VERSION ""

NS_ :

BS_:

BU_: VCM FAS EBS APM

BO_ 2671902706 TesterFuncDiagMsg_C03: 8 VCM
 SG_ FuncDiagDataTester_ISig_3 : 0|64@1+ (1,0) [0|0] ""  APM,FAS

BO_ 2671902708 TesterFuncDiagMsgF4_C03: 8 VCM
 SG_ FuncDiagDataIntTesterF4_ISig_3 : 0|64@1+ (1,0) [0|0] ""  FAS,APM

BO_ 2671833648 PhysDiagRespMsg_F2_30_C03: 8 FAS
 SG_ PhysDiagRespSig_F2_30_ISig_3 : 0|64@1+ (1,0) [0|0] ""  VCM

BO_ 2671833635 PhysDiagRespMsg_F2_23_C03: 8 APM
 SG_ PhysDiagRespSig_F2_23_ISig_3 : 0|64@1+ (1,0) [0|0] ""  VCM

BO_ 2671784178 PhysDiagReqMsg_30_F2_C03: 8 VCM
 SG_ PhysDiagReqSig_30_F2_ISig_3 : 0|64@1+ (1,0) [0|0] ""  FAS

BO_ 2671780850 PhysDiagReqMsg_23_F2_C03: 8 VCM
 SG_ PhysDiagReqSig_23_F2_ISig_3 : 0|64@1+ (1,0) [0|0] ""  APM

BO_ 2633990180 NmAsr_VCM_C03: 1 VCM

BO_ 2633990192 NmAsr_FAS_C03: 1 FAS

BO_ 2633990184 NmAsr_EBS_C03: 1 EBS

BO_ 2633990179 NmAsr_APM_C03: 1 APM

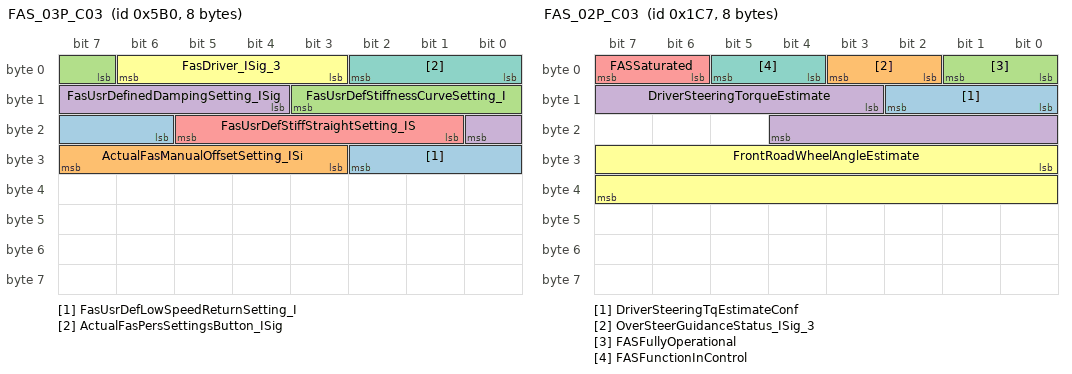
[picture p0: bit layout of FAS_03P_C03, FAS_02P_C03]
BO_ 1456 FAS_03P_C03: 8 FAS
 SG_ FasUsrDefLowSpeedReturnSetting_I : 22|5@1+ (1,-10) [-10|21] ""  VCM
 SG_ ActualFasManualOffsetSetting_ISi : 27|5@1+ (1,-10) [-10|21] ""  VCM
 SG_ FasUsrDefStiffnessCurveSetting_I : 7|5@1+ (1,-10) [-10|21] ""  VCM
 SG_ FasUsrDefinedDampingSetting_ISig : 12|5@1+ (1,-10) [-10|21] ""  VCM
 SG_ FasUsrDefStiffStraightSetting_IS : 17|5@1+ (1,-10) [-10|21] ""  VCM
 SG_ FasDriver_ISig_3 : 3|4@1+ (1,0) [0|0] ""  VCM
 SG_ ActualFasPersSettingsButton_ISig : 0|3@1+ (1,0) [0|0] ""  VCM

BO_ 455 FAS_02P_C03: 8 FAS
 SG_ DriverSteeringTqEstimateConf : 8|3@1+ (1,0) [0|0] ""  VCM
 SG_ OverSteerGuidanceStatus_ISig_3 : 2|2@1+ (1,0) [0|0] ""  VCM
 SG_ FASFullyOperational : 0|2@1+ (1,0) [0|0] ""  VCM
 SG_ DriverSteeringTorqueEstimate : 11|10@1+ (0.05,-25) [-25|26.15] "Nm"  VCM
 SG_ FASSaturated : 6|2@1+ (1,0) [0|0] ""  VCM
 SG_ FrontRoadWheelAngleEstimate : 24|16@1+ (5E-005,-1.6) [-1.6|1.67675] "rad"  VCM
 SG_ FASFunctionInControl : 4|2@1+ (1,0) [0|0] ""  VCM

BO_ 275 FAS_01P_C03: 16 FAS
 SG_ RoadWheelAngleResp_RateCap : 80|8@1+ (0.004,0) [0|1.02] "Rad_per_s"  VCM
 SG_ RoadWheelAngleResp_CRC : 48|8@1+ (1,0) [0|255] ""  VCM
 SG_ SteeringCtrlModeRsp_CRC : 24|8@1+ (1,0) [0|255] ""  VCM
 SG_ SteeringWheelTorque_SqC : 8|4@1+ (1,0) [0|14] "NotApplicable"  VCM
 SG_ SteeringWheelTorque_CRC : 0|8@1+ (1,0) [0|255] ""  VCM
 SG_ SteeringCtrlModeRsp_Status : 36|3@1+ (1,0) [0|0] ""  VCM
 SG_ SteeringCtrlModeRsp_SqC : 32|4@1+ (1,0) [0|14] "NotApplicable"  VCM
 SG_ RoadWheelAngleResp_Status : 64|16@1+ (5E-005,-1.6) [-1.6|1.67675] "rad"  VCM
 SG_ SteeringWheelTorque_Estimate : 14|10@1+ (0.05,-25) [-25|26.15] "Nm"  VCM
 SG_ SteeringCtrlModeRsp_Cap : 40|3@1+ (1,0) [0|0] ""  VCM
 SG_ RoadWheelAngleResp_MaxCap : 96|8@1+ (0.01,0) [0|2.55] "rad"  VCM
 SG_ SteeringCtrlModeRsp_Active : 43|2@1+ (1,0) [0|0] ""  VCM
 SG_ RoadWheelAngleResp_MinCap : 88|8@1+ (0.01,-1.6) [-1.6|0.95] "rad"  VCM
 SG_ RoadWheelAngleResp_SqC : 56|4@1+ (1,0) [0|14] "NotApplicable"  VCM

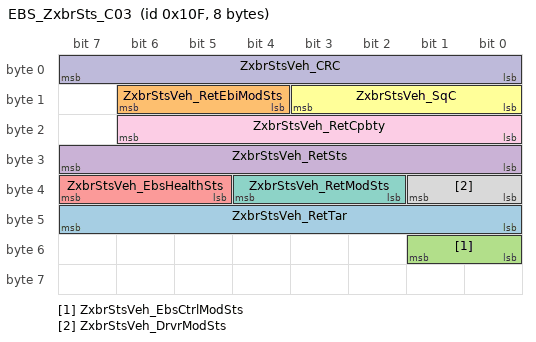
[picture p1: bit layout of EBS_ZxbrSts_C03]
BO_ 271 EBS_ZxbrSts_C03: 8 EBS
 SG_ ZxbrStsVeh_RetTar : 40|8@1+ (0.005,0) [0|1.275] "NotApplicable"  VCM
 SG_ ZxbrStsVeh_RetEbiModSts : 12|3@1+ (1,0) [0|0] ""  VCM
 SG_ ZxbrStsVeh_EbsCtrlModSts : 48|2@1+ (1,0) [0|0] ""  VCM
 SG_ ZxbrStsVeh_RetSts : 24|8@1+ (0.005,0) [0|1.275] "NotApplicable"  VCM
 SG_ ZxbrStsVeh_EbsHealthSts : 37|3@1+ (1,0) [0|0] ""  VCM
 SG_ ZxbrStsVeh_SqC : 8|4@1+ (1,0) [0|14] "NotApplicable"  VCM
 SG_ ZxbrStsVeh_RetModSts : 34|3@1+ (1,0) [0|0] ""  VCM
 SG_ ZxbrStsVeh_DrvrModSts : 32|2@1+ (1,0) [0|0] ""  VCM
 SG_ ZxbrStsVeh_RetCpbty : 16|7@1+ (0.01,0) [0|1.27] "NotApplicable"  VCM
 SG_ ZxbrStsVeh_CRC : 0|8@1+ (1,0) [0|255] ""  VCM

BO_ 304 EBS_Sts2Axles_C03: 64 EBS
 SG_ Sts2Axle2_WhlTqRi : 143|13@1+ (10,0) [0|81910] "Nm"  VCM
 SG_ Sts2Axle4_WhlTqQltyLe : 316|2@1+ (1,0) [0|0] ""  VCM
 SG_ Sts2Axle3_SqC : 176|8@1+ (1,0) [0|255] "Count"  VCM
 SG_ Sts2Axle6_WhlTqRi : 463|13@1+ (10,0) [0|81910] "Nm"  VCM
 SG_ Sts2Axle3_BrkTqReqRefLe : 184|13@1+ (10,0) [0|81910] "Nm"  VCM
 SG_ Sts2Axle2_WhlTqQltyRi : 158|2@1+ (1,0) [0|0] ""  VCM
 SG_ Sts2Axle1_SqC : 16|8@1+ (1,0) [0|255] "Count"  VCM
 SG_ Sts2Axle1_BrkTqReqRefLe : 24|13@1+ (10,0) [0|81910] "Nm"  VCM
 SG_ Sts2Axle2_WhlTqQltyLe : 156|2@1+ (1,0) [0|0] ""  VCM
 SG_ Sts2Axle4_BrkTqReqRefLe : 264|13@1+ (10,0) [0|81910] "Nm"  VCM
 SG_ Sts2Axle2_SqC : 96|8@1+ (1,0) [0|255] "Count"  VCM
 SG_ Sts2Axle4_CRC : 240|16@1+ (1,0) [0|65535] "NotApplicable"  VCM
 SG_ Sts2Axle3_WhlTqQltyLe : 236|2@1+ (1,0) [0|0] ""  VCM
 SG_ Sts2Axle1_WhlTqQltyRi : 78|2@1+ (1,0) [0|0] ""  VCM
 SG_ Sts2Axle1_WhlTqLe : 50|13@1+ (10,0) [0|81910] "Nm"  VCM
 SG_ Sts2Axle4_SqC : 256|8@1+ (1,0) [0|255] "Count"  VCM
 SG_ Sts2Axle4_WhlTqQltyRi : 318|2@1+ (1,0) [0|0] ""  VCM
 SG_ Sts2Axle3_BrkTqReqRefRi : 197|13@1+ (10,0) [0|81910] "Nm"  VCM
 SG_ Sts2Axle6_SqC : 416|8@1+ (1,0) [0|255] "Count"  VCM
 SG_ Sts2Axle6_CRC : 400|16@1+ (1,0) [0|65535] "NotApplicable"  VCM
 SG_ Sts2Axle5_BrkTqReqRefLe : 344|13@1+ (10,0) [0|81910] "Nm"  VCM
 SG_ Sts2Axle6_WhlTqQltyLe : 476|2@1+ (1,0) [0|0] ""  VCM
 SG_ Sts2Axle2_WhlTqLe : 130|13@1+ (10,0) [0|81910] "Nm"  VCM
 SG_ Sts2Axle5_WhlTqQltyRi : 398|2@1+ (1,0) [0|0] ""  VCM
 SG_ Sts2Axle3_CRC : 160|16@1+ (1,0) [0|65535] "NotApplicable"  VCM
 SG_ Sts2Axle6_BrkTqReqRefRi : 437|13@1+ (10,0) [0|81910] "Nm"  VCM
 SG_ Sts2Axle1_WhlTqRi : 63|13@1+ (10,0) [0|81910] "Nm"  VCM
 SG_ Sts2Axle4_BrkTqReqRefRi : 277|13@1+ (10,0) [0|81910] "Nm"  VCM
 SG_ Sts2Axle1_BrkTqReqRefRi : 37|13@1+ (10,0) [0|81910] "Nm"  VCM
 SG_ Sts2Axle2_BrkTqReqRefLe : 104|13@1+ (10,0) [0|81910] "Nm"  VCM
 SG_ Sts2Axle5_SqC : 336|8@1+ (1,0) [0|255] "Count"  VCM
 SG_ Sts2Axle3_WhlTqLe : 210|13@1+ (10,0) [0|81910] "Nm"  VCM
 SG_ Sts2Axle6_WhlTqQltyRi : 478|2@1+ (1,0) [0|0] ""  VCM
 SG_ Sts2Axle5_WhlTqRi : 383|13@1+ (10,0) [0|81910] "Nm"  VCM
 SG_ Sts2Axle5_WhlTqLe : 370|13@1+ (10,0) [0|81910] "Nm"  VCM
 SG_ Sts2Axle5_WhlTqQltyLe : 396|2@1+ (1,0) [0|0] ""  VCM
 SG_ Sts2Axle1_WhlTqQltyLe : 76|2@1+ (1,0) [0|0] ""  VCM
 SG_ Sts2Axle6_WhlTqLe : 450|13@1+ (10,0) [0|81910] "Nm"  VCM
 SG_ Sts2Axle4_WhlTqRi : 303|13@1+ (10,0) [0|81910] "Nm"  VCM
 SG_ Sts2Axle1_CRC : 0|16@1+ (1,0) [0|65535] "NotApplicable"  VCM
 SG_ Sts2Axle5_CRC : 320|16@1+ (1,0) [0|65535] "NotApplicable"  VCM
 SG_ Sts2Axle3_WhlTqRi : 223|13@1+ (10,0) [0|81910] "Nm"  VCM
 SG_ Sts2Axle6_BrkTqReqRefLe : 424|13@1+ (10,0) [0|81910] "Nm"  VCM
 SG_ Sts2Axle2_BrkTqReqRefRi : 117|13@1+ (10,0) [0|81910] "Nm"  VCM
 SG_ Sts2Axle2_CRC : 80|16@1+ (1,0) [0|65535] "NotApplicable"  VCM
 SG_ Sts2Axle3_WhlTqQltyRi : 238|2@1+ (1,0) [0|0] ""  VCM
 SG_ Sts2Axle4_WhlTqLe : 290|13@1+ (10,0) [0|81910] "Nm"  VCM
 SG_ Sts2Axle5_BrkTqReqRefRi : 357|13@1+ (10,0) [0|81910] "Nm"  VCM

BO_ 288 EBS_Sts1Axles_C03: 48 EBS
 SG_ Sts1Axle6_WhlRotQltyLe : 332|2@1+ (1,0) [0|0] ""  VCM
 SG_ Sts1Axle5_CRC : 256|8@1+ (1,0) [0|255] ""  VCM
 SG_ Sts1Axle2_WhlRotQltyRi : 78|2@1+ (1,0) [0|0] ""  VCM
 SG_ Sts1Axle2_WhlRotSpdRi : 104|15@1+ (0.01,-140) [-140|187.67] "Rad_per_s"  VCM
 SG_ Sts1Axle6_CRC : 320|8@1+ (1,0) [0|255] ""  VCM
 SG_ Sts1Axle5_WhlRotAgCntrRi : 311|9@1+ (1,0) [0|511] "Count"  VCM
 SG_ Sts1Axle3_CRC : 128|8@1+ (1,0) [0|255] ""  VCM
 SG_ Sts1Axle4_WhlRotSpdLe : 208|15@1+ (0.01,-140) [-140|187.67] "Rad_per_s"  VCM
 SG_ Sts1Axle4_WhlRotAgCntrLe : 223|9@1+ (1,0) [0|511] "Count"  VCM
 SG_ Sts1Axle6_WhlRotSpdRi : 360|15@1+ (0.01,-140) [-140|187.67] "Rad_per_s"  VCM
 SG_ Sts1Axle3_WhlRotAgCntrLe : 159|9@1+ (1,0) [0|511] "Count"  VCM
 SG_ Sts1Axle2_CRC : 64|8@1+ (1,0) [0|255] ""  VCM
 SG_ Sts1Axle1_WhlRotSpdRi : 40|15@1+ (0.01,-140) [-140|187.67] "Rad_per_s"  VCM
 SG_ Sts1Axle1_WhlRotQltyRi : 14|2@1+ (1,0) [0|0] ""  VCM
 SG_ Sts1Axle3_WhlRotQltyLe : 140|2@1+ (1,0) [0|0] ""  VCM
 SG_ Sts1Axle5_WhlRotAgCntrLe : 287|9@1+ (1,0) [0|511] "Count"  VCM
 SG_ Sts1Axle3_SqC : 136|4@1+ (1,0) [0|14] "NotApplicable"  VCM
 SG_ Sts1Axle4_SqC : 200|4@1+ (1,0) [0|14] "NotApplicable"  VCM
 SG_ Sts1Axle1_SqC : 8|4@1+ (1,0) [0|14] "NotApplicable"  VCM
 SG_ Sts1Axle5_SqC : 264|4@1+ (1,0) [0|14] "NotApplicable"  VCM
 SG_ Sts1Axle2_WhlRotSpdLe : 80|15@1+ (0.01,-140) [-140|187.67] "Rad_per_s"  VCM
 SG_ Sts1Axle1_WhlRotQltyLe : 12|2@1+ (1,0) [0|0] ""  VCM
 SG_ Sts1Axle3_WhlRotAgCntrRi : 183|9@1+ (1,0) [0|511] "Count"  VCM
 SG_ Sts1Axle1_WhlRotAgCntrLe : 31|9@1+ (1,0) [0|511] "Count"  VCM
 SG_ Sts1Axle1_CRC : 0|8@1+ (1,0) [0|255] ""  VCM
 SG_ Sts1Axle6_WhlRotAgCntrLe : 351|9@1+ (1,0) [0|511] "Count"  VCM
 SG_ Sts1Axle5_WhlRotQltyLe : 268|2@1+ (1,0) [0|0] ""  VCM
 SG_ Sts1Axle5_WhlRotQltyRi : 270|2@1+ (1,0) [0|0] ""  VCM
 SG_ Sts1Axle1_WhlRotSpdLe : 16|15@1+ (0.01,-140) [-140|187.67] "Rad_per_s"  VCM
 SG_ Sts1Axle2_WhlRotAgCntrRi : 119|9@1+ (1,0) [0|511] "Count"  VCM
 SG_ Sts1Axle4_WhlRotQltyRi : 206|2@1+ (1,0) [0|0] ""  VCM
 SG_ Sts1Axle2_WhlRotAgCntrLe : 95|9@1+ (1,0) [0|511] "Count"  VCM
 SG_ Sts1Axle3_WhlRotQltyRi : 142|2@1+ (1,0) [0|0] ""  VCM
 SG_ Sts1Axle6_WhlRotAgCntrRi : 375|9@1+ (1,0) [0|511] "Count"  VCM
 SG_ Sts1Axle5_WhlRotSpdRi : 296|15@1+ (0.01,-140) [-140|187.67] "Rad_per_s"  VCM
 SG_ Sts1Axle4_CRC : 192|8@1+ (1,0) [0|255] ""  VCM
 SG_ Sts1Axle1_WhlRotAgCntrRi : 55|9@1+ (1,0) [0|511] "Count"  VCM
 SG_ Sts1Axle5_WhlRotSpdLe : 272|15@1+ (0.01,-140) [-140|187.67] "Rad_per_s"  VCM
 SG_ Sts1Axle3_WhlRotSpdLe : 144|15@1+ (0.01,-140) [-140|187.67] "Rad_per_s"  VCM
 SG_ Sts1Axle4_WhlRotSpdRi : 232|15@1+ (0.01,-140) [-140|187.67] "Rad_per_s"  VCM
 SG_ Sts1Axle4_WhlRotQltyLe : 204|2@1+ (1,0) [0|0] ""  VCM
 SG_ Sts1Axle2_WhlRotQltyLe : 76|2@1+ (1,0) [0|0] ""  VCM
 SG_ Sts1Axle6_WhlRotSpdLe : 336|15@1+ (0.01,-140) [-140|187.67] "Rad_per_s"  VCM
 SG_ Sts1Axle4_WhlRotAgCntrRi : 247|9@1+ (1,0) [0|511] "Count"  VCM
 SG_ Sts1Axle6_WhlRotQltyRi : 334|2@1+ (1,0) [0|0] ""  VCM
 SG_ Sts1Axle2_SqC : 72|4@1+ (1,0) [0|14] "NotApplicable"  VCM
 SG_ Sts1Axle3_WhlRotSpdRi : 168|15@1+ (0.01,-140) [-140|187.67] "Rad_per_s"  VCM
 SG_ Sts1Axle6_SqC : 328|4@1+ (1,0) [0|14] "NotApplicable"  VCM

BO_ 602 EBS_IxbrStsVeh_C03: 16 EBS
 SG_ IxbrSts2Veh_CRC : 56|8@1+ (1,0) [0|255] ""  VCM
 SG_ IxbrSts1Veh_AbsSts : 45|3@1+ (1,0) [0|0] ""  VCM
 SG_ IxbrSts1Veh_IxbrModSts : 12|3@1+ (1,0) [0|0] ""  VCM
 SG_ IxbrSts2Veh_SqC : 64|4@1+ (1,0) [0|14] "NotApplicable"  VCM
 SG_ IxbrSts1Veh_VehSpdLimRsc : 16|13@1+ (0.01,-40) [-40|41.91] "m_per_s"  VCM
 SG_ IxbrSts2Veh_YawRateRefEsc : 68|12@1+ (0.001,-2) [-2|2.095] "Rad_per_s"  VCM
 SG_ IxbrSts2Veh_VehAccnLatLimNeg : 96|9@1+ (0.01,-5) [-5|0.11] "m_per_s_squared"  VCM
 SG_ IxbrSts1Veh_VehSpdLgt : 32|13@1+ (0.01,-40) [-40|41.91] "m_per_s"  VCM
 SG_ IxbrSts1Veh_EscSts : 29|3@1+ (1,0) [0|0] ""  VCM
 SG_ IxbrSts2Veh_YawRateOffsLim : 80|12@1+ (0.001,-2) [-2|2.095] "Rad_per_s"  VCM
 SG_ IxbrSts1Veh_TscSts : 48|3@1+ (1,0) [0|0] ""  VCM
 SG_ IxbrSts1Veh_CRC : 0|8@1+ (1,0) [0|255] ""  VCM
 SG_ IxbrSts2Veh_VehAccnLatLimPos : 111|9@1+ (0.01,0) [0|5.11] "m_per_s_squared"  VCM
 SG_ IxbrSts1Veh_SqC : 8|4@1+ (1,0) [0|14] "NotApplicable"  VCM
 SG_ IxbrSts1Veh_RscSts : 51|3@1+ (1,0) [0|0] ""  VCM

BO_ 598 EBS_IxbrStsAx456_C03: 64 EBS
 SG_ IxbrSts3Ax5_WhlAccnLgtLimMinLe : 279|9@1+ (0.05,-20) [-20|5.55] "Rad_per_s_squared"  VCM
 SG_ IxbrSts3Ax5_CRC : 240|8@1+ (1,0) [0|255] ""  VCM
 SG_ IxbrSts3Ax5_SqC : 248|4@1+ (1,0) [0|14] "NotApplicable"  VCM
 SG_ IxbrSts1Ax6_CRC : 304|8@1+ (1,0) [0|255] ""  VCM
 SG_ IxbrSts2Ax6_WhlSlipLimPrpnRi : 384|8@1+ (0.005,0) [0|1.275] "NotApplicable"  VCM
 SG_ IxbrSts2Ax6_WhlSlipLimBrkngLe : 360|8@1+ (0.005,-1) [-1|0.275] "NotApplicable"  VCM
 SG_ IxbrSts3Ax6_WhlAccnLgtLimMaxRi : 416|9@1+ (0.05,0) [0|25.55] "Rad_per_s_squared"  VCM
 SG_ IxbrSts1Ax4_WhlRdEstmdLe : 30|10@1+ (0.001,0.35) [0.35|1.373] "m"  VCM
 SG_ IxbrSts2Ax5_WhlSlipLimBrkngLe : 208|8@1+ (0.005,-1) [-1|0.275] "NotApplicable"  VCM
 SG_ IxbrSts2Ax6_WhlSlipLimBrkngRi : 368|8@1+ (0.005,-1) [-1|0.275] "NotApplicable"  VCM
 SG_ IxbrSts2Ax4_SqC : 48|4@1+ (1,0) [0|14] "NotApplicable"  VCM
 SG_ IxbrSts3Ax4_CRC : 88|8@1+ (1,0) [0|255] ""  VCM
 SG_ IxbrSts2Ax4_WhlSlipLimBrkngRi : 64|8@1+ (0.005,-1) [-1|0.275] "NotApplicable"  VCM
 SG_ IxbrSts2Ax4_WhlSlipLimBrkngLe : 56|8@1+ (0.005,-1) [-1|0.275] "NotApplicable"  VCM
 SG_ IxbrSts2Ax6_CRC : 344|8@1+ (1,0) [0|255] ""  VCM
 SG_ IxbrSts2Ax4_CRC : 40|8@1+ (1,0) [0|255] ""  VCM
 SG_ IxbrSts3Ax4_WhlAccnLgtLimMinLe : 127|9@1+ (0.05,-20) [-20|5.55] "Rad_per_s_squared"  VCM
 SG_ IxbrSts3Ax6_CRC : 392|8@1+ (1,0) [0|255] ""  VCM
 SG_ IxbrSts1Ax4_SqC : 8|4@1+ (1,0) [0|14] "NotApplicable"  VCM
 SG_ IxbrSts1Ax6_SqC : 312|4@1+ (1,0) [0|14] "NotApplicable"  VCM
 SG_ IxbrSts3Ax5_WhlAccnLgtLimMinRi : 288|9@1+ (0.05,-20) [-20|5.55] "Rad_per_s_squared"  VCM
 SG_ IxbrSts2Ax6_WhlSlipLimPrpnLe : 376|8@1+ (0.005,0) [0|1.275] "NotApplicable"  VCM
 SG_ IxbrSts2Ax5_SqC : 200|4@1+ (1,0) [0|14] "NotApplicable"  VCM
 SG_ IxbrSts3Ax6_SqC : 400|4@1+ (1,0) [0|14] "NotApplicable"  VCM
 SG_ IxbrSts2Ax5_WhlSlipLimBrkngRi : 216|8@1+ (0.005,-1) [-1|0.275] "NotApplicable"  VCM
 SG_ IxbrSts1Ax5_CRC : 152|8@1+ (1,0) [0|255] ""  VCM
 SG_ IxbrSts3Ax5_WhlAccnLgtLimMaxRi : 264|9@1+ (0.05,0) [0|25.55] "Rad_per_s_squared"  VCM
 SG_ IxbrSts1Ax6_WhlRdEstmdLe : 334|10@1+ (0.001,0.35) [0.35|1.373] "m"  VCM
 SG_ IxbrSts3Ax6_WhlAccnLgtLimMinLe : 431|9@1+ (0.05,-20) [-20|5.55] "Rad_per_s_squared"  VCM
 SG_ IxbrSts2Ax5_WhlSlipLimPrpnRi : 232|8@1+ (0.005,0) [0|1.275] "NotApplicable"  VCM
 SG_ IxbrSts2Ax6_SqC : 352|4@1+ (1,0) [0|14] "NotApplicable"  VCM
 SG_ IxbrSts3Ax4_WhlAccnLgtLimMinRi : 136|9@1+ (0.05,-20) [-20|5.55] "Rad_per_s_squared"  VCM
 SG_ IxbrSts1Ax5_SqC : 160|4@1+ (1,0) [0|14] "NotApplicable"  VCM
 SG_ IxbrSts3Ax6_WhlAccnLgtLimMinRi : 440|9@1+ (0.05,-20) [-20|5.55] "Rad_per_s_squared"  VCM
 SG_ IxbrSts2Ax5_CRC : 192|8@1+ (1,0) [0|255] ""  VCM
 SG_ IxbrSts3Ax4_SqC : 96|4@1+ (1,0) [0|14] "NotApplicable"  VCM
 SG_ IxbrSts3Ax6_WhlAccnLgtLimMaxLe : 407|9@1+ (0.05,0) [0|25.55] "Rad_per_s_squared"  VCM
 SG_ IxbrSts3Ax4_WhlAccnLgtLimMaxLe : 103|9@1+ (0.05,0) [0|25.55] "Rad_per_s_squared"  VCM
 SG_ IxbrSts1Ax6_WhlRdEstmdRi : 320|10@1+ (0.001,0.35) [0.35|1.373] "m"  VCM
 SG_ IxbrSts1Ax4_WhlRdEstmdRi : 16|10@1+ (0.001,0.35) [0.35|1.373] "m"  VCM
 SG_ IxbrSts3Ax4_WhlAccnLgtLimMaxRi : 112|9@1+ (0.05,0) [0|25.55] "Rad_per_s_squared"  VCM
 SG_ IxbrSts2Ax4_WhlSlipLimPrpnRi : 80|8@1+ (0.005,0) [0|1.275] "NotApplicable"  VCM
 SG_ IxbrSts1Ax5_WhlRdEstmdLe : 182|10@1+ (0.001,0.35) [0.35|1.373] "m"  VCM
 SG_ IxbrSts2Ax4_WhlSlipLimPrpnLe : 72|8@1+ (0.005,0) [0|1.275] "NotApplicable"  VCM
 SG_ IxbrSts3Ax5_WhlAccnLgtLimMaxLe : 255|9@1+ (0.05,0) [0|25.55] "Rad_per_s_squared"  VCM
 SG_ IxbrSts2Ax5_WhlSlipLimPrpnLe : 224|8@1+ (0.005,0) [0|1.275] "NotApplicable"  VCM
 SG_ IxbrSts1Ax4_CRC : 0|8@1+ (1,0) [0|255] ""  VCM
 SG_ IxbrSts1Ax5_WhlRdEstmdRi : 168|10@1+ (0.001,0.35) [0.35|1.373] "m"  VCM

BO_ 596 EBS_IxbrStsAx123_C03: 64 EBS
 SG_ IxbrSts1Ax1_WhlRdEstmdRi : 16|10@1+ (0.001,0.35) [0.35|1.373] "m"  VCM
 SG_ IxbrSts3Ax3_WhlAccnLgtLimMaxLe : 407|9@1+ (0.05,0) [0|25.55] "Rad_per_s_squared"  VCM
 SG_ IxbrSts3Ax1_WhlAccnLgtLimMinRi : 136|9@1+ (0.05,-20) [-20|5.55] "Rad_per_s_squared"  VCM
 SG_ IxbrSts3Ax3_CRC : 392|8@1+ (1,0) [0|255] ""  VCM
 SG_ IxbrSts2Ax3_WhlSlipLimBrkngRi : 368|8@1+ (0.005,-1) [-1|0.275] "NotApplicable"  VCM
 SG_ IxbrSts3Ax1_CRC : 88|8@1+ (1,0) [0|255] ""  VCM
 SG_ IxbrSts2Ax3_WhlSlipLimPrpnRi : 384|8@1+ (0.005,0) [0|1.275] "NotApplicable"  VCM
 SG_ IxbrSts2Ax1_WhlSlipLimPrpnLe : 72|8@1+ (0.005,0) [0|1.275] "NotApplicable"  VCM
 SG_ IxbrSts3Ax3_WhlAccnLgtLimMinLe : 431|9@1+ (0.05,-20) [-20|5.55] "Rad_per_s_squared"  VCM
 SG_ IxbrSts1Ax1_SqC : 8|4@1+ (1,0) [0|14] "NotApplicable"  VCM
 SG_ IxbrSts2Ax3_CRC : 344|8@1+ (1,0) [0|255] ""  VCM
 SG_ IxbrSts1Ax2_WhlRdEstmdLe : 182|10@1+ (0.001,0.35) [0.35|1.373] "m"  VCM
 SG_ IxbrSts1Ax1_CRC : 0|8@1+ (1,0) [0|255] ""  VCM
 SG_ IxbrSts1Ax3_SqC : 312|4@1+ (1,0) [0|14] "NotApplicable"  VCM
 SG_ IxbrSts1Ax3_WhlRdEstmdLe : 334|10@1+ (0.001,0.35) [0.35|1.373] "m"  VCM
 SG_ IxbrSts2Ax2_CRC : 192|8@1+ (1,0) [0|255] ""  VCM
 SG_ IxbrSts2Ax2_WhlSlipLimBrkngRi : 216|8@1+ (0.005,-1) [-1|0.275] "NotApplicable"  VCM
 SG_ IxbrSts2Ax1_WhlSlipLimPrpnRi : 80|8@1+ (0.005,0) [0|1.275] "NotApplicable"  VCM
 SG_ IxbrSts3Ax1_WhlAccnLgtLimMinLe : 127|9@1+ (0.05,-20) [-20|5.55] "Rad_per_s_squared"  VCM
 SG_ IxbrSts3Ax2_WhlAccnLgtLimMaxRi : 264|9@1+ (0.05,0) [0|25.55] "Rad_per_s_squared"  VCM
 SG_ IxbrSts3Ax2_WhlAccnLgtLimMinLe : 279|9@1+ (0.05,-20) [-20|5.55] "Rad_per_s_squared"  VCM
 SG_ IxbrSts2Ax2_WhlSlipLimBrkngLe : 208|8@1+ (0.005,-1) [-1|0.275] "NotApplicable"  VCM
 SG_ IxbrSts3Ax1_WhlAccnLgtLimMaxLe : 103|9@1+ (0.05,0) [0|25.55] "Rad_per_s_squared"  VCM
 SG_ IxbrSts1Ax1_WhlRdEstmdLe : 30|10@1+ (0.001,0.35) [0.35|1.373] "m"  VCM
 SG_ IxbrSts2Ax1_WhlSlipLimBrkngLe : 56|8@1+ (0.005,-1) [-1|0.275] "NotApplicable"  VCM
 SG_ IxbrSts3Ax3_SqC : 400|4@1+ (1,0) [0|14] "NotApplicable"  VCM
 SG_ IxbrSts3Ax1_SqC : 96|4@1+ (1,0) [0|14] "NotApplicable"  VCM
 SG_ IxbrSts3Ax1_WhlAccnLgtLimMaxRi : 112|9@1+ (0.05,0) [0|25.55] "Rad_per_s_squared"  VCM
 SG_ IxbrSts2Ax3_SqC : 352|4@1+ (1,0) [0|14] "NotApplicable"  VCM
 SG_ IxbrSts1Ax2_CRC : 152|8@1+ (1,0) [0|255] ""  VCM
 SG_ IxbrSts1Ax3_CRC : 304|8@1+ (1,0) [0|255] ""  VCM
 SG_ IxbrSts2Ax1_SqC : 48|4@1+ (1,0) [0|14] "NotApplicable"  VCM
 SG_ IxbrSts3Ax3_WhlAccnLgtLimMinRi : 440|9@1+ (0.05,-20) [-20|5.55] "Rad_per_s_squared"  VCM
 SG_ IxbrSts3Ax2_SqC : 248|4@1+ (1,0) [0|14] "NotApplicable"  VCM
 SG_ IxbrSts1Ax2_WhlRdEstmdRi : 168|10@1+ (0.001,0.35) [0.35|1.373] "m"  VCM
 SG_ IxbrSts1Ax2_SqC : 160|4@1+ (1,0) [0|14] "NotApplicable"  VCM
 SG_ IxbrSts2Ax3_WhlSlipLimBrkngLe : 360|8@1+ (0.005,-1) [-1|0.275] "NotApplicable"  VCM
 SG_ IxbrSts3Ax2_WhlAccnLgtLimMinRi : 288|9@1+ (0.05,-20) [-20|5.55] "Rad_per_s_squared"  VCM
 SG_ IxbrSts3Ax2_CRC : 240|8@1+ (1,0) [0|255] ""  VCM
 SG_ IxbrSts2Ax3_WhlSlipLimPrpnLe : 376|8@1+ (0.005,0) [0|1.275] "NotApplicable"  VCM
 SG_ IxbrSts2Ax2_WhlSlipLimPrpnLe : 224|8@1+ (0.005,0) [0|1.275] "NotApplicable"  VCM
 SG_ IxbrSts2Ax1_CRC : 40|8@1+ (1,0) [0|255] ""  VCM
 SG_ IxbrSts3Ax2_WhlAccnLgtLimMaxLe : 255|9@1+ (0.05,0) [0|25.55] "Rad_per_s_squared"  VCM
 SG_ IxbrSts3Ax3_WhlAccnLgtLimMaxRi : 416|9@1+ (0.05,0) [0|25.55] "Rad_per_s_squared"  VCM
 SG_ IxbrSts1Ax3_WhlRdEstmdRi : 320|10@1+ (0.001,0.35) [0.35|1.373] "m"  VCM
 SG_ IxbrSts2Ax1_WhlSlipLimBrkngRi : 64|8@1+ (0.005,-1) [-1|0.275] "NotApplicable"  VCM
 SG_ IxbrSts2Ax2_SqC : 200|4@1+ (1,0) [0|14] "NotApplicable"  VCM
 SG_ IxbrSts2Ax2_WhlSlipLimPrpnRi : 232|8@1+ (0.005,0) [0|1.275] "NotApplicable"  VCM

BO_ 298 EBS_ImuSts_C03: 16 EBS
 SG_ Imu_LgtAccnQlty : 122|2@1+ (1,0) [0|0] ""  VCM
 SG_ Imu_AccnLat : 48|16@1+ (0.004882813,-156.875) [-156.875|163.120149955] "m_per_s_squared"  VCM
 SG_ Imu_PitchRate : 96|16@1+ (0.000175,-5.6224) [-5.6224|5.846225] "NotApplicable"  VCM
 SG_ Imu_YawRate : 16|16@1+ (0.000175,-5.6224) [-5.6224|5.846225] "NotApplicable"  VCM
 SG_ Imu_Temp : 112|8@1+ (1,-50) [-50|205] "DegreeC"  VCM
 SG_ Imu_RollRate : 80|16@1+ (0.000175,-5.6224) [-5.6224|5.846225] "NotApplicable"  VCM
 SG_ Imu_YawRateQlty : 14|2@1+ (1,0) [0|0] ""  VCM
 SG_ Imu_PitchRateQlty : 124|2@1+ (1,0) [0|0] ""  VCM
 SG_ Imu_RollRateQlty : 126|2@1+ (1,0) [0|0] ""  VCM
 SG_ Imu_LgtAccn : 64|16@1+ (0.004882813,-156.875) [-156.875|163.120149955] "m_per_s_squared"  VCM
 SG_ Imu_SqC : 8|4@1+ (1,0) [0|14] "NotApplicable"  VCM
 SG_ Imu_CRC : 0|8@1+ (1,0) [0|255] ""  VCM
 SG_ Imu_AccnLatQlty : 12|2@1+ (1,0) [0|0] ""  VCM
 SG_ Imu_AccnVertQlty : 120|2@1+ (1,0) [0|0] ""  VCM
 SG_ Imu_AccnVert : 32|16@1+ (0.004882813,-156.875) [-156.875|163.120149955] "m_per_s_squared"  VCM

BO_ 594 EBS_CpbtyAxle456_C03: 64 EBS
 SG_ CpbtyAxle5_BrkEgyCpctyLe : 288|8@1+ (150,0) [0|38250] "NotApplicable"  VCM
 SG_ CpbtyAxle4_TqCpbtyRateQltyLe : 132|2@1+ (1,0) [0|0] ""  VCM
 SG_ CpbtyAxle4_TqCpbtyRateDecRi : 64|8@1+ (1000,0) [0|255000] "NotApplicable"  VCM
 SG_ CpbtyAxle4_BrkEgyCpctyQltyRi : 38|2@1+ (1,0) [0|0] ""  VCM
 SG_ CpbtyAxle4_TqCpbtyMinRi : 100|10@1+ (50,0) [0|51150] "Nm"  VCM
 SG_ CpbtyAxle5_TqCpbtyMaxLe : 262|10@1+ (50,0) [0|51150] "Nm"  VCM
 SG_ CpbtyAxle5_TqCpbtyQltyLe : 250|2@1+ (1,0) [0|0] ""  VCM
 SG_ CpbtyAxle5_PadWearRi : 232|8@1+ (0.5,0) [0|127.5] "Percent"  VCM
 SG_ CpbtyAxle5_TqCpbtyRateIncLeRi : 200|8@1+ (1000,0) [0|255000] "NotApplicable"  VCM
 SG_ CpbtyAxle6_TqCpbtyRateQltyLe : 436|2@1+ (1,0) [0|0] ""  VCM
 SG_ CpbtyAxle5_TqCpbtyRateDecLe : 192|8@1+ (1000,0) [0|255000] "NotApplicable"  VCM
 SG_ CpbtyAxle6_TqCpbtyMinRi : 404|10@1+ (50,0) [0|51150] "Nm"  VCM
 SG_ CpbtyAxle6_BrkEgyCpctyRi : 328|8@1+ (150,0) [0|38250] "NotApplicable"  VCM
 SG_ CpbtyAxle6_TqCpbtyRateQltyRi : 438|2@1+ (1,0) [0|0] ""  VCM
 SG_ CpbtyAxle6_TqCpbtyRateIncLeRi : 352|8@1+ (1000,0) [0|255000] "NotApplicable"  VCM
 SG_ CpbtyAxle5_TqCpbtyMaxRi : 274|10@1+ (50,0) [0|51150] "Nm"  VCM
 SG_ CpbtyAxle5_CRC : 152|16@1+ (1,0) [0|65535] "NotApplicable"  VCM
 SG_ CpbtyAxle6_TqCpbtyRateDecLe : 344|8@1+ (1000,0) [0|255000] "NotApplicable"  VCM
 SG_ CpbtyAxle5_SlipCtrlEna : 296|2@1+ (1,0) [0|0] ""  VCM
 SG_ CpbtyAxle5_PadWearQltyLe : 184|2@1+ (1,0) [0|0] ""  VCM
 SG_ CpbtyAxle6_BrkEgyCpctyQltyRi : 342|2@1+ (1,0) [0|0] ""  VCM
 SG_ CpbtyAxle5_BrkEgyCpctyQltyLe : 188|2@1+ (1,0) [0|0] ""  VCM
 SG_ CpbtyAxle6_PadWearQltyRi : 338|2@1+ (1,0) [0|0] ""  VCM
 SG_ CpbtyAxle6_TqCpbtyMaxRi : 426|10@1+ (50,0) [0|51150] "Nm"  VCM
 SG_ CpbtyAxle4_TqCpbtyQltyLe : 98|2@1+ (1,0) [0|0] ""  VCM
 SG_ CpbtyAxle4_SlipCtrlEna : 144|2@1+ (1,0) [0|0] ""  VCM
 SG_ CpbtyAxle4_BrkEgyCpctyRi : 24|8@1+ (150,0) [0|38250] "NotApplicable"  VCM
 SG_ CpbtyAxle6_TqCpbtyQltyRi : 424|2@1+ (1,0) [0|0] ""  VCM
 SG_ CpbtyAxle6_CRC : 304|16@1+ (1,0) [0|65535] "NotApplicable"  VCM
 SG_ CpbtyAxle5_TqCpbtyRateQltyLe : 284|2@1+ (1,0) [0|0] ""  VCM
 SG_ CpbtyAxle4_TqCpbtyMaxLe : 110|10@1+ (50,0) [0|51150] "Nm"  VCM
 SG_ CpbtyAxle4_PadWearRi : 80|8@1+ (0.5,0) [0|127.5] "Percent"  VCM
 SG_ CpbtyAxle6_TqCpbtyMinLe : 392|10@1+ (50,0) [0|51150] "Nm"  VCM
 SG_ CpbtyAxle4_CRC : 0|16@1+ (1,0) [0|65535] "NotApplicable"  VCM
 SG_ CpbtyAxle4_SqC : 16|8@1+ (1,0) [0|255] "Count"  VCM
 SG_ CpbtyAxle5_TqCpbtyMinLe : 240|10@1+ (50,0) [0|51150] "Nm"  VCM
 SG_ CpbtyAxle6_PadWearQltyLe : 336|2@1+ (1,0) [0|0] ""  VCM
 SG_ CpbtyAxle6_PadWearRi : 384|8@1+ (0.5,0) [0|127.5] "Percent"  VCM
 SG_ CpbtyAxle5_TqCpbtyRateQltyRi : 286|2@1+ (1,0) [0|0] ""  VCM
 SG_ CpbtyAxle4_TqCpbtyQltyRi : 120|2@1+ (1,0) [0|0] ""  VCM
 SG_ CpbtyAxle6_SlipCtrlEna : 448|2@1+ (1,0) [0|0] ""  VCM
 SG_ CpbtyAxle5_TqCpbtyQltyRi : 272|2@1+ (1,0) [0|0] ""  VCM
 SG_ CpbtyAxle4_BrkEgyCpctyQltyLe : 36|2@1+ (1,0) [0|0] ""  VCM
 SG_ CpbtyAxle4_TqCpbtyMinLe : 88|10@1+ (50,0) [0|51150] "Nm"  VCM
 SG_ CpbtyAxle5_TqCpbtyMinRi : 252|10@1+ (50,0) [0|51150] "Nm"  VCM
 SG_ CpbtyAxle6_SqC : 320|8@1+ (1,0) [0|255] "Count"  VCM
 SG_ CpbtyAxle6_TqCpbtyRateDecRi : 368|8@1+ (1000,0) [0|255000] "NotApplicable"  VCM
 SG_ CpbtyAxle6_TqCpbtyRateIncLeLe : 360|8@1+ (1000,0) [0|255000] "NotApplicable"  VCM
 SG_ CpbtyAxle4_TqCpbtyRateDecLe : 40|8@1+ (1000,0) [0|255000] "NotApplicable"  VCM
 SG_ CpbtyAxle4_TqCpbtyRateQltyRi : 134|2@1+ (1,0) [0|0] ""  VCM
 SG_ CpbtyAxle4_BrkEgyCpctyLe : 136|8@1+ (150,0) [0|38250] "NotApplicable"  VCM
 SG_ CpbtyAxle4_TqCpbtyMaxRi : 122|10@1+ (50,0) [0|51150] "Nm"  VCM
 SG_ CpbtyAxle6_TqCpbtyMaxLe : 414|10@1+ (50,0) [0|51150] "Nm"  VCM
 SG_ CpbtyAxle5_TqCpbtyRateIncLeLe : 208|8@1+ (1000,0) [0|255000] "NotApplicable"  VCM
 SG_ CpbtyAxle5_PadWearQltyRi : 186|2@1+ (1,0) [0|0] ""  VCM
 SG_ CpbtyAxle6_BrkEgyCpctyQltyLe : 340|2@1+ (1,0) [0|0] ""  VCM
 SG_ CpbtyAxle5_TqCpbtyRateDecRi : 216|8@1+ (1000,0) [0|255000] "NotApplicable"  VCM
 SG_ CpbtyAxle6_TqCpbtyQltyLe : 402|2@1+ (1,0) [0|0] ""  VCM
 SG_ CpbtyAxle5_SqC : 168|8@1+ (1,0) [0|255] "Count"  VCM
 SG_ CpbtyAxle4_TqCpbtyRateIncLeRi : 48|8@1+ (1000,0) [0|255000] "NotApplicable"  VCM
 SG_ CpbtyAxle6_BrkEgyCpctyLe : 440|8@1+ (150,0) [0|38250] "NotApplicable"  VCM
 SG_ CpbtyAxle5_BrkEgyCpctyRi : 176|8@1+ (150,0) [0|38250] "NotApplicable"  VCM
 SG_ CpbtyAxle5_BrkEgyCpctyQltyRi : 190|2@1+ (1,0) [0|0] ""  VCM
 SG_ CpbtyAxle6_PadWearLe : 376|8@1+ (0.5,0) [0|127.5] "Percent"  VCM
 SG_ CpbtyAxle4_PadWearLe : 72|8@1+ (0.5,0) [0|127.5] "Percent"  VCM
 SG_ CpbtyAxle4_PadWearQltyRi : 34|2@1+ (1,0) [0|0] ""  VCM
 SG_ CpbtyAxle4_TqCpbtyRateIncLeLe : 56|8@1+ (1000,0) [0|255000] "NotApplicable"  VCM
 SG_ CpbtyAxle5_PadWearLe : 224|8@1+ (0.5,0) [0|127.5] "Percent"  VCM
 SG_ CpbtyAxle4_PadWearQltyLe : 32|2@1+ (1,0) [0|0] ""  VCM

BA_DEF_ BO_  "GenMsgStartDelayTime" INT 0 0;
BA_DEF_ BO_  "GenMsgDelayTime" INT 0 0;
BA_DEF_ BO_  "GenMsgCycleTime" INT 0 0;
BA_DEF_ BO_  "GenMsgSendType" ENUM  "Cyclic","NotUsed","NotUsed","NotUsed","NotUsed","NotUsed","NotUsed","IfActive","NoMsgSendType","NotUsed";
BA_DEF_ SG_  "GenSigStartValue" INT 0 0;
BA_DEF_ SG_  "GenSigCycleTimeActive" INT 0 0;
BA_DEF_ SG_  "GenSigCycleTime" INT 0 0;
BA_DEF_ SG_  "GenSigSendType" ENUM  "Cyclic","OnWrite","OnWriteWithRepetition","OnChange","OnChangeWithRepetition","IfActive","IfActiveWithRepetition","NoSigSendType","NotUsed","NotUsed","NotUsed","NotUsed","NotUsed";
BA_DEF_ BO_  "VFrameFormat" ENUM  "StandardCAN","ExtendedCAN","reserved","J1939PG","reserved","reserved","reserved","reserved","reserved","reserved","reserved","reserved","reserved","reserved","StandardCAN_FD","ExtendedCAN_FD";
BA_DEF_ SG_  "SigType" ENUM  "Default","Range","RangeSigned","ASCII","Discrete","Control","ReferencePGN","DTC","StringDelimiter","StringLength","StringLengthControl";
BA_DEF_ BO_  "NmAsrMessage" ENUM  "No","Yes";
BA_DEF_ SG_  "NeedsUpdateBit" ENUM  "No","Yes";
BA_DEF_ SG_  "MmAnSignal" ENUM  "No","Yes";
BA_DEF_ SG_  "GenSigMaxLatency" INT 0 65535;
BA_DEF_ SG_  "GenSigILSupport" ENUM  "Yes","No";
BA_DEF_ BO_  "GenMsgILSupport" ENUM  "No","Yes";
BA_DEF_ SG_  "E2EProfile" STRING ;
BA_DEF_ SG_  "E2EDataLength" INT 0 65535;
BA_DEF_ SG_  "E2EDataId" INT 0 65535;
BA_DEF_ BO_  "DiagUUDTResponse" ENUM  "No","Yes";
BA_DEF_ BO_  "DiagState" ENUM  "No","Yes";
BA_DEF_ BO_  "DiagResponse" ENUM  "No","Yes";
BA_DEF_ BO_  "DiagRequest" ENUM  "No","Yes";
BA_DEF_ BO_  "DiagConnection" HEX 0 65535;
BA_DEF_ BO_  "CanTpFcFrameId" HEX 0 2147483647;
BA_DEF_ BO_  "CanTpBs" INT 0 255;
BA_DEF_ BO_  "CANFD_BRS" ENUM  "0","1";
BA_DEF_ SG_  "SystemSignalLongSymbol" STRING ;
BA_DEF_REL_ BU_SG_REL_  "GenSigTimeoutTime" INT 0 65535;
BA_DEF_REL_ BU_SG_REL_  "GenSigFirstTimeoutTime" INT 0 65535;
BA_DEF_DEF_  "GenMsgStartDelayTime" 0;
BA_DEF_DEF_  "GenMsgDelayTime" 0;
BA_DEF_DEF_  "GenMsgCycleTime" 0;
BA_DEF_DEF_  "GenMsgSendType" "Cyclic";
BA_DEF_DEF_  "GenSigStartValue" 0;
BA_DEF_DEF_  "GenSigCycleTimeActive" 0;
BA_DEF_DEF_  "GenSigCycleTime" 0;
BA_DEF_DEF_  "GenSigSendType" "Cyclic";
BA_DEF_DEF_  "VFrameFormat" "ExtendedCAN";
BA_DEF_DEF_  "SigType" "Default";
BA_DEF_DEF_  "NmAsrMessage" "No";
BA_DEF_DEF_  "NeedsUpdateBit" "No";
BA_DEF_DEF_  "MmAnSignal" "No";
BA_DEF_DEF_  "GenSigMaxLatency" 0;
BA_DEF_DEF_  "GenSigILSupport" "Yes";
BA_DEF_DEF_  "GenMsgILSupport" "Yes";
BA_DEF_DEF_  "E2EProfile" "none";
BA_DEF_DEF_  "E2EDataLength" 0;
BA_DEF_DEF_  "E2EDataId" 0;
BA_DEF_DEF_  "DiagUUDTResponse" "No";
BA_DEF_DEF_  "DiagState" "No";
BA_DEF_DEF_  "DiagResponse" "No";
BA_DEF_DEF_  "DiagRequest" "No";
BA_DEF_DEF_  "DiagConnection" 0;
BA_DEF_DEF_  "CanTpFcFrameId" 2147483647;
BA_DEF_DEF_  "CanTpBs" 255;
BA_DEF_DEF_  "CANFD_BRS" "0";
BA_DEF_DEF_REL_ "GenSigTimeoutTime" 0;
BA_DEF_DEF_REL_ "GenSigFirstTimeoutTime" 0;
BA_DEF_DEF_  "SystemSignalLongSymbol" "";
BA_ "DiagConnection" BO_ 2671902706 62000;
BA_ "DiagState" BO_ 2671902706 1;
BA_ "GenMsgILSupport" BO_ 2671902706 0;
BA_ "GenMsgSendType" BO_ 2671902706 8;
BA_ "DiagConnection" BO_ 2671902708 62719;
BA_ "DiagState" BO_ 2671902708 1;
BA_ "GenMsgILSupport" BO_ 2671902708 0;
BA_ "GenMsgSendType" BO_ 2671902708 8;
BA_ "DiagConnection" BO_ 2671833648 62000;
BA_ "DiagResponse" BO_ 2671833648 1;
BA_ "GenMsgILSupport" BO_ 2671833648 0;
BA_ "GenMsgSendType" BO_ 2671833648 8;
BA_ "DiagConnection" BO_ 2671833635 61987;
BA_ "DiagResponse" BO_ 2671833635 1;
BA_ "GenMsgILSupport" BO_ 2671833635 0;
BA_ "GenMsgSendType" BO_ 2671833635 8;
BA_ "DiagConnection" BO_ 2671784178 62000;
BA_ "DiagRequest" BO_ 2671784178 1;
BA_ "GenMsgILSupport" BO_ 2671784178 0;
BA_ "GenMsgSendType" BO_ 2671784178 8;
BA_ "DiagConnection" BO_ 2671780850 61987;
BA_ "DiagRequest" BO_ 2671780850 1;
BA_ "GenMsgILSupport" BO_ 2671780850 0;
BA_ "GenMsgSendType" BO_ 2671780850 8;
BA_ "CANFD_BRS" BO_ 2633990180 1;
BA_ "GenMsgILSupport" BO_ 2633990180 0;
BA_ "NmAsrMessage" BO_ 2633990180 1;
BA_ "GenMsgSendType" BO_ 2633990180 8;
BA_ "VFrameFormat" BO_ 2633990180 15;
BA_ "CANFD_BRS" BO_ 2633990192 1;
BA_ "GenMsgILSupport" BO_ 2633990192 0;
BA_ "NmAsrMessage" BO_ 2633990192 1;
BA_ "GenMsgSendType" BO_ 2633990192 8;
BA_ "VFrameFormat" BO_ 2633990192 15;
BA_ "CANFD_BRS" BO_ 2633990184 1;
BA_ "GenMsgILSupport" BO_ 2633990184 0;
BA_ "NmAsrMessage" BO_ 2633990184 1;
BA_ "GenMsgSendType" BO_ 2633990184 8;
BA_ "VFrameFormat" BO_ 2633990184 15;
BA_ "CANFD_BRS" BO_ 2633990179 1;
BA_ "GenMsgILSupport" BO_ 2633990179 0;
BA_ "NmAsrMessage" BO_ 2633990179 1;
BA_ "GenMsgSendType" BO_ 2633990179 8;
BA_ "VFrameFormat" BO_ 2633990179 15;
BA_ "CANFD_BRS" BO_ 1456 1;
BA_ "GenMsgCycleTime" BO_ 1456 1000;
BA_ "GenMsgStartDelayTime" BO_ 1456 125;
BA_ "VFrameFormat" BO_ 1456 14;
BA_ "CANFD_BRS" BO_ 455 1;
BA_ "GenMsgCycleTime" BO_ 455 20;
BA_ "GenMsgStartDelayTime" BO_ 455 5;
BA_ "VFrameFormat" BO_ 455 14;
BA_ "CANFD_BRS" BO_ 275 1;
BA_ "GenMsgCycleTime" BO_ 275 10;
BA_ "VFrameFormat" BO_ 275 14;
BA_ "CANFD_BRS" BO_ 271 1;
BA_ "GenMsgCycleTime" BO_ 271 10;
BA_ "VFrameFormat" BO_ 271 14;
BA_ "CANFD_BRS" BO_ 304 1;
BA_ "GenMsgCycleTime" BO_ 304 10;
BA_ "GenMsgStartDelayTime" BO_ 304 5;
BA_ "VFrameFormat" BO_ 304 14;
BA_ "CANFD_BRS" BO_ 288 1;
BA_ "GenMsgCycleTime" BO_ 288 10;
BA_ "VFrameFormat" BO_ 288 14;
BA_ "CANFD_BRS" BO_ 602 1;
BA_ "GenMsgCycleTime" BO_ 602 50;
BA_ "VFrameFormat" BO_ 602 14;
BA_ "CANFD_BRS" BO_ 598 1;
BA_ "GenMsgCycleTime" BO_ 598 50;
BA_ "GenMsgStartDelayTime" BO_ 598 30;
BA_ "VFrameFormat" BO_ 598 14;
BA_ "CANFD_BRS" BO_ 596 1;
BA_ "GenMsgCycleTime" BO_ 596 50;
BA_ "GenMsgStartDelayTime" BO_ 596 25;
BA_ "VFrameFormat" BO_ 596 14;
BA_ "CANFD_BRS" BO_ 298 1;
BA_ "GenMsgCycleTime" BO_ 298 10;
BA_ "VFrameFormat" BO_ 298 14;
BA_ "CANFD_BRS" BO_ 594 1;
BA_ "GenMsgCycleTime" BO_ 594 50;
BA_ "GenMsgStartDelayTime" BO_ 594 15;
BA_ "VFrameFormat" BO_ 594 14;
BA_ "GenSigSendType" SG_ 2671902706 FuncDiagDataTester_ISig_3 7;
BA_ "GenSigSendType" SG_ 2671902708 FuncDiagDataIntTesterF4_ISig_3 7;
BA_ "GenSigSendType" SG_ 2671833648 PhysDiagRespSig_F2_30_ISig_3 7;
BA_ "GenSigSendType" SG_ 2671833635 PhysDiagRespSig_F2_23_ISig_3 7;
BA_ "GenSigSendType" SG_ 2671784178 PhysDiagReqSig_30_F2_ISig_3 7;
BA_ "GenSigSendType" SG_ 2671780850 PhysDiagReqSig_23_F2_ISig_3 7;
BA_ "GenSigCycleTime" SG_ 1456 FasUsrDefLowSpeedReturnSetting_I 100;
BA_ "GenSigCycleTimeActive" SG_ 1456 FasUsrDefLowSpeedReturnSetting_I 100;
BA_ "GenSigStartValue" SG_ 1456 FasUsrDefLowSpeedReturnSetting_I 31;
BA_ "SystemSignalLongSymbol" SG_ 1456 FasUsrDefLowSpeedReturnSetting_I "FasUsrDefLowSpeedReturnSetting_ISig_3";
BA_ "GenSigCycleTime" SG_ 1456 ActualFasManualOffsetSetting_ISi 100;
BA_ "GenSigCycleTimeActive" SG_ 1456 ActualFasManualOffsetSetting_ISi 100;
BA_ "GenSigStartValue" SG_ 1456 ActualFasManualOffsetSetting_ISi 31;
BA_ "SystemSignalLongSymbol" SG_ 1456 ActualFasManualOffsetSetting_ISi "ActualFasManualOffsetSetting_ISig_3";
BA_ "GenSigCycleTime" SG_ 1456 FasUsrDefStiffnessCurveSetting_I 100;
BA_ "GenSigCycleTimeActive" SG_ 1456 FasUsrDefStiffnessCurveSetting_I 100;
BA_ "GenSigStartValue" SG_ 1456 FasUsrDefStiffnessCurveSetting_I 31;
BA_ "SystemSignalLongSymbol" SG_ 1456 FasUsrDefStiffnessCurveSetting_I "FasUsrDefStiffnessCurveSetting_ISig_3";
BA_ "GenSigCycleTime" SG_ 1456 FasUsrDefinedDampingSetting_ISig 100;
BA_ "GenSigCycleTimeActive" SG_ 1456 FasUsrDefinedDampingSetting_ISig 100;
BA_ "GenSigStartValue" SG_ 1456 FasUsrDefinedDampingSetting_ISig 31;
BA_ "SystemSignalLongSymbol" SG_ 1456 FasUsrDefinedDampingSetting_ISig "FasUsrDefinedDampingSetting_ISig_3";
BA_ "GenSigCycleTime" SG_ 1456 FasUsrDefStiffStraightSetting_IS 100;
BA_ "GenSigCycleTimeActive" SG_ 1456 FasUsrDefStiffStraightSetting_IS 100;
BA_ "GenSigStartValue" SG_ 1456 FasUsrDefStiffStraightSetting_IS 31;
BA_ "SystemSignalLongSymbol" SG_ 1456 FasUsrDefStiffStraightSetting_IS "FasUsrDefStiffStraightSetting_ISig_3";
BA_ "GenSigCycleTime" SG_ 1456 FasDriver_ISig_3 100;
BA_ "GenSigCycleTimeActive" SG_ 1456 FasDriver_ISig_3 100;
BA_ "GenSigStartValue" SG_ 1456 FasDriver_ISig_3 15;
BA_ "GenSigCycleTime" SG_ 1456 ActualFasPersSettingsButton_ISig 100;
BA_ "GenSigCycleTimeActive" SG_ 1456 ActualFasPersSettingsButton_ISig 100;
BA_ "GenSigStartValue" SG_ 1456 ActualFasPersSettingsButton_ISig 7;
BA_ "SystemSignalLongSymbol" SG_ 1456 ActualFasPersSettingsButton_ISig "ActualFasPersSettingsButton_ISig_3";
BA_ "GenSigCycleTime" SG_ 455 DriverSteeringTqEstimateConf 100;
BA_ "GenSigCycleTimeActive" SG_ 455 DriverSteeringTqEstimateConf 100;
BA_ "GenSigStartValue" SG_ 455 DriverSteeringTqEstimateConf 7;
BA_ "GenSigCycleTime" SG_ 455 OverSteerGuidanceStatus_ISig_3 100;
BA_ "GenSigCycleTimeActive" SG_ 455 OverSteerGuidanceStatus_ISig_3 100;
BA_ "GenSigStartValue" SG_ 455 OverSteerGuidanceStatus_ISig_3 3;
BA_ "GenSigCycleTime" SG_ 455 FASFullyOperational 100;
BA_ "GenSigCycleTimeActive" SG_ 455 FASFullyOperational 100;
BA_ "GenSigStartValue" SG_ 455 FASFullyOperational 3;
BA_ "GenSigCycleTime" SG_ 455 DriverSteeringTorqueEstimate 100;
BA_ "GenSigCycleTimeActive" SG_ 455 DriverSteeringTorqueEstimate 100;
BA_ "GenSigStartValue" SG_ 455 DriverSteeringTorqueEstimate 1023;
BA_ "GenSigCycleTime" SG_ 455 FASSaturated 100;
BA_ "GenSigCycleTimeActive" SG_ 455 FASSaturated 100;
BA_ "GenSigStartValue" SG_ 455 FASSaturated 3;
BA_ "GenSigCycleTime" SG_ 455 FrontRoadWheelAngleEstimate 100;
BA_ "GenSigCycleTimeActive" SG_ 455 FrontRoadWheelAngleEstimate 100;
BA_ "GenSigStartValue" SG_ 455 FrontRoadWheelAngleEstimate 65535;
BA_ "GenSigCycleTime" SG_ 455 FASFunctionInControl 100;
BA_ "GenSigCycleTimeActive" SG_ 455 FASFunctionInControl 100;
BA_ "GenSigStartValue" SG_ 455 FASFunctionInControl 3;
BA_ "GenSigCycleTime" SG_ 275 RoadWheelAngleResp_RateCap 100;
BA_ "GenSigCycleTimeActive" SG_ 275 RoadWheelAngleResp_RateCap 100;
BA_ "GenSigStartValue" SG_ 275 RoadWheelAngleResp_RateCap 255;
BA_ "GenSigCycleTime" SG_ 275 RoadWheelAngleResp_CRC 100;
BA_ "GenSigCycleTimeActive" SG_ 275 RoadWheelAngleResp_CRC 100;
BA_ "GenSigStartValue" SG_ 275 RoadWheelAngleResp_CRC 255;
BA_ "E2EDataId" SG_ 275 RoadWheelAngleResp_CRC 199;
BA_ "E2EDataLength" SG_ 275 RoadWheelAngleResp_CRC 56;
BA_ "E2EProfile" SG_ 275 RoadWheelAngleResp_CRC "P01";
BA_ "GenSigCycleTime" SG_ 275 SteeringCtrlModeRsp_CRC 100;
BA_ "GenSigCycleTimeActive" SG_ 275 SteeringCtrlModeRsp_CRC 100;
BA_ "GenSigStartValue" SG_ 275 SteeringCtrlModeRsp_CRC 255;
BA_ "E2EDataId" SG_ 275 SteeringCtrlModeRsp_CRC 200;
BA_ "E2EDataLength" SG_ 275 SteeringCtrlModeRsp_CRC 24;
BA_ "E2EProfile" SG_ 275 SteeringCtrlModeRsp_CRC "P01";
BA_ "GenSigCycleTime" SG_ 275 SteeringWheelTorque_SqC 100;
BA_ "GenSigCycleTimeActive" SG_ 275 SteeringWheelTorque_SqC 100;
BA_ "GenSigStartValue" SG_ 275 SteeringWheelTorque_SqC 14;
BA_ "GenSigCycleTime" SG_ 275 SteeringWheelTorque_CRC 100;
BA_ "GenSigCycleTimeActive" SG_ 275 SteeringWheelTorque_CRC 100;
BA_ "GenSigStartValue" SG_ 275 SteeringWheelTorque_CRC 255;
BA_ "E2EDataId" SG_ 275 SteeringWheelTorque_CRC 201;
BA_ "E2EDataLength" SG_ 275 SteeringWheelTorque_CRC 24;
BA_ "E2EProfile" SG_ 275 SteeringWheelTorque_CRC "P01";
BA_ "GenSigCycleTime" SG_ 275 SteeringCtrlModeRsp_Status 100;
BA_ "GenSigCycleTimeActive" SG_ 275 SteeringCtrlModeRsp_Status 100;
BA_ "GenSigStartValue" SG_ 275 SteeringCtrlModeRsp_Status 7;
BA_ "GenSigCycleTime" SG_ 275 SteeringCtrlModeRsp_SqC 100;
BA_ "GenSigCycleTimeActive" SG_ 275 SteeringCtrlModeRsp_SqC 100;
BA_ "GenSigStartValue" SG_ 275 SteeringCtrlModeRsp_SqC 14;
BA_ "GenSigCycleTime" SG_ 275 RoadWheelAngleResp_Status 100;
BA_ "GenSigCycleTimeActive" SG_ 275 RoadWheelAngleResp_Status 100;
BA_ "GenSigStartValue" SG_ 275 RoadWheelAngleResp_Status 65535;
BA_ "GenSigCycleTime" SG_ 275 SteeringWheelTorque_Estimate 100;
BA_ "GenSigCycleTimeActive" SG_ 275 SteeringWheelTorque_Estimate 100;
BA_ "GenSigStartValue" SG_ 275 SteeringWheelTorque_Estimate 1023;
BA_ "GenSigCycleTime" SG_ 275 SteeringCtrlModeRsp_Cap 100;
BA_ "GenSigCycleTimeActive" SG_ 275 SteeringCtrlModeRsp_Cap 100;
BA_ "GenSigStartValue" SG_ 275 SteeringCtrlModeRsp_Cap 7;
BA_ "GenSigCycleTime" SG_ 275 RoadWheelAngleResp_MaxCap 100;
BA_ "GenSigCycleTimeActive" SG_ 275 RoadWheelAngleResp_MaxCap 100;
BA_ "GenSigStartValue" SG_ 275 RoadWheelAngleResp_MaxCap 255;
BA_ "GenSigCycleTime" SG_ 275 SteeringCtrlModeRsp_Active 100;
BA_ "GenSigCycleTimeActive" SG_ 275 SteeringCtrlModeRsp_Active 100;
BA_ "GenSigStartValue" SG_ 275 SteeringCtrlModeRsp_Active 3;
BA_ "GenSigCycleTime" SG_ 275 RoadWheelAngleResp_MinCap 100;
BA_ "GenSigCycleTimeActive" SG_ 275 RoadWheelAngleResp_MinCap 100;
BA_ "GenSigStartValue" SG_ 275 RoadWheelAngleResp_MinCap 255;
BA_ "GenSigCycleTime" SG_ 275 RoadWheelAngleResp_SqC 100;
BA_ "GenSigCycleTimeActive" SG_ 275 RoadWheelAngleResp_SqC 100;
BA_ "GenSigStartValue" SG_ 275 RoadWheelAngleResp_SqC 14;
BA_ "GenSigCycleTime" SG_ 271 ZxbrStsVeh_RetTar 100;
BA_ "GenSigCycleTimeActive" SG_ 271 ZxbrStsVeh_RetTar 100;
BA_ "GenSigStartValue" SG_ 271 ZxbrStsVeh_RetTar 255;
BA_ "GenSigCycleTime" SG_ 271 ZxbrStsVeh_RetEbiModSts 100;
BA_ "GenSigCycleTimeActive" SG_ 271 ZxbrStsVeh_RetEbiModSts 100;
BA_ "GenSigStartValue" SG_ 271 ZxbrStsVeh_RetEbiModSts 7;
BA_ "GenSigCycleTime" SG_ 271 ZxbrStsVeh_EbsCtrlModSts 100;
BA_ "GenSigCycleTimeActive" SG_ 271 ZxbrStsVeh_EbsCtrlModSts 100;
BA_ "GenSigStartValue" SG_ 271 ZxbrStsVeh_EbsCtrlModSts 3;
BA_ "GenSigCycleTime" SG_ 271 ZxbrStsVeh_RetSts 100;
BA_ "GenSigCycleTimeActive" SG_ 271 ZxbrStsVeh_RetSts 100;
BA_ "GenSigStartValue" SG_ 271 ZxbrStsVeh_RetSts 255;
BA_ "GenSigCycleTime" SG_ 271 ZxbrStsVeh_EbsHealthSts 100;
BA_ "GenSigCycleTimeActive" SG_ 271 ZxbrStsVeh_EbsHealthSts 100;
BA_ "GenSigStartValue" SG_ 271 ZxbrStsVeh_EbsHealthSts 7;
BA_ "GenSigCycleTime" SG_ 271 ZxbrStsVeh_SqC 100;
BA_ "GenSigCycleTimeActive" SG_ 271 ZxbrStsVeh_SqC 100;
BA_ "GenSigStartValue" SG_ 271 ZxbrStsVeh_SqC 14;
BA_ "GenSigCycleTime" SG_ 271 ZxbrStsVeh_RetModSts 100;
BA_ "GenSigCycleTimeActive" SG_ 271 ZxbrStsVeh_RetModSts 100;
BA_ "GenSigStartValue" SG_ 271 ZxbrStsVeh_RetModSts 7;
BA_ "GenSigCycleTime" SG_ 271 ZxbrStsVeh_DrvrModSts 100;
BA_ "GenSigCycleTimeActive" SG_ 271 ZxbrStsVeh_DrvrModSts 100;
BA_ "GenSigStartValue" SG_ 271 ZxbrStsVeh_DrvrModSts 3;
BA_ "GenSigCycleTime" SG_ 271 ZxbrStsVeh_RetCpbty 100;
BA_ "GenSigCycleTimeActive" SG_ 271 ZxbrStsVeh_RetCpbty 100;
BA_ "GenSigStartValue" SG_ 271 ZxbrStsVeh_RetCpbty 127;
BA_ "GenSigCycleTime" SG_ 271 ZxbrStsVeh_CRC 100;
BA_ "GenSigCycleTimeActive" SG_ 271 ZxbrStsVeh_CRC 100;
BA_ "GenSigStartValue" SG_ 271 ZxbrStsVeh_CRC 255;
BA_ "E2EDataId" SG_ 271 ZxbrStsVeh_CRC 242;
BA_ "E2EDataLength" SG_ 271 ZxbrStsVeh_CRC 56;
BA_ "E2EProfile" SG_ 271 ZxbrStsVeh_CRC "P01";
BA_ "GenSigCycleTime" SG_ 304 Sts2Axle2_WhlTqRi 100;
BA_ "GenSigCycleTimeActive" SG_ 304 Sts2Axle2_WhlTqRi 100;
BA_ "GenSigStartValue" SG_ 304 Sts2Axle2_WhlTqRi 8191;
BA_ "GenSigCycleTime" SG_ 304 Sts2Axle4_WhlTqQltyLe 100;
BA_ "GenSigCycleTimeActive" SG_ 304 Sts2Axle4_WhlTqQltyLe 100;
BA_ "GenSigStartValue" SG_ 304 Sts2Axle4_WhlTqQltyLe 3;
BA_ "GenSigCycleTime" SG_ 304 Sts2Axle3_SqC 100;
BA_ "GenSigCycleTimeActive" SG_ 304 Sts2Axle3_SqC 100;
BA_ "GenSigStartValue" SG_ 304 Sts2Axle3_SqC 255;
BA_ "GenSigCycleTime" SG_ 304 Sts2Axle6_WhlTqRi 100;
BA_ "GenSigCycleTimeActive" SG_ 304 Sts2Axle6_WhlTqRi 100;
BA_ "GenSigStartValue" SG_ 304 Sts2Axle6_WhlTqRi 8191;
BA_ "GenSigCycleTime" SG_ 304 Sts2Axle3_BrkTqReqRefLe 100;
BA_ "GenSigCycleTimeActive" SG_ 304 Sts2Axle3_BrkTqReqRefLe 100;
BA_ "GenSigStartValue" SG_ 304 Sts2Axle3_BrkTqReqRefLe 8191;
BA_ "GenSigCycleTime" SG_ 304 Sts2Axle2_WhlTqQltyRi 100;
BA_ "GenSigCycleTimeActive" SG_ 304 Sts2Axle2_WhlTqQltyRi 100;
BA_ "GenSigStartValue" SG_ 304 Sts2Axle2_WhlTqQltyRi 3;
BA_ "GenSigCycleTime" SG_ 304 Sts2Axle1_SqC 100;
BA_ "GenSigCycleTimeActive" SG_ 304 Sts2Axle1_SqC 100;
BA_ "GenSigStartValue" SG_ 304 Sts2Axle1_SqC 255;
BA_ "GenSigCycleTime" SG_ 304 Sts2Axle1_BrkTqReqRefLe 100;
BA_ "GenSigCycleTimeActive" SG_ 304 Sts2Axle1_BrkTqReqRefLe 100;
BA_ "GenSigStartValue" SG_ 304 Sts2Axle1_BrkTqReqRefLe 8191;
BA_ "GenSigCycleTime" SG_ 304 Sts2Axle2_WhlTqQltyLe 100;
BA_ "GenSigCycleTimeActive" SG_ 304 Sts2Axle2_WhlTqQltyLe 100;
BA_ "GenSigStartValue" SG_ 304 Sts2Axle2_WhlTqQltyLe 3;
BA_ "GenSigCycleTime" SG_ 304 Sts2Axle4_BrkTqReqRefLe 100;
BA_ "GenSigCycleTimeActive" SG_ 304 Sts2Axle4_BrkTqReqRefLe 100;
BA_ "GenSigStartValue" SG_ 304 Sts2Axle4_BrkTqReqRefLe 8191;
BA_ "GenSigCycleTime" SG_ 304 Sts2Axle2_SqC 100;
BA_ "GenSigCycleTimeActive" SG_ 304 Sts2Axle2_SqC 100;
BA_ "GenSigStartValue" SG_ 304 Sts2Axle2_SqC 255;
BA_ "GenSigCycleTime" SG_ 304 Sts2Axle4_CRC 100;
BA_ "GenSigCycleTimeActive" SG_ 304 Sts2Axle4_CRC 100;
BA_ "GenSigStartValue" SG_ 304 Sts2Axle4_CRC 65535;
BA_ "E2EDataId" SG_ 304 Sts2Axle4_CRC 259;
BA_ "E2EDataLength" SG_ 304 Sts2Axle4_CRC 80;
BA_ "E2EProfile" SG_ 304 Sts2Axle4_CRC "P05";
BA_ "GenSigCycleTime" SG_ 304 Sts2Axle3_WhlTqQltyLe 100;
BA_ "GenSigCycleTimeActive" SG_ 304 Sts2Axle3_WhlTqQltyLe 100;
BA_ "GenSigStartValue" SG_ 304 Sts2Axle3_WhlTqQltyLe 3;
BA_ "GenSigCycleTime" SG_ 304 Sts2Axle1_WhlTqQltyRi 100;
BA_ "GenSigCycleTimeActive" SG_ 304 Sts2Axle1_WhlTqQltyRi 100;
BA_ "GenSigStartValue" SG_ 304 Sts2Axle1_WhlTqQltyRi 3;
BA_ "GenSigCycleTime" SG_ 304 Sts2Axle1_WhlTqLe 100;
BA_ "GenSigCycleTimeActive" SG_ 304 Sts2Axle1_WhlTqLe 100;
BA_ "GenSigStartValue" SG_ 304 Sts2Axle1_WhlTqLe 8191;
BA_ "GenSigCycleTime" SG_ 304 Sts2Axle4_SqC 100;
BA_ "GenSigCycleTimeActive" SG_ 304 Sts2Axle4_SqC 100;
BA_ "GenSigStartValue" SG_ 304 Sts2Axle4_SqC 255;
BA_ "GenSigCycleTime" SG_ 304 Sts2Axle4_WhlTqQltyRi 100;
BA_ "GenSigCycleTimeActive" SG_ 304 Sts2Axle4_WhlTqQltyRi 100;
BA_ "GenSigStartValue" SG_ 304 Sts2Axle4_WhlTqQltyRi 3;
BA_ "GenSigCycleTime" SG_ 304 Sts2Axle3_BrkTqReqRefRi 100;
BA_ "GenSigCycleTimeActive" SG_ 304 Sts2Axle3_BrkTqReqRefRi 100;
BA_ "GenSigStartValue" SG_ 304 Sts2Axle3_BrkTqReqRefRi 8191;
BA_ "GenSigCycleTime" SG_ 304 Sts2Axle6_SqC 100;
BA_ "GenSigCycleTimeActive" SG_ 304 Sts2Axle6_SqC 100;
BA_ "GenSigStartValue" SG_ 304 Sts2Axle6_SqC 255;
BA_ "GenSigCycleTime" SG_ 304 Sts2Axle6_CRC 100;
BA_ "GenSigCycleTimeActive" SG_ 304 Sts2Axle6_CRC 100;
BA_ "GenSigStartValue" SG_ 304 Sts2Axle6_CRC 65535;
BA_ "E2EDataId" SG_ 304 Sts2Axle6_CRC 261;
BA_ "E2EDataLength" SG_ 304 Sts2Axle6_CRC 80;
BA_ "E2EProfile" SG_ 304 Sts2Axle6_CRC "P05";
BA_ "GenSigCycleTime" SG_ 304 Sts2Axle5_BrkTqReqRefLe 100;
BA_ "GenSigCycleTimeActive" SG_ 304 Sts2Axle5_BrkTqReqRefLe 100;
BA_ "GenSigStartValue" SG_ 304 Sts2Axle5_BrkTqReqRefLe 8191;
BA_ "GenSigCycleTime" SG_ 304 Sts2Axle6_WhlTqQltyLe 100;
BA_ "GenSigCycleTimeActive" SG_ 304 Sts2Axle6_WhlTqQltyLe 100;
BA_ "GenSigStartValue" SG_ 304 Sts2Axle6_WhlTqQltyLe 3;
BA_ "GenSigCycleTime" SG_ 304 Sts2Axle2_WhlTqLe 100;
BA_ "GenSigCycleTimeActive" SG_ 304 Sts2Axle2_WhlTqLe 100;
BA_ "GenSigStartValue" SG_ 304 Sts2Axle2_WhlTqLe 8191;
BA_ "GenSigCycleTime" SG_ 304 Sts2Axle5_WhlTqQltyRi 100;
BA_ "GenSigCycleTimeActive" SG_ 304 Sts2Axle5_WhlTqQltyRi 100;
BA_ "GenSigStartValue" SG_ 304 Sts2Axle5_WhlTqQltyRi 3;
BA_ "GenSigCycleTime" SG_ 304 Sts2Axle3_CRC 100;
BA_ "GenSigCycleTimeActive" SG_ 304 Sts2Axle3_CRC 100;
BA_ "GenSigStartValue" SG_ 304 Sts2Axle3_CRC 65535;
BA_ "E2EDataId" SG_ 304 Sts2Axle3_CRC 258;
BA_ "E2EDataLength" SG_ 304 Sts2Axle3_CRC 80;
BA_ "E2EProfile" SG_ 304 Sts2Axle3_CRC "P05";
BA_ "GenSigCycleTime" SG_ 304 Sts2Axle6_BrkTqReqRefRi 100;
BA_ "GenSigCycleTimeActive" SG_ 304 Sts2Axle6_BrkTqReqRefRi 100;
BA_ "GenSigStartValue" SG_ 304 Sts2Axle6_BrkTqReqRefRi 8191;
BA_ "GenSigCycleTime" SG_ 304 Sts2Axle1_WhlTqRi 100;
BA_ "GenSigCycleTimeActive" SG_ 304 Sts2Axle1_WhlTqRi 100;
BA_ "GenSigStartValue" SG_ 304 Sts2Axle1_WhlTqRi 8191;
BA_ "GenSigCycleTime" SG_ 304 Sts2Axle4_BrkTqReqRefRi 100;
BA_ "GenSigCycleTimeActive" SG_ 304 Sts2Axle4_BrkTqReqRefRi 100;
BA_ "GenSigStartValue" SG_ 304 Sts2Axle4_BrkTqReqRefRi 8191;
BA_ "GenSigCycleTime" SG_ 304 Sts2Axle1_BrkTqReqRefRi 100;
BA_ "GenSigCycleTimeActive" SG_ 304 Sts2Axle1_BrkTqReqRefRi 100;
BA_ "GenSigStartValue" SG_ 304 Sts2Axle1_BrkTqReqRefRi 8191;
BA_ "GenSigCycleTime" SG_ 304 Sts2Axle2_BrkTqReqRefLe 100;
BA_ "GenSigCycleTimeActive" SG_ 304 Sts2Axle2_BrkTqReqRefLe 100;
BA_ "GenSigStartValue" SG_ 304 Sts2Axle2_BrkTqReqRefLe 8191;
BA_ "GenSigCycleTime" SG_ 304 Sts2Axle5_SqC 100;
BA_ "GenSigCycleTimeActive" SG_ 304 Sts2Axle5_SqC 100;
BA_ "GenSigStartValue" SG_ 304 Sts2Axle5_SqC 255;
BA_ "GenSigCycleTime" SG_ 304 Sts2Axle3_WhlTqLe 100;
BA_ "GenSigCycleTimeActive" SG_ 304 Sts2Axle3_WhlTqLe 100;
BA_ "GenSigStartValue" SG_ 304 Sts2Axle3_WhlTqLe 8191;
BA_ "GenSigCycleTime" SG_ 304 Sts2Axle6_WhlTqQltyRi 100;
BA_ "GenSigCycleTimeActive" SG_ 304 Sts2Axle6_WhlTqQltyRi 100;
BA_ "GenSigStartValue" SG_ 304 Sts2Axle6_WhlTqQltyRi 3;
BA_ "GenSigCycleTime" SG_ 304 Sts2Axle5_WhlTqRi 100;
BA_ "GenSigCycleTimeActive" SG_ 304 Sts2Axle5_WhlTqRi 100;
BA_ "GenSigStartValue" SG_ 304 Sts2Axle5_WhlTqRi 8191;
BA_ "GenSigCycleTime" SG_ 304 Sts2Axle5_WhlTqLe 100;
BA_ "GenSigCycleTimeActive" SG_ 304 Sts2Axle5_WhlTqLe 100;
BA_ "GenSigStartValue" SG_ 304 Sts2Axle5_WhlTqLe 8191;
BA_ "GenSigCycleTime" SG_ 304 Sts2Axle5_WhlTqQltyLe 100;
BA_ "GenSigCycleTimeActive" SG_ 304 Sts2Axle5_WhlTqQltyLe 100;
BA_ "GenSigStartValue" SG_ 304 Sts2Axle5_WhlTqQltyLe 3;
BA_ "GenSigCycleTime" SG_ 304 Sts2Axle1_WhlTqQltyLe 100;
BA_ "GenSigCycleTimeActive" SG_ 304 Sts2Axle1_WhlTqQltyLe 100;
BA_ "GenSigStartValue" SG_ 304 Sts2Axle1_WhlTqQltyLe 3;
BA_ "GenSigCycleTime" SG_ 304 Sts2Axle6_WhlTqLe 100;
BA_ "GenSigCycleTimeActive" SG_ 304 Sts2Axle6_WhlTqLe 100;
BA_ "GenSigStartValue" SG_ 304 Sts2Axle6_WhlTqLe 8191;
BA_ "GenSigCycleTime" SG_ 304 Sts2Axle4_WhlTqRi 100;
BA_ "GenSigCycleTimeActive" SG_ 304 Sts2Axle4_WhlTqRi 100;
BA_ "GenSigStartValue" SG_ 304 Sts2Axle4_WhlTqRi 8191;
BA_ "GenSigCycleTime" SG_ 304 Sts2Axle1_CRC 100;
BA_ "GenSigCycleTimeActive" SG_ 304 Sts2Axle1_CRC 100;
BA_ "GenSigStartValue" SG_ 304 Sts2Axle1_CRC 65535;
BA_ "E2EDataId" SG_ 304 Sts2Axle1_CRC 256;
BA_ "E2EDataLength" SG_ 304 Sts2Axle1_CRC 80;
BA_ "E2EProfile" SG_ 304 Sts2Axle1_CRC "P05";
BA_ "GenSigCycleTime" SG_ 304 Sts2Axle5_CRC 100;
BA_ "GenSigCycleTimeActive" SG_ 304 Sts2Axle5_CRC 100;
BA_ "GenSigStartValue" SG_ 304 Sts2Axle5_CRC 65535;
BA_ "E2EDataId" SG_ 304 Sts2Axle5_CRC 260;
BA_ "E2EDataLength" SG_ 304 Sts2Axle5_CRC 80;
BA_ "E2EProfile" SG_ 304 Sts2Axle5_CRC "P05";
BA_ "GenSigCycleTime" SG_ 304 Sts2Axle3_WhlTqRi 100;
BA_ "GenSigCycleTimeActive" SG_ 304 Sts2Axle3_WhlTqRi 100;
BA_ "GenSigStartValue" SG_ 304 Sts2Axle3_WhlTqRi 8191;
BA_ "GenSigCycleTime" SG_ 304 Sts2Axle6_BrkTqReqRefLe 100;
BA_ "GenSigCycleTimeActive" SG_ 304 Sts2Axle6_BrkTqReqRefLe 100;
BA_ "GenSigStartValue" SG_ 304 Sts2Axle6_BrkTqReqRefLe 8191;
BA_ "GenSigCycleTime" SG_ 304 Sts2Axle2_BrkTqReqRefRi 100;
BA_ "GenSigCycleTimeActive" SG_ 304 Sts2Axle2_BrkTqReqRefRi 100;
BA_ "GenSigStartValue" SG_ 304 Sts2Axle2_BrkTqReqRefRi 8191;
BA_ "GenSigCycleTime" SG_ 304 Sts2Axle2_CRC 100;
BA_ "GenSigCycleTimeActive" SG_ 304 Sts2Axle2_CRC 100;
BA_ "GenSigStartValue" SG_ 304 Sts2Axle2_CRC 65535;
BA_ "E2EDataId" SG_ 304 Sts2Axle2_CRC 257;
BA_ "E2EDataLength" SG_ 304 Sts2Axle2_CRC 80;
BA_ "E2EProfile" SG_ 304 Sts2Axle2_CRC "P05";
BA_ "GenSigCycleTime" SG_ 304 Sts2Axle3_WhlTqQltyRi 100;
BA_ "GenSigCycleTimeActive" SG_ 304 Sts2Axle3_WhlTqQltyRi 100;
BA_ "GenSigStartValue" SG_ 304 Sts2Axle3_WhlTqQltyRi 3;
BA_ "GenSigCycleTime" SG_ 304 Sts2Axle4_WhlTqLe 100;
BA_ "GenSigCycleTimeActive" SG_ 304 Sts2Axle4_WhlTqLe 100;
BA_ "GenSigStartValue" SG_ 304 Sts2Axle4_WhlTqLe 8191;
BA_ "GenSigCycleTime" SG_ 304 Sts2Axle5_BrkTqReqRefRi 100;
BA_ "GenSigCycleTimeActive" SG_ 304 Sts2Axle5_BrkTqReqRefRi 100;
BA_ "GenSigStartValue" SG_ 304 Sts2Axle5_BrkTqReqRefRi 8191;
BA_ "GenSigCycleTime" SG_ 288 Sts1Axle6_WhlRotQltyLe 100;
BA_ "GenSigCycleTimeActive" SG_ 288 Sts1Axle6_WhlRotQltyLe 100;
BA_ "GenSigStartValue" SG_ 288 Sts1Axle6_WhlRotQltyLe 3;
BA_ "GenSigMaxLatency" SG_ 288 Sts1Axle6_WhlRotQltyLe 10;
BA_ "GenSigCycleTime" SG_ 288 Sts1Axle5_CRC 100;
BA_ "GenSigCycleTimeActive" SG_ 288 Sts1Axle5_CRC 100;
BA_ "GenSigStartValue" SG_ 288 Sts1Axle5_CRC 255;
BA_ "GenSigMaxLatency" SG_ 288 Sts1Axle5_CRC 10;
BA_ "E2EDataId" SG_ 288 Sts1Axle5_CRC 254;
BA_ "E2EDataLength" SG_ 288 Sts1Axle5_CRC 64;
BA_ "E2EProfile" SG_ 288 Sts1Axle5_CRC "P01";
BA_ "GenSigCycleTime" SG_ 288 Sts1Axle2_WhlRotQltyRi 100;
BA_ "GenSigCycleTimeActive" SG_ 288 Sts1Axle2_WhlRotQltyRi 100;
BA_ "GenSigStartValue" SG_ 288 Sts1Axle2_WhlRotQltyRi 3;
BA_ "GenSigMaxLatency" SG_ 288 Sts1Axle2_WhlRotQltyRi 10;
BA_ "GenSigCycleTime" SG_ 288 Sts1Axle2_WhlRotSpdRi 100;
BA_ "GenSigCycleTimeActive" SG_ 288 Sts1Axle2_WhlRotSpdRi 100;
BA_ "GenSigStartValue" SG_ 288 Sts1Axle2_WhlRotSpdRi 32767;
BA_ "GenSigMaxLatency" SG_ 288 Sts1Axle2_WhlRotSpdRi 10;
BA_ "GenSigCycleTime" SG_ 288 Sts1Axle6_CRC 100;
BA_ "GenSigCycleTimeActive" SG_ 288 Sts1Axle6_CRC 100;
BA_ "GenSigStartValue" SG_ 288 Sts1Axle6_CRC 255;
BA_ "GenSigMaxLatency" SG_ 288 Sts1Axle6_CRC 10;
BA_ "E2EDataId" SG_ 288 Sts1Axle6_CRC 255;
BA_ "E2EDataLength" SG_ 288 Sts1Axle6_CRC 64;
BA_ "E2EProfile" SG_ 288 Sts1Axle6_CRC "P01";
BA_ "GenSigCycleTime" SG_ 288 Sts1Axle5_WhlRotAgCntrRi 100;
BA_ "GenSigCycleTimeActive" SG_ 288 Sts1Axle5_WhlRotAgCntrRi 100;
BA_ "GenSigStartValue" SG_ 288 Sts1Axle5_WhlRotAgCntrRi 511;
BA_ "GenSigMaxLatency" SG_ 288 Sts1Axle5_WhlRotAgCntrRi 10;
BA_ "GenSigCycleTime" SG_ 288 Sts1Axle3_CRC 100;
BA_ "GenSigCycleTimeActive" SG_ 288 Sts1Axle3_CRC 100;
BA_ "GenSigStartValue" SG_ 288 Sts1Axle3_CRC 255;
BA_ "GenSigMaxLatency" SG_ 288 Sts1Axle3_CRC 10;
BA_ "E2EDataId" SG_ 288 Sts1Axle3_CRC 252;
BA_ "E2EDataLength" SG_ 288 Sts1Axle3_CRC 64;
BA_ "E2EProfile" SG_ 288 Sts1Axle3_CRC "P01";
BA_ "GenSigCycleTime" SG_ 288 Sts1Axle4_WhlRotSpdLe 100;
BA_ "GenSigCycleTimeActive" SG_ 288 Sts1Axle4_WhlRotSpdLe 100;
BA_ "GenSigStartValue" SG_ 288 Sts1Axle4_WhlRotSpdLe 32767;
BA_ "GenSigMaxLatency" SG_ 288 Sts1Axle4_WhlRotSpdLe 10;
BA_ "GenSigCycleTime" SG_ 288 Sts1Axle4_WhlRotAgCntrLe 100;
BA_ "GenSigCycleTimeActive" SG_ 288 Sts1Axle4_WhlRotAgCntrLe 100;
BA_ "GenSigStartValue" SG_ 288 Sts1Axle4_WhlRotAgCntrLe 511;
BA_ "GenSigMaxLatency" SG_ 288 Sts1Axle4_WhlRotAgCntrLe 10;
BA_ "GenSigCycleTime" SG_ 288 Sts1Axle6_WhlRotSpdRi 100;
BA_ "GenSigCycleTimeActive" SG_ 288 Sts1Axle6_WhlRotSpdRi 100;
BA_ "GenSigStartValue" SG_ 288 Sts1Axle6_WhlRotSpdRi 32767;
BA_ "GenSigMaxLatency" SG_ 288 Sts1Axle6_WhlRotSpdRi 10;
BA_ "GenSigCycleTime" SG_ 288 Sts1Axle3_WhlRotAgCntrLe 100;
BA_ "GenSigCycleTimeActive" SG_ 288 Sts1Axle3_WhlRotAgCntrLe 100;
BA_ "GenSigStartValue" SG_ 288 Sts1Axle3_WhlRotAgCntrLe 511;
BA_ "GenSigMaxLatency" SG_ 288 Sts1Axle3_WhlRotAgCntrLe 10;
BA_ "GenSigCycleTime" SG_ 288 Sts1Axle2_CRC 100;
BA_ "GenSigCycleTimeActive" SG_ 288 Sts1Axle2_CRC 100;
BA_ "GenSigStartValue" SG_ 288 Sts1Axle2_CRC 255;
BA_ "GenSigMaxLatency" SG_ 288 Sts1Axle2_CRC 10;
BA_ "E2EDataId" SG_ 288 Sts1Axle2_CRC 251;
BA_ "E2EDataLength" SG_ 288 Sts1Axle2_CRC 64;
BA_ "E2EProfile" SG_ 288 Sts1Axle2_CRC "P01";
BA_ "GenSigCycleTime" SG_ 288 Sts1Axle1_WhlRotSpdRi 100;
BA_ "GenSigCycleTimeActive" SG_ 288 Sts1Axle1_WhlRotSpdRi 100;
BA_ "GenSigStartValue" SG_ 288 Sts1Axle1_WhlRotSpdRi 32767;
BA_ "GenSigMaxLatency" SG_ 288 Sts1Axle1_WhlRotSpdRi 10;
BA_ "GenSigCycleTime" SG_ 288 Sts1Axle1_WhlRotQltyRi 100;
BA_ "GenSigCycleTimeActive" SG_ 288 Sts1Axle1_WhlRotQltyRi 100;
BA_ "GenSigStartValue" SG_ 288 Sts1Axle1_WhlRotQltyRi 3;
BA_ "GenSigMaxLatency" SG_ 288 Sts1Axle1_WhlRotQltyRi 10;
BA_ "GenSigCycleTime" SG_ 288 Sts1Axle3_WhlRotQltyLe 100;
BA_ "GenSigCycleTimeActive" SG_ 288 Sts1Axle3_WhlRotQltyLe 100;
BA_ "GenSigStartValue" SG_ 288 Sts1Axle3_WhlRotQltyLe 3;
BA_ "GenSigMaxLatency" SG_ 288 Sts1Axle3_WhlRotQltyLe 10;
BA_ "GenSigCycleTime" SG_ 288 Sts1Axle5_WhlRotAgCntrLe 100;
BA_ "GenSigCycleTimeActive" SG_ 288 Sts1Axle5_WhlRotAgCntrLe 100;
BA_ "GenSigStartValue" SG_ 288 Sts1Axle5_WhlRotAgCntrLe 511;
BA_ "GenSigMaxLatency" SG_ 288 Sts1Axle5_WhlRotAgCntrLe 10;
BA_ "GenSigCycleTime" SG_ 288 Sts1Axle3_SqC 100;
BA_ "GenSigCycleTimeActive" SG_ 288 Sts1Axle3_SqC 100;
BA_ "GenSigStartValue" SG_ 288 Sts1Axle3_SqC 14;
BA_ "GenSigMaxLatency" SG_ 288 Sts1Axle3_SqC 10;
BA_ "GenSigCycleTime" SG_ 288 Sts1Axle4_SqC 100;
BA_ "GenSigCycleTimeActive" SG_ 288 Sts1Axle4_SqC 100;
BA_ "GenSigStartValue" SG_ 288 Sts1Axle4_SqC 14;
BA_ "GenSigMaxLatency" SG_ 288 Sts1Axle4_SqC 10;
BA_ "GenSigCycleTime" SG_ 288 Sts1Axle1_SqC 100;
BA_ "GenSigCycleTimeActive" SG_ 288 Sts1Axle1_SqC 100;
BA_ "GenSigStartValue" SG_ 288 Sts1Axle1_SqC 14;
BA_ "GenSigMaxLatency" SG_ 288 Sts1Axle1_SqC 10;
BA_ "GenSigCycleTime" SG_ 288 Sts1Axle5_SqC 100;
BA_ "GenSigCycleTimeActive" SG_ 288 Sts1Axle5_SqC 100;
BA_ "GenSigStartValue" SG_ 288 Sts1Axle5_SqC 14;
BA_ "GenSigMaxLatency" SG_ 288 Sts1Axle5_SqC 10;
BA_ "GenSigCycleTime" SG_ 288 Sts1Axle2_WhlRotSpdLe 100;
BA_ "GenSigCycleTimeActive" SG_ 288 Sts1Axle2_WhlRotSpdLe 100;
BA_ "GenSigStartValue" SG_ 288 Sts1Axle2_WhlRotSpdLe 32767;
BA_ "GenSigMaxLatency" SG_ 288 Sts1Axle2_WhlRotSpdLe 10;
BA_ "GenSigCycleTime" SG_ 288 Sts1Axle1_WhlRotQltyLe 100;
BA_ "GenSigCycleTimeActive" SG_ 288 Sts1Axle1_WhlRotQltyLe 100;
BA_ "GenSigStartValue" SG_ 288 Sts1Axle1_WhlRotQltyLe 3;
BA_ "GenSigMaxLatency" SG_ 288 Sts1Axle1_WhlRotQltyLe 10;
BA_ "GenSigCycleTime" SG_ 288 Sts1Axle3_WhlRotAgCntrRi 100;
BA_ "GenSigCycleTimeActive" SG_ 288 Sts1Axle3_WhlRotAgCntrRi 100;
BA_ "GenSigStartValue" SG_ 288 Sts1Axle3_WhlRotAgCntrRi 511;
BA_ "GenSigMaxLatency" SG_ 288 Sts1Axle3_WhlRotAgCntrRi 10;
BA_ "GenSigCycleTime" SG_ 288 Sts1Axle1_WhlRotAgCntrLe 100;
BA_ "GenSigCycleTimeActive" SG_ 288 Sts1Axle1_WhlRotAgCntrLe 100;
BA_ "GenSigStartValue" SG_ 288 Sts1Axle1_WhlRotAgCntrLe 511;
BA_ "GenSigMaxLatency" SG_ 288 Sts1Axle1_WhlRotAgCntrLe 10;
BA_ "GenSigCycleTime" SG_ 288 Sts1Axle1_CRC 100;
BA_ "GenSigCycleTimeActive" SG_ 288 Sts1Axle1_CRC 100;
BA_ "GenSigStartValue" SG_ 288 Sts1Axle1_CRC 255;
BA_ "GenSigMaxLatency" SG_ 288 Sts1Axle1_CRC 10;
BA_ "E2EDataId" SG_ 288 Sts1Axle1_CRC 250;
BA_ "E2EDataLength" SG_ 288 Sts1Axle1_CRC 64;
BA_ "E2EProfile" SG_ 288 Sts1Axle1_CRC "P01";
BA_ "GenSigCycleTime" SG_ 288 Sts1Axle6_WhlRotAgCntrLe 100;
BA_ "GenSigCycleTimeActive" SG_ 288 Sts1Axle6_WhlRotAgCntrLe 100;
BA_ "GenSigStartValue" SG_ 288 Sts1Axle6_WhlRotAgCntrLe 511;
BA_ "GenSigMaxLatency" SG_ 288 Sts1Axle6_WhlRotAgCntrLe 10;
BA_ "GenSigCycleTime" SG_ 288 Sts1Axle5_WhlRotQltyLe 100;
BA_ "GenSigCycleTimeActive" SG_ 288 Sts1Axle5_WhlRotQltyLe 100;
BA_ "GenSigStartValue" SG_ 288 Sts1Axle5_WhlRotQltyLe 3;
BA_ "GenSigMaxLatency" SG_ 288 Sts1Axle5_WhlRotQltyLe 10;
BA_ "GenSigCycleTime" SG_ 288 Sts1Axle5_WhlRotQltyRi 100;
BA_ "GenSigCycleTimeActive" SG_ 288 Sts1Axle5_WhlRotQltyRi 100;
BA_ "GenSigStartValue" SG_ 288 Sts1Axle5_WhlRotQltyRi 3;
BA_ "GenSigMaxLatency" SG_ 288 Sts1Axle5_WhlRotQltyRi 10;
BA_ "GenSigCycleTime" SG_ 288 Sts1Axle1_WhlRotSpdLe 100;
BA_ "GenSigCycleTimeActive" SG_ 288 Sts1Axle1_WhlRotSpdLe 100;
BA_ "GenSigStartValue" SG_ 288 Sts1Axle1_WhlRotSpdLe 32767;
BA_ "GenSigMaxLatency" SG_ 288 Sts1Axle1_WhlRotSpdLe 10;
BA_ "GenSigCycleTime" SG_ 288 Sts1Axle2_WhlRotAgCntrRi 100;
BA_ "GenSigCycleTimeActive" SG_ 288 Sts1Axle2_WhlRotAgCntrRi 100;
BA_ "GenSigStartValue" SG_ 288 Sts1Axle2_WhlRotAgCntrRi 511;
BA_ "GenSigMaxLatency" SG_ 288 Sts1Axle2_WhlRotAgCntrRi 10;
BA_ "GenSigCycleTime" SG_ 288 Sts1Axle4_WhlRotQltyRi 100;
BA_ "GenSigCycleTimeActive" SG_ 288 Sts1Axle4_WhlRotQltyRi 100;
BA_ "GenSigStartValue" SG_ 288 Sts1Axle4_WhlRotQltyRi 3;
BA_ "GenSigMaxLatency" SG_ 288 Sts1Axle4_WhlRotQltyRi 10;
BA_ "GenSigCycleTime" SG_ 288 Sts1Axle2_WhlRotAgCntrLe 100;
BA_ "GenSigCycleTimeActive" SG_ 288 Sts1Axle2_WhlRotAgCntrLe 100;
BA_ "GenSigStartValue" SG_ 288 Sts1Axle2_WhlRotAgCntrLe 511;
BA_ "GenSigMaxLatency" SG_ 288 Sts1Axle2_WhlRotAgCntrLe 10;
BA_ "GenSigCycleTime" SG_ 288 Sts1Axle3_WhlRotQltyRi 100;
BA_ "GenSigCycleTimeActive" SG_ 288 Sts1Axle3_WhlRotQltyRi 100;
BA_ "GenSigStartValue" SG_ 288 Sts1Axle3_WhlRotQltyRi 3;
BA_ "GenSigMaxLatency" SG_ 288 Sts1Axle3_WhlRotQltyRi 10;
BA_ "GenSigCycleTime" SG_ 288 Sts1Axle6_WhlRotAgCntrRi 100;
BA_ "GenSigCycleTimeActive" SG_ 288 Sts1Axle6_WhlRotAgCntrRi 100;
BA_ "GenSigStartValue" SG_ 288 Sts1Axle6_WhlRotAgCntrRi 511;
BA_ "GenSigMaxLatency" SG_ 288 Sts1Axle6_WhlRotAgCntrRi 10;
BA_ "GenSigCycleTime" SG_ 288 Sts1Axle5_WhlRotSpdRi 100;
BA_ "GenSigCycleTimeActive" SG_ 288 Sts1Axle5_WhlRotSpdRi 100;
BA_ "GenSigStartValue" SG_ 288 Sts1Axle5_WhlRotSpdRi 32767;
BA_ "GenSigMaxLatency" SG_ 288 Sts1Axle5_WhlRotSpdRi 10;
BA_ "GenSigCycleTime" SG_ 288 Sts1Axle4_CRC 100;
BA_ "GenSigCycleTimeActive" SG_ 288 Sts1Axle4_CRC 100;
BA_ "GenSigStartValue" SG_ 288 Sts1Axle4_CRC 255;
BA_ "GenSigMaxLatency" SG_ 288 Sts1Axle4_CRC 10;
BA_ "E2EDataId" SG_ 288 Sts1Axle4_CRC 253;
BA_ "E2EDataLength" SG_ 288 Sts1Axle4_CRC 64;
BA_ "E2EProfile" SG_ 288 Sts1Axle4_CRC "P01";
BA_ "GenSigCycleTime" SG_ 288 Sts1Axle1_WhlRotAgCntrRi 100;
BA_ "GenSigCycleTimeActive" SG_ 288 Sts1Axle1_WhlRotAgCntrRi 100;
BA_ "GenSigStartValue" SG_ 288 Sts1Axle1_WhlRotAgCntrRi 511;
BA_ "GenSigMaxLatency" SG_ 288 Sts1Axle1_WhlRotAgCntrRi 10;
BA_ "GenSigCycleTime" SG_ 288 Sts1Axle5_WhlRotSpdLe 100;
BA_ "GenSigCycleTimeActive" SG_ 288 Sts1Axle5_WhlRotSpdLe 100;
BA_ "GenSigStartValue" SG_ 288 Sts1Axle5_WhlRotSpdLe 32767;
BA_ "GenSigMaxLatency" SG_ 288 Sts1Axle5_WhlRotSpdLe 10;
BA_ "GenSigCycleTime" SG_ 288 Sts1Axle3_WhlRotSpdLe 100;
BA_ "GenSigCycleTimeActive" SG_ 288 Sts1Axle3_WhlRotSpdLe 100;
BA_ "GenSigStartValue" SG_ 288 Sts1Axle3_WhlRotSpdLe 32767;
BA_ "GenSigMaxLatency" SG_ 288 Sts1Axle3_WhlRotSpdLe 10;
BA_ "GenSigCycleTime" SG_ 288 Sts1Axle4_WhlRotSpdRi 100;
BA_ "GenSigCycleTimeActive" SG_ 288 Sts1Axle4_WhlRotSpdRi 100;
BA_ "GenSigStartValue" SG_ 288 Sts1Axle4_WhlRotSpdRi 32767;
BA_ "GenSigMaxLatency" SG_ 288 Sts1Axle4_WhlRotSpdRi 10;
BA_ "GenSigCycleTime" SG_ 288 Sts1Axle4_WhlRotQltyLe 100;
BA_ "GenSigCycleTimeActive" SG_ 288 Sts1Axle4_WhlRotQltyLe 100;
BA_ "GenSigStartValue" SG_ 288 Sts1Axle4_WhlRotQltyLe 3;
BA_ "GenSigMaxLatency" SG_ 288 Sts1Axle4_WhlRotQltyLe 10;
BA_ "GenSigCycleTime" SG_ 288 Sts1Axle2_WhlRotQltyLe 100;
BA_ "GenSigCycleTimeActive" SG_ 288 Sts1Axle2_WhlRotQltyLe 100;
BA_ "GenSigStartValue" SG_ 288 Sts1Axle2_WhlRotQltyLe 3;
BA_ "GenSigMaxLatency" SG_ 288 Sts1Axle2_WhlRotQltyLe 10;
BA_ "GenSigCycleTime" SG_ 288 Sts1Axle6_WhlRotSpdLe 100;
BA_ "GenSigCycleTimeActive" SG_ 288 Sts1Axle6_WhlRotSpdLe 100;
BA_ "GenSigStartValue" SG_ 288 Sts1Axle6_WhlRotSpdLe 32767;
BA_ "GenSigMaxLatency" SG_ 288 Sts1Axle6_WhlRotSpdLe 10;
BA_ "GenSigCycleTime" SG_ 288 Sts1Axle4_WhlRotAgCntrRi 100;
BA_ "GenSigCycleTimeActive" SG_ 288 Sts1Axle4_WhlRotAgCntrRi 100;
BA_ "GenSigStartValue" SG_ 288 Sts1Axle4_WhlRotAgCntrRi 511;
BA_ "GenSigMaxLatency" SG_ 288 Sts1Axle4_WhlRotAgCntrRi 10;
BA_ "GenSigCycleTime" SG_ 288 Sts1Axle6_WhlRotQltyRi 100;
BA_ "GenSigCycleTimeActive" SG_ 288 Sts1Axle6_WhlRotQltyRi 100;
BA_ "GenSigStartValue" SG_ 288 Sts1Axle6_WhlRotQltyRi 3;
BA_ "GenSigMaxLatency" SG_ 288 Sts1Axle6_WhlRotQltyRi 10;
BA_ "GenSigCycleTime" SG_ 288 Sts1Axle2_SqC 100;
BA_ "GenSigCycleTimeActive" SG_ 288 Sts1Axle2_SqC 100;
BA_ "GenSigStartValue" SG_ 288 Sts1Axle2_SqC 14;
BA_ "GenSigMaxLatency" SG_ 288 Sts1Axle2_SqC 10;
BA_ "GenSigCycleTime" SG_ 288 Sts1Axle3_WhlRotSpdRi 100;
BA_ "GenSigCycleTimeActive" SG_ 288 Sts1Axle3_WhlRotSpdRi 100;
BA_ "GenSigStartValue" SG_ 288 Sts1Axle3_WhlRotSpdRi 32767;
BA_ "GenSigMaxLatency" SG_ 288 Sts1Axle3_WhlRotSpdRi 10;
BA_ "GenSigCycleTime" SG_ 288 Sts1Axle6_SqC 100;
BA_ "GenSigCycleTimeActive" SG_ 288 Sts1Axle6_SqC 100;
BA_ "GenSigStartValue" SG_ 288 Sts1Axle6_SqC 14;
BA_ "GenSigMaxLatency" SG_ 288 Sts1Axle6_SqC 10;
BA_ "GenSigCycleTime" SG_ 602 IxbrSts2Veh_CRC 100;
BA_ "GenSigCycleTimeActive" SG_ 602 IxbrSts2Veh_CRC 100;
BA_ "GenSigStartValue" SG_ 602 IxbrSts2Veh_CRC 255;
BA_ "E2EDataId" SG_ 602 IxbrSts2Veh_CRC 241;
BA_ "E2EDataLength" SG_ 602 IxbrSts2Veh_CRC 64;
BA_ "E2EProfile" SG_ 602 IxbrSts2Veh_CRC "P01";
BA_ "GenSigCycleTime" SG_ 602 IxbrSts1Veh_AbsSts 100;
BA_ "GenSigCycleTimeActive" SG_ 602 IxbrSts1Veh_AbsSts 100;
BA_ "GenSigStartValue" SG_ 602 IxbrSts1Veh_AbsSts 7;
BA_ "GenSigCycleTime" SG_ 602 IxbrSts1Veh_IxbrModSts 100;
BA_ "GenSigCycleTimeActive" SG_ 602 IxbrSts1Veh_IxbrModSts 100;
BA_ "GenSigStartValue" SG_ 602 IxbrSts1Veh_IxbrModSts 7;
BA_ "GenSigCycleTime" SG_ 602 IxbrSts2Veh_SqC 100;
BA_ "GenSigCycleTimeActive" SG_ 602 IxbrSts2Veh_SqC 100;
BA_ "GenSigStartValue" SG_ 602 IxbrSts2Veh_SqC 14;
BA_ "GenSigCycleTime" SG_ 602 IxbrSts1Veh_VehSpdLimRsc 100;
BA_ "GenSigCycleTimeActive" SG_ 602 IxbrSts1Veh_VehSpdLimRsc 100;
BA_ "GenSigStartValue" SG_ 602 IxbrSts1Veh_VehSpdLimRsc 8191;
BA_ "GenSigCycleTime" SG_ 602 IxbrSts2Veh_YawRateRefEsc 100;
BA_ "GenSigCycleTimeActive" SG_ 602 IxbrSts2Veh_YawRateRefEsc 100;
BA_ "GenSigStartValue" SG_ 602 IxbrSts2Veh_YawRateRefEsc 4095;
BA_ "GenSigCycleTime" SG_ 602 IxbrSts2Veh_VehAccnLatLimNeg 100;
BA_ "GenSigCycleTimeActive" SG_ 602 IxbrSts2Veh_VehAccnLatLimNeg 100;
BA_ "GenSigStartValue" SG_ 602 IxbrSts2Veh_VehAccnLatLimNeg 511;
BA_ "GenSigCycleTime" SG_ 602 IxbrSts1Veh_VehSpdLgt 100;
BA_ "GenSigCycleTimeActive" SG_ 602 IxbrSts1Veh_VehSpdLgt 100;
BA_ "GenSigStartValue" SG_ 602 IxbrSts1Veh_VehSpdLgt 8191;
BA_ "GenSigCycleTime" SG_ 602 IxbrSts1Veh_EscSts 100;
BA_ "GenSigCycleTimeActive" SG_ 602 IxbrSts1Veh_EscSts 100;
BA_ "GenSigStartValue" SG_ 602 IxbrSts1Veh_EscSts 7;
BA_ "GenSigCycleTime" SG_ 602 IxbrSts2Veh_YawRateOffsLim 100;
BA_ "GenSigCycleTimeActive" SG_ 602 IxbrSts2Veh_YawRateOffsLim 100;
BA_ "GenSigStartValue" SG_ 602 IxbrSts2Veh_YawRateOffsLim 4095;
BA_ "GenSigCycleTime" SG_ 602 IxbrSts1Veh_TscSts 100;
BA_ "GenSigCycleTimeActive" SG_ 602 IxbrSts1Veh_TscSts 100;
BA_ "GenSigStartValue" SG_ 602 IxbrSts1Veh_TscSts 7;
BA_ "GenSigCycleTime" SG_ 602 IxbrSts1Veh_CRC 100;
BA_ "GenSigCycleTimeActive" SG_ 602 IxbrSts1Veh_CRC 100;
BA_ "GenSigStartValue" SG_ 602 IxbrSts1Veh_CRC 255;
BA_ "E2EDataId" SG_ 602 IxbrSts1Veh_CRC 240;
BA_ "E2EDataLength" SG_ 602 IxbrSts1Veh_CRC 56;
BA_ "E2EProfile" SG_ 602 IxbrSts1Veh_CRC "P01";
BA_ "GenSigCycleTime" SG_ 602 IxbrSts2Veh_VehAccnLatLimPos 100;
BA_ "GenSigCycleTimeActive" SG_ 602 IxbrSts2Veh_VehAccnLatLimPos 100;
BA_ "GenSigStartValue" SG_ 602 IxbrSts2Veh_VehAccnLatLimPos 511;
BA_ "GenSigCycleTime" SG_ 602 IxbrSts1Veh_SqC 100;
BA_ "GenSigCycleTimeActive" SG_ 602 IxbrSts1Veh_SqC 100;
BA_ "GenSigStartValue" SG_ 602 IxbrSts1Veh_SqC 14;
BA_ "GenSigCycleTime" SG_ 602 IxbrSts1Veh_RscSts 100;
BA_ "GenSigCycleTimeActive" SG_ 602 IxbrSts1Veh_RscSts 100;
BA_ "GenSigStartValue" SG_ 602 IxbrSts1Veh_RscSts 7;
BA_ "GenSigCycleTime" SG_ 598 IxbrSts3Ax5_WhlAccnLgtLimMinLe 100;
BA_ "GenSigCycleTimeActive" SG_ 598 IxbrSts3Ax5_WhlAccnLgtLimMinLe 100;
BA_ "GenSigStartValue" SG_ 598 IxbrSts3Ax5_WhlAccnLgtLimMinLe 511;
BA_ "GenSigCycleTime" SG_ 598 IxbrSts3Ax5_CRC 100;
BA_ "GenSigCycleTimeActive" SG_ 598 IxbrSts3Ax5_CRC 100;
BA_ "GenSigStartValue" SG_ 598 IxbrSts3Ax5_CRC 255;
BA_ "E2EDataId" SG_ 598 IxbrSts3Ax5_CRC 238;
BA_ "E2EDataLength" SG_ 598 IxbrSts3Ax5_CRC 64;
BA_ "E2EProfile" SG_ 598 IxbrSts3Ax5_CRC "P01";
BA_ "GenSigCycleTime" SG_ 598 IxbrSts3Ax5_SqC 100;
BA_ "GenSigCycleTimeActive" SG_ 598 IxbrSts3Ax5_SqC 100;
BA_ "GenSigStartValue" SG_ 598 IxbrSts3Ax5_SqC 14;
BA_ "GenSigCycleTime" SG_ 598 IxbrSts1Ax6_CRC 100;
BA_ "GenSigCycleTimeActive" SG_ 598 IxbrSts1Ax6_CRC 100;
BA_ "GenSigStartValue" SG_ 598 IxbrSts1Ax6_CRC 255;
BA_ "E2EDataId" SG_ 598 IxbrSts1Ax6_CRC 227;
BA_ "E2EDataLength" SG_ 598 IxbrSts1Ax6_CRC 40;
BA_ "E2EProfile" SG_ 598 IxbrSts1Ax6_CRC "P01";
BA_ "GenSigCycleTime" SG_ 598 IxbrSts2Ax6_WhlSlipLimPrpnRi 100;
BA_ "GenSigCycleTimeActive" SG_ 598 IxbrSts2Ax6_WhlSlipLimPrpnRi 100;
BA_ "GenSigStartValue" SG_ 598 IxbrSts2Ax6_WhlSlipLimPrpnRi 255;
BA_ "GenSigCycleTime" SG_ 598 IxbrSts2Ax6_WhlSlipLimBrkngLe 100;
BA_ "GenSigCycleTimeActive" SG_ 598 IxbrSts2Ax6_WhlSlipLimBrkngLe 100;
BA_ "GenSigStartValue" SG_ 598 IxbrSts2Ax6_WhlSlipLimBrkngLe 255;
BA_ "GenSigCycleTime" SG_ 598 IxbrSts3Ax6_WhlAccnLgtLimMaxRi 100;
BA_ "GenSigCycleTimeActive" SG_ 598 IxbrSts3Ax6_WhlAccnLgtLimMaxRi 100;
BA_ "GenSigStartValue" SG_ 598 IxbrSts3Ax6_WhlAccnLgtLimMaxRi 511;
BA_ "GenSigCycleTime" SG_ 598 IxbrSts1Ax4_WhlRdEstmdLe 100;
BA_ "GenSigCycleTimeActive" SG_ 598 IxbrSts1Ax4_WhlRdEstmdLe 100;
BA_ "GenSigStartValue" SG_ 598 IxbrSts1Ax4_WhlRdEstmdLe 1023;
BA_ "GenSigCycleTime" SG_ 598 IxbrSts2Ax5_WhlSlipLimBrkngLe 100;
BA_ "GenSigCycleTimeActive" SG_ 598 IxbrSts2Ax5_WhlSlipLimBrkngLe 100;
BA_ "GenSigStartValue" SG_ 598 IxbrSts2Ax5_WhlSlipLimBrkngLe 255;
BA_ "GenSigCycleTime" SG_ 598 IxbrSts2Ax6_WhlSlipLimBrkngRi 100;
BA_ "GenSigCycleTimeActive" SG_ 598 IxbrSts2Ax6_WhlSlipLimBrkngRi 100;
BA_ "GenSigStartValue" SG_ 598 IxbrSts2Ax6_WhlSlipLimBrkngRi 255;
BA_ "GenSigCycleTime" SG_ 598 IxbrSts2Ax4_SqC 100;
BA_ "GenSigCycleTimeActive" SG_ 598 IxbrSts2Ax4_SqC 100;
BA_ "GenSigStartValue" SG_ 598 IxbrSts2Ax4_SqC 14;
BA_ "GenSigCycleTime" SG_ 598 IxbrSts3Ax4_CRC 100;
BA_ "GenSigCycleTimeActive" SG_ 598 IxbrSts3Ax4_CRC 100;
BA_ "GenSigStartValue" SG_ 598 IxbrSts3Ax4_CRC 255;
BA_ "E2EDataId" SG_ 598 IxbrSts3Ax4_CRC 237;
BA_ "E2EDataLength" SG_ 598 IxbrSts3Ax4_CRC 64;
BA_ "E2EProfile" SG_ 598 IxbrSts3Ax4_CRC "P01";
BA_ "GenSigCycleTime" SG_ 598 IxbrSts2Ax4_WhlSlipLimBrkngRi 100;
BA_ "GenSigCycleTimeActive" SG_ 598 IxbrSts2Ax4_WhlSlipLimBrkngRi 100;
BA_ "GenSigStartValue" SG_ 598 IxbrSts2Ax4_WhlSlipLimBrkngRi 255;
BA_ "GenSigCycleTime" SG_ 598 IxbrSts2Ax4_WhlSlipLimBrkngLe 100;
BA_ "GenSigCycleTimeActive" SG_ 598 IxbrSts2Ax4_WhlSlipLimBrkngLe 100;
BA_ "GenSigStartValue" SG_ 598 IxbrSts2Ax4_WhlSlipLimBrkngLe 255;
BA_ "GenSigCycleTime" SG_ 598 IxbrSts2Ax6_CRC 100;
BA_ "GenSigCycleTimeActive" SG_ 598 IxbrSts2Ax6_CRC 100;
BA_ "GenSigStartValue" SG_ 598 IxbrSts2Ax6_CRC 255;
BA_ "E2EDataId" SG_ 598 IxbrSts2Ax6_CRC 233;
BA_ "E2EDataLength" SG_ 598 IxbrSts2Ax6_CRC 48;
BA_ "E2EProfile" SG_ 598 IxbrSts2Ax6_CRC "P01";
BA_ "GenSigCycleTime" SG_ 598 IxbrSts2Ax4_CRC 100;
BA_ "GenSigCycleTimeActive" SG_ 598 IxbrSts2Ax4_CRC 100;
BA_ "GenSigStartValue" SG_ 598 IxbrSts2Ax4_CRC 255;
BA_ "E2EDataId" SG_ 598 IxbrSts2Ax4_CRC 231;
BA_ "E2EDataLength" SG_ 598 IxbrSts2Ax4_CRC 48;
BA_ "E2EProfile" SG_ 598 IxbrSts2Ax4_CRC "P01";
BA_ "GenSigCycleTime" SG_ 598 IxbrSts3Ax4_WhlAccnLgtLimMinLe 100;
BA_ "GenSigCycleTimeActive" SG_ 598 IxbrSts3Ax4_WhlAccnLgtLimMinLe 100;
BA_ "GenSigStartValue" SG_ 598 IxbrSts3Ax4_WhlAccnLgtLimMinLe 511;
BA_ "GenSigCycleTime" SG_ 598 IxbrSts3Ax6_CRC 100;
BA_ "GenSigCycleTimeActive" SG_ 598 IxbrSts3Ax6_CRC 100;
BA_ "GenSigStartValue" SG_ 598 IxbrSts3Ax6_CRC 255;
BA_ "E2EDataId" SG_ 598 IxbrSts3Ax6_CRC 239;
BA_ "E2EDataLength" SG_ 598 IxbrSts3Ax6_CRC 64;
BA_ "E2EProfile" SG_ 598 IxbrSts3Ax6_CRC "P01";
BA_ "GenSigCycleTime" SG_ 598 IxbrSts1Ax4_SqC 100;
BA_ "GenSigCycleTimeActive" SG_ 598 IxbrSts1Ax4_SqC 100;
BA_ "GenSigStartValue" SG_ 598 IxbrSts1Ax4_SqC 14;
BA_ "GenSigCycleTime" SG_ 598 IxbrSts1Ax6_SqC 100;
BA_ "GenSigCycleTimeActive" SG_ 598 IxbrSts1Ax6_SqC 100;
BA_ "GenSigStartValue" SG_ 598 IxbrSts1Ax6_SqC 14;
BA_ "GenSigCycleTime" SG_ 598 IxbrSts3Ax5_WhlAccnLgtLimMinRi 100;
BA_ "GenSigCycleTimeActive" SG_ 598 IxbrSts3Ax5_WhlAccnLgtLimMinRi 100;
BA_ "GenSigStartValue" SG_ 598 IxbrSts3Ax5_WhlAccnLgtLimMinRi 511;
BA_ "GenSigCycleTime" SG_ 598 IxbrSts2Ax6_WhlSlipLimPrpnLe 100;
BA_ "GenSigCycleTimeActive" SG_ 598 IxbrSts2Ax6_WhlSlipLimPrpnLe 100;
BA_ "GenSigStartValue" SG_ 598 IxbrSts2Ax6_WhlSlipLimPrpnLe 255;
BA_ "GenSigCycleTime" SG_ 598 IxbrSts2Ax5_SqC 100;
BA_ "GenSigCycleTimeActive" SG_ 598 IxbrSts2Ax5_SqC 100;
BA_ "GenSigStartValue" SG_ 598 IxbrSts2Ax5_SqC 14;
BA_ "GenSigCycleTime" SG_ 598 IxbrSts3Ax6_SqC 100;
BA_ "GenSigCycleTimeActive" SG_ 598 IxbrSts3Ax6_SqC 100;
BA_ "GenSigStartValue" SG_ 598 IxbrSts3Ax6_SqC 14;
BA_ "GenSigCycleTime" SG_ 598 IxbrSts2Ax5_WhlSlipLimBrkngRi 100;
BA_ "GenSigCycleTimeActive" SG_ 598 IxbrSts2Ax5_WhlSlipLimBrkngRi 100;
BA_ "GenSigStartValue" SG_ 598 IxbrSts2Ax5_WhlSlipLimBrkngRi 255;
BA_ "GenSigCycleTime" SG_ 598 IxbrSts1Ax5_CRC 100;
BA_ "GenSigCycleTimeActive" SG_ 598 IxbrSts1Ax5_CRC 100;
BA_ "GenSigStartValue" SG_ 598 IxbrSts1Ax5_CRC 255;
BA_ "E2EDataId" SG_ 598 IxbrSts1Ax5_CRC 226;
BA_ "E2EDataLength" SG_ 598 IxbrSts1Ax5_CRC 40;
BA_ "E2EProfile" SG_ 598 IxbrSts1Ax5_CRC "P01";
BA_ "GenSigCycleTime" SG_ 598 IxbrSts3Ax5_WhlAccnLgtLimMaxRi 100;
BA_ "GenSigCycleTimeActive" SG_ 598 IxbrSts3Ax5_WhlAccnLgtLimMaxRi 100;
BA_ "GenSigStartValue" SG_ 598 IxbrSts3Ax5_WhlAccnLgtLimMaxRi 511;
BA_ "GenSigCycleTime" SG_ 598 IxbrSts1Ax6_WhlRdEstmdLe 100;
BA_ "GenSigCycleTimeActive" SG_ 598 IxbrSts1Ax6_WhlRdEstmdLe 100;
BA_ "GenSigStartValue" SG_ 598 IxbrSts1Ax6_WhlRdEstmdLe 1023;
BA_ "GenSigCycleTime" SG_ 598 IxbrSts3Ax6_WhlAccnLgtLimMinLe 100;
BA_ "GenSigCycleTimeActive" SG_ 598 IxbrSts3Ax6_WhlAccnLgtLimMinLe 100;
BA_ "GenSigStartValue" SG_ 598 IxbrSts3Ax6_WhlAccnLgtLimMinLe 511;
BA_ "GenSigCycleTime" SG_ 598 IxbrSts2Ax5_WhlSlipLimPrpnRi 100;
BA_ "GenSigCycleTimeActive" SG_ 598 IxbrSts2Ax5_WhlSlipLimPrpnRi 100;
BA_ "GenSigStartValue" SG_ 598 IxbrSts2Ax5_WhlSlipLimPrpnRi 255;
BA_ "GenSigCycleTime" SG_ 598 IxbrSts2Ax6_SqC 100;
BA_ "GenSigCycleTimeActive" SG_ 598 IxbrSts2Ax6_SqC 100;
BA_ "GenSigStartValue" SG_ 598 IxbrSts2Ax6_SqC 14;
BA_ "GenSigCycleTime" SG_ 598 IxbrSts3Ax4_WhlAccnLgtLimMinRi 100;
BA_ "GenSigCycleTimeActive" SG_ 598 IxbrSts3Ax4_WhlAccnLgtLimMinRi 100;
BA_ "GenSigStartValue" SG_ 598 IxbrSts3Ax4_WhlAccnLgtLimMinRi 511;
BA_ "GenSigCycleTime" SG_ 598 IxbrSts1Ax5_SqC 100;
BA_ "GenSigCycleTimeActive" SG_ 598 IxbrSts1Ax5_SqC 100;
BA_ "GenSigStartValue" SG_ 598 IxbrSts1Ax5_SqC 14;
BA_ "GenSigCycleTime" SG_ 598 IxbrSts3Ax6_WhlAccnLgtLimMinRi 100;
BA_ "GenSigCycleTimeActive" SG_ 598 IxbrSts3Ax6_WhlAccnLgtLimMinRi 100;
BA_ "GenSigStartValue" SG_ 598 IxbrSts3Ax6_WhlAccnLgtLimMinRi 511;
BA_ "GenSigCycleTime" SG_ 598 IxbrSts2Ax5_CRC 100;
BA_ "GenSigCycleTimeActive" SG_ 598 IxbrSts2Ax5_CRC 100;
BA_ "GenSigStartValue" SG_ 598 IxbrSts2Ax5_CRC 255;
BA_ "E2EDataId" SG_ 598 IxbrSts2Ax5_CRC 232;
BA_ "E2EDataLength" SG_ 598 IxbrSts2Ax5_CRC 48;
BA_ "E2EProfile" SG_ 598 IxbrSts2Ax5_CRC "P01";
BA_ "GenSigCycleTime" SG_ 598 IxbrSts3Ax4_SqC 100;
BA_ "GenSigCycleTimeActive" SG_ 598 IxbrSts3Ax4_SqC 100;
BA_ "GenSigStartValue" SG_ 598 IxbrSts3Ax4_SqC 14;
BA_ "GenSigCycleTime" SG_ 598 IxbrSts3Ax6_WhlAccnLgtLimMaxLe 100;
BA_ "GenSigCycleTimeActive" SG_ 598 IxbrSts3Ax6_WhlAccnLgtLimMaxLe 100;
BA_ "GenSigStartValue" SG_ 598 IxbrSts3Ax6_WhlAccnLgtLimMaxLe 511;
BA_ "GenSigCycleTime" SG_ 598 IxbrSts3Ax4_WhlAccnLgtLimMaxLe 100;
BA_ "GenSigCycleTimeActive" SG_ 598 IxbrSts3Ax4_WhlAccnLgtLimMaxLe 100;
BA_ "GenSigStartValue" SG_ 598 IxbrSts3Ax4_WhlAccnLgtLimMaxLe 511;
BA_ "GenSigCycleTime" SG_ 598 IxbrSts1Ax6_WhlRdEstmdRi 100;
BA_ "GenSigCycleTimeActive" SG_ 598 IxbrSts1Ax6_WhlRdEstmdRi 100;
BA_ "GenSigStartValue" SG_ 598 IxbrSts1Ax6_WhlRdEstmdRi 1023;
BA_ "GenSigCycleTime" SG_ 598 IxbrSts1Ax4_WhlRdEstmdRi 100;
BA_ "GenSigCycleTimeActive" SG_ 598 IxbrSts1Ax4_WhlRdEstmdRi 100;
BA_ "GenSigStartValue" SG_ 598 IxbrSts1Ax4_WhlRdEstmdRi 1023;
BA_ "GenSigCycleTime" SG_ 598 IxbrSts3Ax4_WhlAccnLgtLimMaxRi 100;
BA_ "GenSigCycleTimeActive" SG_ 598 IxbrSts3Ax4_WhlAccnLgtLimMaxRi 100;
BA_ "GenSigStartValue" SG_ 598 IxbrSts3Ax4_WhlAccnLgtLimMaxRi 511;
BA_ "GenSigCycleTime" SG_ 598 IxbrSts2Ax4_WhlSlipLimPrpnRi 100;
BA_ "GenSigCycleTimeActive" SG_ 598 IxbrSts2Ax4_WhlSlipLimPrpnRi 100;
BA_ "GenSigStartValue" SG_ 598 IxbrSts2Ax4_WhlSlipLimPrpnRi 255;
BA_ "GenSigCycleTime" SG_ 598 IxbrSts1Ax5_WhlRdEstmdLe 100;
BA_ "GenSigCycleTimeActive" SG_ 598 IxbrSts1Ax5_WhlRdEstmdLe 100;
BA_ "GenSigStartValue" SG_ 598 IxbrSts1Ax5_WhlRdEstmdLe 1023;
BA_ "GenSigCycleTime" SG_ 598 IxbrSts2Ax4_WhlSlipLimPrpnLe 100;
BA_ "GenSigCycleTimeActive" SG_ 598 IxbrSts2Ax4_WhlSlipLimPrpnLe 100;
BA_ "GenSigStartValue" SG_ 598 IxbrSts2Ax4_WhlSlipLimPrpnLe 255;
BA_ "GenSigCycleTime" SG_ 598 IxbrSts3Ax5_WhlAccnLgtLimMaxLe 100;
BA_ "GenSigCycleTimeActive" SG_ 598 IxbrSts3Ax5_WhlAccnLgtLimMaxLe 100;
BA_ "GenSigStartValue" SG_ 598 IxbrSts3Ax5_WhlAccnLgtLimMaxLe 511;
BA_ "GenSigCycleTime" SG_ 598 IxbrSts2Ax5_WhlSlipLimPrpnLe 100;
BA_ "GenSigCycleTimeActive" SG_ 598 IxbrSts2Ax5_WhlSlipLimPrpnLe 100;
BA_ "GenSigStartValue" SG_ 598 IxbrSts2Ax5_WhlSlipLimPrpnLe 255;
BA_ "GenSigCycleTime" SG_ 598 IxbrSts1Ax4_CRC 100;
BA_ "GenSigCycleTimeActive" SG_ 598 IxbrSts1Ax4_CRC 100;
BA_ "GenSigStartValue" SG_ 598 IxbrSts1Ax4_CRC 255;
BA_ "E2EDataId" SG_ 598 IxbrSts1Ax4_CRC 225;
BA_ "E2EDataLength" SG_ 598 IxbrSts1Ax4_CRC 40;
BA_ "E2EProfile" SG_ 598 IxbrSts1Ax4_CRC "P01";
BA_ "GenSigCycleTime" SG_ 598 IxbrSts1Ax5_WhlRdEstmdRi 100;
BA_ "GenSigCycleTimeActive" SG_ 598 IxbrSts1Ax5_WhlRdEstmdRi 100;
BA_ "GenSigStartValue" SG_ 598 IxbrSts1Ax5_WhlRdEstmdRi 1023;
BA_ "GenSigCycleTime" SG_ 596 IxbrSts1Ax1_WhlRdEstmdRi 100;
BA_ "GenSigCycleTimeActive" SG_ 596 IxbrSts1Ax1_WhlRdEstmdRi 100;
BA_ "GenSigStartValue" SG_ 596 IxbrSts1Ax1_WhlRdEstmdRi 1023;
BA_ "GenSigCycleTime" SG_ 596 IxbrSts3Ax3_WhlAccnLgtLimMaxLe 100;
BA_ "GenSigCycleTimeActive" SG_ 596 IxbrSts3Ax3_WhlAccnLgtLimMaxLe 100;
BA_ "GenSigStartValue" SG_ 596 IxbrSts3Ax3_WhlAccnLgtLimMaxLe 511;
BA_ "GenSigCycleTime" SG_ 596 IxbrSts3Ax1_WhlAccnLgtLimMinRi 100;
BA_ "GenSigCycleTimeActive" SG_ 596 IxbrSts3Ax1_WhlAccnLgtLimMinRi 100;
BA_ "GenSigStartValue" SG_ 596 IxbrSts3Ax1_WhlAccnLgtLimMinRi 511;
BA_ "GenSigCycleTime" SG_ 596 IxbrSts3Ax3_CRC 100;
BA_ "GenSigCycleTimeActive" SG_ 596 IxbrSts3Ax3_CRC 100;
BA_ "GenSigStartValue" SG_ 596 IxbrSts3Ax3_CRC 255;
BA_ "E2EDataId" SG_ 596 IxbrSts3Ax3_CRC 236;
BA_ "E2EDataLength" SG_ 596 IxbrSts3Ax3_CRC 64;
BA_ "E2EProfile" SG_ 596 IxbrSts3Ax3_CRC "P01";
BA_ "GenSigCycleTime" SG_ 596 IxbrSts2Ax3_WhlSlipLimBrkngRi 100;
BA_ "GenSigCycleTimeActive" SG_ 596 IxbrSts2Ax3_WhlSlipLimBrkngRi 100;
BA_ "GenSigStartValue" SG_ 596 IxbrSts2Ax3_WhlSlipLimBrkngRi 255;
BA_ "GenSigCycleTime" SG_ 596 IxbrSts3Ax1_CRC 100;
BA_ "GenSigCycleTimeActive" SG_ 596 IxbrSts3Ax1_CRC 100;
BA_ "GenSigStartValue" SG_ 596 IxbrSts3Ax1_CRC 255;
BA_ "E2EDataId" SG_ 596 IxbrSts3Ax1_CRC 234;
BA_ "E2EDataLength" SG_ 596 IxbrSts3Ax1_CRC 64;
BA_ "E2EProfile" SG_ 596 IxbrSts3Ax1_CRC "P01";
BA_ "GenSigCycleTime" SG_ 596 IxbrSts2Ax3_WhlSlipLimPrpnRi 100;
BA_ "GenSigCycleTimeActive" SG_ 596 IxbrSts2Ax3_WhlSlipLimPrpnRi 100;
BA_ "GenSigStartValue" SG_ 596 IxbrSts2Ax3_WhlSlipLimPrpnRi 255;
BA_ "GenSigCycleTime" SG_ 596 IxbrSts2Ax1_WhlSlipLimPrpnLe 100;
BA_ "GenSigCycleTimeActive" SG_ 596 IxbrSts2Ax1_WhlSlipLimPrpnLe 100;
BA_ "GenSigStartValue" SG_ 596 IxbrSts2Ax1_WhlSlipLimPrpnLe 255;
BA_ "GenSigCycleTime" SG_ 596 IxbrSts3Ax3_WhlAccnLgtLimMinLe 100;
BA_ "GenSigCycleTimeActive" SG_ 596 IxbrSts3Ax3_WhlAccnLgtLimMinLe 100;
BA_ "GenSigStartValue" SG_ 596 IxbrSts3Ax3_WhlAccnLgtLimMinLe 511;
BA_ "GenSigCycleTime" SG_ 596 IxbrSts1Ax1_SqC 100;
BA_ "GenSigCycleTimeActive" SG_ 596 IxbrSts1Ax1_SqC 100;
BA_ "GenSigStartValue" SG_ 596 IxbrSts1Ax1_SqC 14;
BA_ "GenSigCycleTime" SG_ 596 IxbrSts2Ax3_CRC 100;
BA_ "GenSigCycleTimeActive" SG_ 596 IxbrSts2Ax3_CRC 100;
BA_ "GenSigStartValue" SG_ 596 IxbrSts2Ax3_CRC 255;
BA_ "E2EDataId" SG_ 596 IxbrSts2Ax3_CRC 230;
BA_ "E2EDataLength" SG_ 596 IxbrSts2Ax3_CRC 48;
BA_ "E2EProfile" SG_ 596 IxbrSts2Ax3_CRC "P01";
BA_ "GenSigCycleTime" SG_ 596 IxbrSts1Ax2_WhlRdEstmdLe 100;
BA_ "GenSigCycleTimeActive" SG_ 596 IxbrSts1Ax2_WhlRdEstmdLe 100;
BA_ "GenSigStartValue" SG_ 596 IxbrSts1Ax2_WhlRdEstmdLe 1023;
BA_ "GenSigCycleTime" SG_ 596 IxbrSts1Ax1_CRC 100;
BA_ "GenSigCycleTimeActive" SG_ 596 IxbrSts1Ax1_CRC 100;
BA_ "GenSigStartValue" SG_ 596 IxbrSts1Ax1_CRC 255;
BA_ "E2EDataId" SG_ 596 IxbrSts1Ax1_CRC 222;
BA_ "E2EDataLength" SG_ 596 IxbrSts1Ax1_CRC 40;
BA_ "E2EProfile" SG_ 596 IxbrSts1Ax1_CRC "P01";
BA_ "GenSigCycleTime" SG_ 596 IxbrSts1Ax3_SqC 100;
BA_ "GenSigCycleTimeActive" SG_ 596 IxbrSts1Ax3_SqC 100;
BA_ "GenSigStartValue" SG_ 596 IxbrSts1Ax3_SqC 14;
BA_ "GenSigCycleTime" SG_ 596 IxbrSts1Ax3_WhlRdEstmdLe 100;
BA_ "GenSigCycleTimeActive" SG_ 596 IxbrSts1Ax3_WhlRdEstmdLe 100;
BA_ "GenSigStartValue" SG_ 596 IxbrSts1Ax3_WhlRdEstmdLe 1023;
BA_ "GenSigCycleTime" SG_ 596 IxbrSts2Ax2_CRC 100;
BA_ "GenSigCycleTimeActive" SG_ 596 IxbrSts2Ax2_CRC 100;
BA_ "GenSigStartValue" SG_ 596 IxbrSts2Ax2_CRC 255;
BA_ "E2EDataId" SG_ 596 IxbrSts2Ax2_CRC 229;
BA_ "E2EDataLength" SG_ 596 IxbrSts2Ax2_CRC 48;
BA_ "E2EProfile" SG_ 596 IxbrSts2Ax2_CRC "P01";
BA_ "GenSigCycleTime" SG_ 596 IxbrSts2Ax2_WhlSlipLimBrkngRi 100;
BA_ "GenSigCycleTimeActive" SG_ 596 IxbrSts2Ax2_WhlSlipLimBrkngRi 100;
BA_ "GenSigStartValue" SG_ 596 IxbrSts2Ax2_WhlSlipLimBrkngRi 255;
BA_ "GenSigCycleTime" SG_ 596 IxbrSts2Ax1_WhlSlipLimPrpnRi 100;
BA_ "GenSigCycleTimeActive" SG_ 596 IxbrSts2Ax1_WhlSlipLimPrpnRi 100;
BA_ "GenSigStartValue" SG_ 596 IxbrSts2Ax1_WhlSlipLimPrpnRi 255;
BA_ "GenSigCycleTime" SG_ 596 IxbrSts3Ax1_WhlAccnLgtLimMinLe 100;
BA_ "GenSigCycleTimeActive" SG_ 596 IxbrSts3Ax1_WhlAccnLgtLimMinLe 100;
BA_ "GenSigStartValue" SG_ 596 IxbrSts3Ax1_WhlAccnLgtLimMinLe 511;
BA_ "GenSigCycleTime" SG_ 596 IxbrSts3Ax2_WhlAccnLgtLimMaxRi 100;
BA_ "GenSigCycleTimeActive" SG_ 596 IxbrSts3Ax2_WhlAccnLgtLimMaxRi 100;
BA_ "GenSigStartValue" SG_ 596 IxbrSts3Ax2_WhlAccnLgtLimMaxRi 511;
BA_ "GenSigCycleTime" SG_ 596 IxbrSts3Ax2_WhlAccnLgtLimMinLe 100;
BA_ "GenSigCycleTimeActive" SG_ 596 IxbrSts3Ax2_WhlAccnLgtLimMinLe 100;
BA_ "GenSigStartValue" SG_ 596 IxbrSts3Ax2_WhlAccnLgtLimMinLe 511;
BA_ "GenSigCycleTime" SG_ 596 IxbrSts2Ax2_WhlSlipLimBrkngLe 100;
BA_ "GenSigCycleTimeActive" SG_ 596 IxbrSts2Ax2_WhlSlipLimBrkngLe 100;
BA_ "GenSigStartValue" SG_ 596 IxbrSts2Ax2_WhlSlipLimBrkngLe 255;
BA_ "GenSigCycleTime" SG_ 596 IxbrSts3Ax1_WhlAccnLgtLimMaxLe 100;
BA_ "GenSigCycleTimeActive" SG_ 596 IxbrSts3Ax1_WhlAccnLgtLimMaxLe 100;
BA_ "GenSigStartValue" SG_ 596 IxbrSts3Ax1_WhlAccnLgtLimMaxLe 511;
BA_ "GenSigCycleTime" SG_ 596 IxbrSts1Ax1_WhlRdEstmdLe 100;
BA_ "GenSigCycleTimeActive" SG_ 596 IxbrSts1Ax1_WhlRdEstmdLe 100;
BA_ "GenSigStartValue" SG_ 596 IxbrSts1Ax1_WhlRdEstmdLe 1023;
BA_ "GenSigCycleTime" SG_ 596 IxbrSts2Ax1_WhlSlipLimBrkngLe 100;
BA_ "GenSigCycleTimeActive" SG_ 596 IxbrSts2Ax1_WhlSlipLimBrkngLe 100;
BA_ "GenSigStartValue" SG_ 596 IxbrSts2Ax1_WhlSlipLimBrkngLe 255;
BA_ "GenSigCycleTime" SG_ 596 IxbrSts3Ax3_SqC 100;
BA_ "GenSigCycleTimeActive" SG_ 596 IxbrSts3Ax3_SqC 100;
BA_ "GenSigStartValue" SG_ 596 IxbrSts3Ax3_SqC 14;
BA_ "GenSigCycleTime" SG_ 596 IxbrSts3Ax1_SqC 100;
BA_ "GenSigCycleTimeActive" SG_ 596 IxbrSts3Ax1_SqC 100;
BA_ "GenSigStartValue" SG_ 596 IxbrSts3Ax1_SqC 14;
BA_ "GenSigCycleTime" SG_ 596 IxbrSts3Ax1_WhlAccnLgtLimMaxRi 100;
BA_ "GenSigCycleTimeActive" SG_ 596 IxbrSts3Ax1_WhlAccnLgtLimMaxRi 100;
BA_ "GenSigStartValue" SG_ 596 IxbrSts3Ax1_WhlAccnLgtLimMaxRi 511;
BA_ "GenSigCycleTime" SG_ 596 IxbrSts2Ax3_SqC 100;
BA_ "GenSigCycleTimeActive" SG_ 596 IxbrSts2Ax3_SqC 100;
BA_ "GenSigStartValue" SG_ 596 IxbrSts2Ax3_SqC 14;
BA_ "GenSigCycleTime" SG_ 596 IxbrSts1Ax2_CRC 100;
BA_ "GenSigCycleTimeActive" SG_ 596 IxbrSts1Ax2_CRC 100;
BA_ "GenSigStartValue" SG_ 596 IxbrSts1Ax2_CRC 255;
BA_ "E2EDataId" SG_ 596 IxbrSts1Ax2_CRC 223;
BA_ "E2EDataLength" SG_ 596 IxbrSts1Ax2_CRC 40;
BA_ "E2EProfile" SG_ 596 IxbrSts1Ax2_CRC "P01";
BA_ "GenSigCycleTime" SG_ 596 IxbrSts1Ax3_CRC 100;
BA_ "GenSigCycleTimeActive" SG_ 596 IxbrSts1Ax3_CRC 100;
BA_ "GenSigStartValue" SG_ 596 IxbrSts1Ax3_CRC 255;
BA_ "E2EDataId" SG_ 596 IxbrSts1Ax3_CRC 224;
BA_ "E2EDataLength" SG_ 596 IxbrSts1Ax3_CRC 40;
BA_ "E2EProfile" SG_ 596 IxbrSts1Ax3_CRC "P01";
BA_ "GenSigCycleTime" SG_ 596 IxbrSts2Ax1_SqC 100;
BA_ "GenSigCycleTimeActive" SG_ 596 IxbrSts2Ax1_SqC 100;
BA_ "GenSigStartValue" SG_ 596 IxbrSts2Ax1_SqC 14;
BA_ "GenSigCycleTime" SG_ 596 IxbrSts3Ax3_WhlAccnLgtLimMinRi 100;
BA_ "GenSigCycleTimeActive" SG_ 596 IxbrSts3Ax3_WhlAccnLgtLimMinRi 100;
BA_ "GenSigStartValue" SG_ 596 IxbrSts3Ax3_WhlAccnLgtLimMinRi 511;
BA_ "GenSigCycleTime" SG_ 596 IxbrSts3Ax2_SqC 100;
BA_ "GenSigCycleTimeActive" SG_ 596 IxbrSts3Ax2_SqC 100;
BA_ "GenSigStartValue" SG_ 596 IxbrSts3Ax2_SqC 14;
BA_ "GenSigCycleTime" SG_ 596 IxbrSts1Ax2_WhlRdEstmdRi 100;
BA_ "GenSigCycleTimeActive" SG_ 596 IxbrSts1Ax2_WhlRdEstmdRi 100;
BA_ "GenSigStartValue" SG_ 596 IxbrSts1Ax2_WhlRdEstmdRi 1023;
BA_ "GenSigCycleTime" SG_ 596 IxbrSts1Ax2_SqC 100;
BA_ "GenSigCycleTimeActive" SG_ 596 IxbrSts1Ax2_SqC 100;
BA_ "GenSigStartValue" SG_ 596 IxbrSts1Ax2_SqC 14;
BA_ "GenSigCycleTime" SG_ 596 IxbrSts2Ax3_WhlSlipLimBrkngLe 100;
BA_ "GenSigCycleTimeActive" SG_ 596 IxbrSts2Ax3_WhlSlipLimBrkngLe 100;
BA_ "GenSigStartValue" SG_ 596 IxbrSts2Ax3_WhlSlipLimBrkngLe 255;
BA_ "GenSigCycleTime" SG_ 596 IxbrSts3Ax2_WhlAccnLgtLimMinRi 100;
BA_ "GenSigCycleTimeActive" SG_ 596 IxbrSts3Ax2_WhlAccnLgtLimMinRi 100;
BA_ "GenSigStartValue" SG_ 596 IxbrSts3Ax2_WhlAccnLgtLimMinRi 511;
BA_ "GenSigCycleTime" SG_ 596 IxbrSts3Ax2_CRC 100;
BA_ "GenSigCycleTimeActive" SG_ 596 IxbrSts3Ax2_CRC 100;
BA_ "GenSigStartValue" SG_ 596 IxbrSts3Ax2_CRC 255;
BA_ "E2EDataId" SG_ 596 IxbrSts3Ax2_CRC 235;
BA_ "E2EDataLength" SG_ 596 IxbrSts3Ax2_CRC 64;
BA_ "E2EProfile" SG_ 596 IxbrSts3Ax2_CRC "P01";
BA_ "GenSigCycleTime" SG_ 596 IxbrSts2Ax3_WhlSlipLimPrpnLe 100;
BA_ "GenSigCycleTimeActive" SG_ 596 IxbrSts2Ax3_WhlSlipLimPrpnLe 100;
BA_ "GenSigStartValue" SG_ 596 IxbrSts2Ax3_WhlSlipLimPrpnLe 255;
BA_ "GenSigCycleTime" SG_ 596 IxbrSts2Ax2_WhlSlipLimPrpnLe 100;
BA_ "GenSigCycleTimeActive" SG_ 596 IxbrSts2Ax2_WhlSlipLimPrpnLe 100;
BA_ "GenSigStartValue" SG_ 596 IxbrSts2Ax2_WhlSlipLimPrpnLe 255;
BA_ "GenSigCycleTime" SG_ 596 IxbrSts2Ax1_CRC 100;
BA_ "GenSigCycleTimeActive" SG_ 596 IxbrSts2Ax1_CRC 100;
BA_ "GenSigStartValue" SG_ 596 IxbrSts2Ax1_CRC 255;
BA_ "E2EDataId" SG_ 596 IxbrSts2Ax1_CRC 228;
BA_ "E2EDataLength" SG_ 596 IxbrSts2Ax1_CRC 48;
BA_ "E2EProfile" SG_ 596 IxbrSts2Ax1_CRC "P01";
BA_ "GenSigCycleTime" SG_ 596 IxbrSts3Ax2_WhlAccnLgtLimMaxLe 100;
BA_ "GenSigCycleTimeActive" SG_ 596 IxbrSts3Ax2_WhlAccnLgtLimMaxLe 100;
BA_ "GenSigStartValue" SG_ 596 IxbrSts3Ax2_WhlAccnLgtLimMaxLe 511;
BA_ "GenSigCycleTime" SG_ 596 IxbrSts3Ax3_WhlAccnLgtLimMaxRi 100;
BA_ "GenSigCycleTimeActive" SG_ 596 IxbrSts3Ax3_WhlAccnLgtLimMaxRi 100;
BA_ "GenSigStartValue" SG_ 596 IxbrSts3Ax3_WhlAccnLgtLimMaxRi 511;
BA_ "GenSigCycleTime" SG_ 596 IxbrSts1Ax3_WhlRdEstmdRi 100;
BA_ "GenSigCycleTimeActive" SG_ 596 IxbrSts1Ax3_WhlRdEstmdRi 100;
BA_ "GenSigStartValue" SG_ 596 IxbrSts1Ax3_WhlRdEstmdRi 1023;
BA_ "GenSigCycleTime" SG_ 596 IxbrSts2Ax1_WhlSlipLimBrkngRi 100;
BA_ "GenSigCycleTimeActive" SG_ 596 IxbrSts2Ax1_WhlSlipLimBrkngRi 100;
BA_ "GenSigStartValue" SG_ 596 IxbrSts2Ax1_WhlSlipLimBrkngRi 255;
BA_ "GenSigCycleTime" SG_ 596 IxbrSts2Ax2_SqC 100;
BA_ "GenSigCycleTimeActive" SG_ 596 IxbrSts2Ax2_SqC 100;
BA_ "GenSigStartValue" SG_ 596 IxbrSts2Ax2_SqC 14;
BA_ "GenSigCycleTime" SG_ 596 IxbrSts2Ax2_WhlSlipLimPrpnRi 100;
BA_ "GenSigCycleTimeActive" SG_ 596 IxbrSts2Ax2_WhlSlipLimPrpnRi 100;
BA_ "GenSigStartValue" SG_ 596 IxbrSts2Ax2_WhlSlipLimPrpnRi 255;
BA_ "GenSigCycleTime" SG_ 298 Imu_LgtAccnQlty 100;
BA_ "GenSigCycleTimeActive" SG_ 298 Imu_LgtAccnQlty 100;
BA_ "GenSigStartValue" SG_ 298 Imu_LgtAccnQlty 3;
BA_ "GenSigCycleTime" SG_ 298 Imu_AccnLat 100;
BA_ "GenSigCycleTimeActive" SG_ 298 Imu_AccnLat 100;
BA_ "GenSigStartValue" SG_ 298 Imu_AccnLat 65535;
BA_ "GenSigCycleTime" SG_ 298 Imu_PitchRate 100;
BA_ "GenSigCycleTimeActive" SG_ 298 Imu_PitchRate 100;
BA_ "GenSigStartValue" SG_ 298 Imu_PitchRate 65535;
BA_ "GenSigCycleTime" SG_ 298 Imu_YawRate 100;
BA_ "GenSigCycleTimeActive" SG_ 298 Imu_YawRate 100;
BA_ "GenSigStartValue" SG_ 298 Imu_YawRate 65535;
BA_ "GenSigCycleTime" SG_ 298 Imu_Temp 100;
BA_ "GenSigCycleTimeActive" SG_ 298 Imu_Temp 100;
BA_ "GenSigStartValue" SG_ 298 Imu_Temp 255;
BA_ "GenSigCycleTime" SG_ 298 Imu_RollRate 100;
BA_ "GenSigCycleTimeActive" SG_ 298 Imu_RollRate 100;
BA_ "GenSigStartValue" SG_ 298 Imu_RollRate 65535;
BA_ "GenSigCycleTime" SG_ 298 Imu_YawRateQlty 100;
BA_ "GenSigCycleTimeActive" SG_ 298 Imu_YawRateQlty 100;
BA_ "GenSigStartValue" SG_ 298 Imu_YawRateQlty 3;
BA_ "GenSigCycleTime" SG_ 298 Imu_PitchRateQlty 100;
BA_ "GenSigCycleTimeActive" SG_ 298 Imu_PitchRateQlty 100;
BA_ "GenSigStartValue" SG_ 298 Imu_PitchRateQlty 3;
BA_ "GenSigCycleTime" SG_ 298 Imu_RollRateQlty 100;
BA_ "GenSigCycleTimeActive" SG_ 298 Imu_RollRateQlty 100;
BA_ "GenSigStartValue" SG_ 298 Imu_RollRateQlty 3;
BA_ "GenSigCycleTime" SG_ 298 Imu_LgtAccn 100;
BA_ "GenSigCycleTimeActive" SG_ 298 Imu_LgtAccn 100;
BA_ "GenSigStartValue" SG_ 298 Imu_LgtAccn 65535;
BA_ "GenSigCycleTime" SG_ 298 Imu_SqC 100;
BA_ "GenSigCycleTimeActive" SG_ 298 Imu_SqC 100;
BA_ "GenSigStartValue" SG_ 298 Imu_SqC 14;
BA_ "GenSigCycleTime" SG_ 298 Imu_CRC 100;
BA_ "GenSigCycleTimeActive" SG_ 298 Imu_CRC 100;
BA_ "GenSigStartValue" SG_ 298 Imu_CRC 255;
BA_ "E2EDataId" SG_ 298 Imu_CRC 182;
BA_ "E2EDataLength" SG_ 298 Imu_CRC 128;
BA_ "E2EProfile" SG_ 298 Imu_CRC "P01";
BA_ "GenSigCycleTime" SG_ 298 Imu_AccnLatQlty 100;
BA_ "GenSigCycleTimeActive" SG_ 298 Imu_AccnLatQlty 100;
BA_ "GenSigStartValue" SG_ 298 Imu_AccnLatQlty 3;
BA_ "GenSigCycleTime" SG_ 298 Imu_AccnVertQlty 100;
BA_ "GenSigCycleTimeActive" SG_ 298 Imu_AccnVertQlty 100;
BA_ "GenSigStartValue" SG_ 298 Imu_AccnVertQlty 3;
BA_ "GenSigCycleTime" SG_ 298 Imu_AccnVert 100;
BA_ "GenSigCycleTimeActive" SG_ 298 Imu_AccnVert 100;
BA_ "GenSigStartValue" SG_ 298 Imu_AccnVert 65535;
BA_ "GenSigCycleTime" SG_ 594 CpbtyAxle5_BrkEgyCpctyLe 100;
BA_ "GenSigCycleTimeActive" SG_ 594 CpbtyAxle5_BrkEgyCpctyLe 100;
BA_ "GenSigStartValue" SG_ 594 CpbtyAxle5_BrkEgyCpctyLe 255;
BA_ "GenSigCycleTime" SG_ 594 CpbtyAxle4_TqCpbtyRateQltyLe 100;
BA_ "GenSigCycleTimeActive" SG_ 594 CpbtyAxle4_TqCpbtyRateQltyLe 100;
BA_ "GenSigStartValue" SG_ 594 CpbtyAxle4_TqCpbtyRateQltyLe 3;
BA_ "GenSigCycleTime" SG_ 594 CpbtyAxle4_TqCpbtyRateDecRi 100;
BA_ "GenSigCycleTimeActive" SG_ 594 CpbtyAxle4_TqCpbtyRateDecRi 100;
BA_ "GenSigStartValue" SG_ 594 CpbtyAxle4_TqCpbtyRateDecRi 255;
BA_ "GenSigCycleTime" SG_ 594 CpbtyAxle4_BrkEgyCpctyQltyRi 100;
BA_ "GenSigCycleTimeActive" SG_ 594 CpbtyAxle4_BrkEgyCpctyQltyRi 100;
BA_ "GenSigStartValue" SG_ 594 CpbtyAxle4_BrkEgyCpctyQltyRi 3;
BA_ "GenSigCycleTime" SG_ 594 CpbtyAxle4_TqCpbtyMinRi 100;
BA_ "GenSigCycleTimeActive" SG_ 594 CpbtyAxle4_TqCpbtyMinRi 100;
BA_ "GenSigStartValue" SG_ 594 CpbtyAxle4_TqCpbtyMinRi 1023;
BA_ "GenSigCycleTime" SG_ 594 CpbtyAxle5_TqCpbtyMaxLe 100;
BA_ "GenSigCycleTimeActive" SG_ 594 CpbtyAxle5_TqCpbtyMaxLe 100;
BA_ "GenSigStartValue" SG_ 594 CpbtyAxle5_TqCpbtyMaxLe 1023;
BA_ "GenSigCycleTime" SG_ 594 CpbtyAxle5_TqCpbtyQltyLe 100;
BA_ "GenSigCycleTimeActive" SG_ 594 CpbtyAxle5_TqCpbtyQltyLe 100;
BA_ "GenSigStartValue" SG_ 594 CpbtyAxle5_TqCpbtyQltyLe 3;
BA_ "GenSigCycleTime" SG_ 594 CpbtyAxle5_PadWearRi 100;
BA_ "GenSigCycleTimeActive" SG_ 594 CpbtyAxle5_PadWearRi 100;
BA_ "GenSigStartValue" SG_ 594 CpbtyAxle5_PadWearRi 255;
BA_ "GenSigCycleTime" SG_ 594 CpbtyAxle5_TqCpbtyRateIncLeRi 100;
BA_ "GenSigCycleTimeActive" SG_ 594 CpbtyAxle5_TqCpbtyRateIncLeRi 100;
BA_ "GenSigStartValue" SG_ 594 CpbtyAxle5_TqCpbtyRateIncLeRi 255;
BA_ "GenSigCycleTime" SG_ 594 CpbtyAxle6_TqCpbtyRateQltyLe 100;
BA_ "GenSigCycleTimeActive" SG_ 594 CpbtyAxle6_TqCpbtyRateQltyLe 100;
BA_ "GenSigStartValue" SG_ 594 CpbtyAxle6_TqCpbtyRateQltyLe 3;
BA_ "GenSigCycleTime" SG_ 594 CpbtyAxle5_TqCpbtyRateDecLe 100;
BA_ "GenSigCycleTimeActive" SG_ 594 CpbtyAxle5_TqCpbtyRateDecLe 100;
BA_ "GenSigStartValue" SG_ 594 CpbtyAxle5_TqCpbtyRateDecLe 255;
BA_ "GenSigCycleTime" SG_ 594 CpbtyAxle6_TqCpbtyMinRi 100;
BA_ "GenSigCycleTimeActive" SG_ 594 CpbtyAxle6_TqCpbtyMinRi 100;
BA_ "GenSigStartValue" SG_ 594 CpbtyAxle6_TqCpbtyMinRi 1023;
BA_ "GenSigCycleTime" SG_ 594 CpbtyAxle6_BrkEgyCpctyRi 100;
BA_ "GenSigCycleTimeActive" SG_ 594 CpbtyAxle6_BrkEgyCpctyRi 100;
BA_ "GenSigStartValue" SG_ 594 CpbtyAxle6_BrkEgyCpctyRi 255;
BA_ "GenSigCycleTime" SG_ 594 CpbtyAxle6_TqCpbtyRateQltyRi 100;
BA_ "GenSigCycleTimeActive" SG_ 594 CpbtyAxle6_TqCpbtyRateQltyRi 100;
BA_ "GenSigStartValue" SG_ 594 CpbtyAxle6_TqCpbtyRateQltyRi 3;
BA_ "GenSigCycleTime" SG_ 594 CpbtyAxle6_TqCpbtyRateIncLeRi 100;
BA_ "GenSigCycleTimeActive" SG_ 594 CpbtyAxle6_TqCpbtyRateIncLeRi 100;
BA_ "GenSigStartValue" SG_ 594 CpbtyAxle6_TqCpbtyRateIncLeRi 255;
BA_ "GenSigCycleTime" SG_ 594 CpbtyAxle5_TqCpbtyMaxRi 100;
BA_ "GenSigCycleTimeActive" SG_ 594 CpbtyAxle5_TqCpbtyMaxRi 100;
BA_ "GenSigStartValue" SG_ 594 CpbtyAxle5_TqCpbtyMaxRi 1023;
BA_ "GenSigCycleTime" SG_ 594 CpbtyAxle5_CRC 100;
BA_ "GenSigCycleTimeActive" SG_ 594 CpbtyAxle5_CRC 100;
BA_ "GenSigStartValue" SG_ 594 CpbtyAxle5_CRC 65535;
BA_ "E2EDataId" SG_ 594 CpbtyAxle5_CRC 193;
BA_ "E2EDataLength" SG_ 594 CpbtyAxle5_CRC 152;
BA_ "E2EProfile" SG_ 594 CpbtyAxle5_CRC "P05";
BA_ "GenSigCycleTime" SG_ 594 CpbtyAxle6_TqCpbtyRateDecLe 100;
BA_ "GenSigCycleTimeActive" SG_ 594 CpbtyAxle6_TqCpbtyRateDecLe 100;
BA_ "GenSigStartValue" SG_ 594 CpbtyAxle6_TqCpbtyRateDecLe 255;
BA_ "GenSigCycleTime" SG_ 594 CpbtyAxle5_SlipCtrlEna 100;
BA_ "GenSigCycleTimeActive" SG_ 594 CpbtyAxle5_SlipCtrlEna 100;
BA_ "GenSigStartValue" SG_ 594 CpbtyAxle5_SlipCtrlEna 3;
BA_ "GenSigCycleTime" SG_ 594 CpbtyAxle5_PadWearQltyLe 100;
BA_ "GenSigCycleTimeActive" SG_ 594 CpbtyAxle5_PadWearQltyLe 100;
BA_ "GenSigStartValue" SG_ 594 CpbtyAxle5_PadWearQltyLe 3;
BA_ "GenSigCycleTime" SG_ 594 CpbtyAxle6_BrkEgyCpctyQltyRi 100;
BA_ "GenSigCycleTimeActive" SG_ 594 CpbtyAxle6_BrkEgyCpctyQltyRi 100;
BA_ "GenSigStartValue" SG_ 594 CpbtyAxle6_BrkEgyCpctyQltyRi 3;
BA_ "GenSigCycleTime" SG_ 594 CpbtyAxle5_BrkEgyCpctyQltyLe 100;
BA_ "GenSigCycleTimeActive" SG_ 594 CpbtyAxle5_BrkEgyCpctyQltyLe 100;
BA_ "GenSigStartValue" SG_ 594 CpbtyAxle5_BrkEgyCpctyQltyLe 3;
BA_ "GenSigCycleTime" SG_ 594 CpbtyAxle6_PadWearQltyRi 100;
BA_ "GenSigCycleTimeActive" SG_ 594 CpbtyAxle6_PadWearQltyRi 100;
BA_ "GenSigStartValue" SG_ 594 CpbtyAxle6_PadWearQltyRi 3;
BA_ "GenSigCycleTime" SG_ 594 CpbtyAxle6_TqCpbtyMaxRi 100;
BA_ "GenSigCycleTimeActive" SG_ 594 CpbtyAxle6_TqCpbtyMaxRi 100;
BA_ "GenSigStartValue" SG_ 594 CpbtyAxle6_TqCpbtyMaxRi 1023;
BA_ "GenSigCycleTime" SG_ 594 CpbtyAxle4_TqCpbtyQltyLe 100;
BA_ "GenSigCycleTimeActive" SG_ 594 CpbtyAxle4_TqCpbtyQltyLe 100;
BA_ "GenSigStartValue" SG_ 594 CpbtyAxle4_TqCpbtyQltyLe 3;
BA_ "GenSigCycleTime" SG_ 594 CpbtyAxle4_SlipCtrlEna 100;
BA_ "GenSigCycleTimeActive" SG_ 594 CpbtyAxle4_SlipCtrlEna 100;
BA_ "GenSigStartValue" SG_ 594 CpbtyAxle4_SlipCtrlEna 3;
BA_ "GenSigCycleTime" SG_ 594 CpbtyAxle4_BrkEgyCpctyRi 100;
BA_ "GenSigCycleTimeActive" SG_ 594 CpbtyAxle4_BrkEgyCpctyRi 100;
BA_ "GenSigStartValue" SG_ 594 CpbtyAxle4_BrkEgyCpctyRi 255;
BA_ "GenSigCycleTime" SG_ 594 CpbtyAxle6_TqCpbtyQltyRi 100;
BA_ "GenSigCycleTimeActive" SG_ 594 CpbtyAxle6_TqCpbtyQltyRi 100;
BA_ "GenSigStartValue" SG_ 594 CpbtyAxle6_TqCpbtyQltyRi 3;
BA_ "GenSigCycleTime" SG_ 594 CpbtyAxle6_CRC 100;
BA_ "GenSigCycleTimeActive" SG_ 594 CpbtyAxle6_CRC 100;
BA_ "GenSigStartValue" SG_ 594 CpbtyAxle6_CRC 65535;
BA_ "E2EDataId" SG_ 594 CpbtyAxle6_CRC 194;
BA_ "E2EDataLength" SG_ 594 CpbtyAxle6_CRC 152;
BA_ "E2EProfile" SG_ 594 CpbtyAxle6_CRC "P05";
BA_ "GenSigCycleTime" SG_ 594 CpbtyAxle5_TqCpbtyRateQltyLe 100;
BA_ "GenSigCycleTimeActive" SG_ 594 CpbtyAxle5_TqCpbtyRateQltyLe 100;
BA_ "GenSigStartValue" SG_ 594 CpbtyAxle5_TqCpbtyRateQltyLe 3;
BA_ "GenSigCycleTime" SG_ 594 CpbtyAxle4_TqCpbtyMaxLe 100;
BA_ "GenSigCycleTimeActive" SG_ 594 CpbtyAxle4_TqCpbtyMaxLe 100;
BA_ "GenSigStartValue" SG_ 594 CpbtyAxle4_TqCpbtyMaxLe 1023;
BA_ "GenSigCycleTime" SG_ 594 CpbtyAxle4_PadWearRi 100;
BA_ "GenSigCycleTimeActive" SG_ 594 CpbtyAxle4_PadWearRi 100;
BA_ "GenSigStartValue" SG_ 594 CpbtyAxle4_PadWearRi 255;
BA_ "GenSigCycleTime" SG_ 594 CpbtyAxle6_TqCpbtyMinLe 100;
BA_ "GenSigCycleTimeActive" SG_ 594 CpbtyAxle6_TqCpbtyMinLe 100;
BA_ "GenSigStartValue" SG_ 594 CpbtyAxle6_TqCpbtyMinLe 1023;
BA_ "GenSigCycleTime" SG_ 594 CpbtyAxle4_CRC 100;
BA_ "GenSigCycleTimeActive" SG_ 594 CpbtyAxle4_CRC 100;
BA_ "GenSigStartValue" SG_ 594 CpbtyAxle4_CRC 65535;
BA_ "E2EDataId" SG_ 594 CpbtyAxle4_CRC 192;
BA_ "E2EDataLength" SG_ 594 CpbtyAxle4_CRC 152;
BA_ "E2EProfile" SG_ 594 CpbtyAxle4_CRC "P05";
BA_ "GenSigCycleTime" SG_ 594 CpbtyAxle4_SqC 100;
BA_ "GenSigCycleTimeActive" SG_ 594 CpbtyAxle4_SqC 100;
BA_ "GenSigStartValue" SG_ 594 CpbtyAxle4_SqC 255;
BA_ "GenSigCycleTime" SG_ 594 CpbtyAxle5_TqCpbtyMinLe 100;
BA_ "GenSigCycleTimeActive" SG_ 594 CpbtyAxle5_TqCpbtyMinLe 100;
BA_ "GenSigStartValue" SG_ 594 CpbtyAxle5_TqCpbtyMinLe 1023;
BA_ "GenSigCycleTime" SG_ 594 CpbtyAxle6_PadWearQltyLe 100;
BA_ "GenSigCycleTimeActive" SG_ 594 CpbtyAxle6_PadWearQltyLe 100;
BA_ "GenSigStartValue" SG_ 594 CpbtyAxle6_PadWearQltyLe 3;
BA_ "GenSigCycleTime" SG_ 594 CpbtyAxle6_PadWearRi 100;
BA_ "GenSigCycleTimeActive" SG_ 594 CpbtyAxle6_PadWearRi 100;
BA_ "GenSigStartValue" SG_ 594 CpbtyAxle6_PadWearRi 255;
BA_ "GenSigCycleTime" SG_ 594 CpbtyAxle5_TqCpbtyRateQltyRi 100;
BA_ "GenSigCycleTimeActive" SG_ 594 CpbtyAxle5_TqCpbtyRateQltyRi 100;
BA_ "GenSigStartValue" SG_ 594 CpbtyAxle5_TqCpbtyRateQltyRi 3;
BA_ "GenSigCycleTime" SG_ 594 CpbtyAxle4_TqCpbtyQltyRi 100;
BA_ "GenSigCycleTimeActive" SG_ 594 CpbtyAxle4_TqCpbtyQltyRi 100;
BA_ "GenSigStartValue" SG_ 594 CpbtyAxle4_TqCpbtyQltyRi 3;
BA_ "GenSigCycleTime" SG_ 594 CpbtyAxle6_SlipCtrlEna 100;
BA_ "GenSigCycleTimeActive" SG_ 594 CpbtyAxle6_SlipCtrlEna 100;
BA_ "GenSigStartValue" SG_ 594 CpbtyAxle6_SlipCtrlEna 3;
BA_ "GenSigCycleTime" SG_ 594 CpbtyAxle5_TqCpbtyQltyRi 100;
BA_ "GenSigCycleTimeActive" SG_ 594 CpbtyAxle5_TqCpbtyQltyRi 100;
BA_ "GenSigStartValue" SG_ 594 CpbtyAxle5_TqCpbtyQltyRi 3;
BA_ "GenSigCycleTime" SG_ 594 CpbtyAxle4_BrkEgyCpctyQltyLe 100;
BA_ "GenSigCycleTimeActive" SG_ 594 CpbtyAxle4_BrkEgyCpctyQltyLe 100;
BA_ "GenSigStartValue" SG_ 594 CpbtyAxle4_BrkEgyCpctyQltyLe 3;
BA_ "GenSigCycleTime" SG_ 594 CpbtyAxle4_TqCpbtyMinLe 100;
BA_ "GenSigCycleTimeActive" SG_ 594 CpbtyAxle4_TqCpbtyMinLe 100;
BA_ "GenSigStartValue" SG_ 594 CpbtyAxle4_TqCpbtyMinLe 1023;
BA_ "GenSigCycleTime" SG_ 594 CpbtyAxle5_TqCpbtyMinRi 100;
BA_ "GenSigCycleTimeActive" SG_ 594 CpbtyAxle5_TqCpbtyMinRi 100;
BA_ "GenSigStartValue" SG_ 594 CpbtyAxle5_TqCpbtyMinRi 1023;
BA_ "GenSigCycleTime" SG_ 594 CpbtyAxle6_SqC 100;
BA_ "GenSigCycleTimeActive" SG_ 594 CpbtyAxle6_SqC 100;
BA_ "GenSigStartValue" SG_ 594 CpbtyAxle6_SqC 255;
BA_ "GenSigCycleTime" SG_ 594 CpbtyAxle6_TqCpbtyRateDecRi 100;
BA_ "GenSigCycleTimeActive" SG_ 594 CpbtyAxle6_TqCpbtyRateDecRi 100;
BA_ "GenSigStartValue" SG_ 594 CpbtyAxle6_TqCpbtyRateDecRi 255;
BA_ "GenSigCycleTime" SG_ 594 CpbtyAxle6_TqCpbtyRateIncLeLe 100;
BA_ "GenSigCycleTimeActive" SG_ 594 CpbtyAxle6_TqCpbtyRateIncLeLe 100;
BA_ "GenSigStartValue" SG_ 594 CpbtyAxle6_TqCpbtyRateIncLeLe 255;
BA_ "GenSigCycleTime" SG_ 594 CpbtyAxle4_TqCpbtyRateDecLe 100;
BA_ "GenSigCycleTimeActive" SG_ 594 CpbtyAxle4_TqCpbtyRateDecLe 100;
BA_ "GenSigStartValue" SG_ 594 CpbtyAxle4_TqCpbtyRateDecLe 255;
BA_ "GenSigCycleTime" SG_ 594 CpbtyAxle4_TqCpbtyRateQltyRi 100;
BA_ "GenSigCycleTimeActive" SG_ 594 CpbtyAxle4_TqCpbtyRateQltyRi 100;
BA_ "GenSigStartValue" SG_ 594 CpbtyAxle4_TqCpbtyRateQltyRi 3;
BA_ "GenSigCycleTime" SG_ 594 CpbtyAxle4_BrkEgyCpctyLe 100;
BA_ "GenSigCycleTimeActive" SG_ 594 CpbtyAxle4_BrkEgyCpctyLe 100;
BA_ "GenSigStartValue" SG_ 594 CpbtyAxle4_BrkEgyCpctyLe 255;
BA_ "GenSigCycleTime" SG_ 594 CpbtyAxle4_TqCpbtyMaxRi 100;
BA_ "GenSigCycleTimeActive" SG_ 594 CpbtyAxle4_TqCpbtyMaxRi 100;
BA_ "GenSigStartValue" SG_ 594 CpbtyAxle4_TqCpbtyMaxRi 1023;
BA_ "GenSigCycleTime" SG_ 594 CpbtyAxle6_TqCpbtyMaxLe 100;
BA_ "GenSigCycleTimeActive" SG_ 594 CpbtyAxle6_TqCpbtyMaxLe 100;
BA_ "GenSigStartValue" SG_ 594 CpbtyAxle6_TqCpbtyMaxLe 1023;
BA_ "GenSigCycleTime" SG_ 594 CpbtyAxle5_TqCpbtyRateIncLeLe 100;
BA_ "GenSigCycleTimeActive" SG_ 594 CpbtyAxle5_TqCpbtyRateIncLeLe 100;
BA_ "GenSigStartValue" SG_ 594 CpbtyAxle5_TqCpbtyRateIncLeLe 255;
BA_ "GenSigCycleTime" SG_ 594 CpbtyAxle5_PadWearQltyRi 100;
BA_ "GenSigCycleTimeActive" SG_ 594 CpbtyAxle5_PadWearQltyRi 100;
BA_ "GenSigStartValue" SG_ 594 CpbtyAxle5_PadWearQltyRi 3;
BA_ "GenSigCycleTime" SG_ 594 CpbtyAxle6_BrkEgyCpctyQltyLe 100;
BA_ "GenSigCycleTimeActive" SG_ 594 CpbtyAxle6_BrkEgyCpctyQltyLe 100;
BA_ "GenSigStartValue" SG_ 594 CpbtyAxle6_BrkEgyCpctyQltyLe 3;
BA_ "GenSigCycleTime" SG_ 594 CpbtyAxle5_TqCpbtyRateDecRi 100;
BA_ "GenSigCycleTimeActive" SG_ 594 CpbtyAxle5_TqCpbtyRateDecRi 100;
BA_ "GenSigStartValue" SG_ 594 CpbtyAxle5_TqCpbtyRateDecRi 255;
BA_ "GenSigCycleTime" SG_ 594 CpbtyAxle6_TqCpbtyQltyLe 100;
BA_ "GenSigCycleTimeActive" SG_ 594 CpbtyAxle6_TqCpbtyQltyLe 100;
BA_ "GenSigStartValue" SG_ 594 CpbtyAxle6_TqCpbtyQltyLe 3;
BA_ "GenSigCycleTime" SG_ 594 CpbtyAxle5_SqC 100;
BA_ "GenSigCycleTimeActive" SG_ 594 CpbtyAxle5_SqC 100;
BA_ "GenSigStartValue" SG_ 594 CpbtyAxle5_SqC 255;
BA_ "GenSigCycleTime" SG_ 594 CpbtyAxle4_TqCpbtyRateIncLeRi 100;
BA_ "GenSigCycleTimeActive" SG_ 594 CpbtyAxle4_TqCpbtyRateIncLeRi 100;
BA_ "GenSigStartValue" SG_ 594 CpbtyAxle4_TqCpbtyRateIncLeRi 255;
BA_ "GenSigCycleTime" SG_ 594 CpbtyAxle6_BrkEgyCpctyLe 100;
BA_ "GenSigCycleTimeActive" SG_ 594 CpbtyAxle6_BrkEgyCpctyLe 100;
BA_ "GenSigStartValue" SG_ 594 CpbtyAxle6_BrkEgyCpctyLe 255;
BA_ "GenSigCycleTime" SG_ 594 CpbtyAxle5_BrkEgyCpctyRi 100;
BA_ "GenSigCycleTimeActive" SG_ 594 CpbtyAxle5_BrkEgyCpctyRi 100;
BA_ "GenSigStartValue" SG_ 594 CpbtyAxle5_BrkEgyCpctyRi 255;
BA_ "GenSigCycleTime" SG_ 594 CpbtyAxle5_BrkEgyCpctyQltyRi 100;
BA_ "GenSigCycleTimeActive" SG_ 594 CpbtyAxle5_BrkEgyCpctyQltyRi 100;
BA_ "GenSigStartValue" SG_ 594 CpbtyAxle5_BrkEgyCpctyQltyRi 3;
BA_ "GenSigCycleTime" SG_ 594 CpbtyAxle6_PadWearLe 100;
BA_ "GenSigCycleTimeActive" SG_ 594 CpbtyAxle6_PadWearLe 100;
BA_ "GenSigStartValue" SG_ 594 CpbtyAxle6_PadWearLe 255;
BA_ "GenSigCycleTime" SG_ 594 CpbtyAxle4_PadWearLe 100;
BA_ "GenSigCycleTimeActive" SG_ 594 CpbtyAxle4_PadWearLe 100;
BA_ "GenSigStartValue" SG_ 594 CpbtyAxle4_PadWearLe 255;
BA_ "GenSigCycleTime" SG_ 594 CpbtyAxle4_PadWearQltyRi 100;
BA_ "GenSigCycleTimeActive" SG_ 594 CpbtyAxle4_PadWearQltyRi 100;
BA_ "GenSigStartValue" SG_ 594 CpbtyAxle4_PadWearQltyRi 3;
BA_ "GenSigCycleTime" SG_ 594 CpbtyAxle4_TqCpbtyRateIncLeLe 100;
BA_ "GenSigCycleTimeActive" SG_ 594 CpbtyAxle4_TqCpbtyRateIncLeLe 100;
BA_ "GenSigStartValue" SG_ 594 CpbtyAxle4_TqCpbtyRateIncLeLe 255;
BA_ "GenSigCycleTime" SG_ 594 CpbtyAxle5_PadWearLe 100;
BA_ "GenSigCycleTimeActive" SG_ 594 CpbtyAxle5_PadWearLe 100;
BA_ "GenSigStartValue" SG_ 594 CpbtyAxle5_PadWearLe 255;
BA_ "GenSigCycleTime" SG_ 594 CpbtyAxle4_PadWearQltyLe 100;
BA_ "GenSigCycleTimeActive" SG_ 594 CpbtyAxle4_PadWearQltyLe 100;
BA_ "GenSigStartValue" SG_ 594 CpbtyAxle4_PadWearQltyLe 3;
BA_REL_ "GenSigFirstTimeoutTime" BU_SG_REL_ VCM SG_ 1456 FasUsrDefLowSpeedReturnSetting_I 6000;
BA_REL_ "GenSigTimeoutTime" BU_SG_REL_ VCM SG_ 1456 FasUsrDefLowSpeedReturnSetting_I 3000;
BA_REL_ "GenSigFirstTimeoutTime" BU_SG_REL_ VCM SG_ 1456 ActualFasManualOffsetSetting_ISi 6000;
BA_REL_ "GenSigTimeoutTime" BU_SG_REL_ VCM SG_ 1456 ActualFasManualOffsetSetting_ISi 3000;
BA_REL_ "GenSigFirstTimeoutTime" BU_SG_REL_ VCM SG_ 1456 FasUsrDefStiffnessCurveSetting_I 6000;
BA_REL_ "GenSigTimeoutTime" BU_SG_REL_ VCM SG_ 1456 FasUsrDefStiffnessCurveSetting_I 3000;
BA_REL_ "GenSigFirstTimeoutTime" BU_SG_REL_ VCM SG_ 1456 FasUsrDefinedDampingSetting_ISig 6000;
BA_REL_ "GenSigTimeoutTime" BU_SG_REL_ VCM SG_ 1456 FasUsrDefinedDampingSetting_ISig 3000;
BA_REL_ "GenSigFirstTimeoutTime" BU_SG_REL_ VCM SG_ 1456 FasUsrDefStiffStraightSetting_IS 6000;
BA_REL_ "GenSigTimeoutTime" BU_SG_REL_ VCM SG_ 1456 FasUsrDefStiffStraightSetting_IS 3000;
BA_REL_ "GenSigFirstTimeoutTime" BU_SG_REL_ VCM SG_ 1456 FasDriver_ISig_3 6000;
BA_REL_ "GenSigTimeoutTime" BU_SG_REL_ VCM SG_ 1456 FasDriver_ISig_3 3000;
BA_REL_ "GenSigFirstTimeoutTime" BU_SG_REL_ VCM SG_ 1456 ActualFasPersSettingsButton_ISig 6000;
BA_REL_ "GenSigTimeoutTime" BU_SG_REL_ VCM SG_ 1456 ActualFasPersSettingsButton_ISig 3000;
BA_REL_ "GenSigFirstTimeoutTime" BU_SG_REL_ VCM SG_ 455 DriverSteeringTqEstimateConf 3000;
BA_REL_ "GenSigTimeoutTime" BU_SG_REL_ VCM SG_ 455 DriverSteeringTqEstimateConf 120;
BA_REL_ "GenSigFirstTimeoutTime" BU_SG_REL_ VCM SG_ 455 OverSteerGuidanceStatus_ISig_3 3000;
BA_REL_ "GenSigTimeoutTime" BU_SG_REL_ VCM SG_ 455 OverSteerGuidanceStatus_ISig_3 120;
BA_REL_ "GenSigFirstTimeoutTime" BU_SG_REL_ VCM SG_ 455 FASFullyOperational 3000;
BA_REL_ "GenSigTimeoutTime" BU_SG_REL_ VCM SG_ 455 FASFullyOperational 120;
BA_REL_ "GenSigFirstTimeoutTime" BU_SG_REL_ VCM SG_ 455 DriverSteeringTorqueEstimate 3000;
BA_REL_ "GenSigTimeoutTime" BU_SG_REL_ VCM SG_ 455 DriverSteeringTorqueEstimate 120;
BA_REL_ "GenSigFirstTimeoutTime" BU_SG_REL_ VCM SG_ 455 FASSaturated 3000;
BA_REL_ "GenSigTimeoutTime" BU_SG_REL_ VCM SG_ 455 FASSaturated 120;
BA_REL_ "GenSigFirstTimeoutTime" BU_SG_REL_ VCM SG_ 455 FrontRoadWheelAngleEstimate 3000;
BA_REL_ "GenSigTimeoutTime" BU_SG_REL_ VCM SG_ 455 FrontRoadWheelAngleEstimate 120;
BA_REL_ "GenSigFirstTimeoutTime" BU_SG_REL_ VCM SG_ 455 FASFunctionInControl 3000;
BA_REL_ "GenSigTimeoutTime" BU_SG_REL_ VCM SG_ 455 FASFunctionInControl 120;
BA_REL_ "GenSigFirstTimeoutTime" BU_SG_REL_ VCM SG_ 275 RoadWheelAngleResp_RateCap 3000;
BA_REL_ "GenSigTimeoutTime" BU_SG_REL_ VCM SG_ 275 RoadWheelAngleResp_RateCap 100;
BA_REL_ "GenSigFirstTimeoutTime" BU_SG_REL_ VCM SG_ 275 RoadWheelAngleResp_CRC 3000;
BA_REL_ "GenSigTimeoutTime" BU_SG_REL_ VCM SG_ 275 RoadWheelAngleResp_CRC 100;
BA_REL_ "GenSigFirstTimeoutTime" BU_SG_REL_ VCM SG_ 275 SteeringCtrlModeRsp_CRC 3000;
BA_REL_ "GenSigTimeoutTime" BU_SG_REL_ VCM SG_ 275 SteeringCtrlModeRsp_CRC 100;
BA_REL_ "GenSigFirstTimeoutTime" BU_SG_REL_ VCM SG_ 275 SteeringWheelTorque_SqC 3000;
BA_REL_ "GenSigTimeoutTime" BU_SG_REL_ VCM SG_ 275 SteeringWheelTorque_SqC 100;
BA_REL_ "GenSigFirstTimeoutTime" BU_SG_REL_ VCM SG_ 275 SteeringWheelTorque_CRC 3000;
BA_REL_ "GenSigTimeoutTime" BU_SG_REL_ VCM SG_ 275 SteeringWheelTorque_CRC 100;
BA_REL_ "GenSigFirstTimeoutTime" BU_SG_REL_ VCM SG_ 275 SteeringCtrlModeRsp_Status 3000;
BA_REL_ "GenSigTimeoutTime" BU_SG_REL_ VCM SG_ 275 SteeringCtrlModeRsp_Status 100;
BA_REL_ "GenSigFirstTimeoutTime" BU_SG_REL_ VCM SG_ 275 SteeringCtrlModeRsp_SqC 3000;
BA_REL_ "GenSigTimeoutTime" BU_SG_REL_ VCM SG_ 275 SteeringCtrlModeRsp_SqC 100;
BA_REL_ "GenSigFirstTimeoutTime" BU_SG_REL_ VCM SG_ 275 RoadWheelAngleResp_Status 3000;
BA_REL_ "GenSigTimeoutTime" BU_SG_REL_ VCM SG_ 275 RoadWheelAngleResp_Status 100;
BA_REL_ "GenSigFirstTimeoutTime" BU_SG_REL_ VCM SG_ 275 SteeringWheelTorque_Estimate 3000;
BA_REL_ "GenSigTimeoutTime" BU_SG_REL_ VCM SG_ 275 SteeringWheelTorque_Estimate 100;
BA_REL_ "GenSigFirstTimeoutTime" BU_SG_REL_ VCM SG_ 275 SteeringCtrlModeRsp_Cap 3000;
BA_REL_ "GenSigTimeoutTime" BU_SG_REL_ VCM SG_ 275 SteeringCtrlModeRsp_Cap 100;
BA_REL_ "GenSigFirstTimeoutTime" BU_SG_REL_ VCM SG_ 275 RoadWheelAngleResp_MaxCap 3000;
BA_REL_ "GenSigTimeoutTime" BU_SG_REL_ VCM SG_ 275 RoadWheelAngleResp_MaxCap 100;
BA_REL_ "GenSigFirstTimeoutTime" BU_SG_REL_ VCM SG_ 275 SteeringCtrlModeRsp_Active 3000;
BA_REL_ "GenSigTimeoutTime" BU_SG_REL_ VCM SG_ 275 SteeringCtrlModeRsp_Active 100;
BA_REL_ "GenSigFirstTimeoutTime" BU_SG_REL_ VCM SG_ 275 RoadWheelAngleResp_MinCap 3000;
BA_REL_ "GenSigTimeoutTime" BU_SG_REL_ VCM SG_ 275 RoadWheelAngleResp_MinCap 100;
BA_REL_ "GenSigFirstTimeoutTime" BU_SG_REL_ VCM SG_ 275 RoadWheelAngleResp_SqC 3000;
BA_REL_ "GenSigTimeoutTime" BU_SG_REL_ VCM SG_ 275 RoadWheelAngleResp_SqC 100;
BA_REL_ "GenSigFirstTimeoutTime" BU_SG_REL_ VCM SG_ 271 ZxbrStsVeh_RetTar 3000;
BA_REL_ "GenSigTimeoutTime" BU_SG_REL_ VCM SG_ 271 ZxbrStsVeh_RetTar 100;
BA_REL_ "GenSigFirstTimeoutTime" BU_SG_REL_ VCM SG_ 271 ZxbrStsVeh_RetEbiModSts 3000;
BA_REL_ "GenSigTimeoutTime" BU_SG_REL_ VCM SG_ 271 ZxbrStsVeh_RetEbiModSts 100;
BA_REL_ "GenSigFirstTimeoutTime" BU_SG_REL_ VCM SG_ 271 ZxbrStsVeh_EbsCtrlModSts 3000;
BA_REL_ "GenSigTimeoutTime" BU_SG_REL_ VCM SG_ 271 ZxbrStsVeh_EbsCtrlModSts 100;
BA_REL_ "GenSigFirstTimeoutTime" BU_SG_REL_ VCM SG_ 271 ZxbrStsVeh_RetSts 3000;
BA_REL_ "GenSigTimeoutTime" BU_SG_REL_ VCM SG_ 271 ZxbrStsVeh_RetSts 100;
BA_REL_ "GenSigFirstTimeoutTime" BU_SG_REL_ VCM SG_ 271 ZxbrStsVeh_EbsHealthSts 3000;
BA_REL_ "GenSigTimeoutTime" BU_SG_REL_ VCM SG_ 271 ZxbrStsVeh_EbsHealthSts 100;
BA_REL_ "GenSigFirstTimeoutTime" BU_SG_REL_ VCM SG_ 271 ZxbrStsVeh_SqC 3000;
BA_REL_ "GenSigTimeoutTime" BU_SG_REL_ VCM SG_ 271 ZxbrStsVeh_SqC 100;
BA_REL_ "GenSigFirstTimeoutTime" BU_SG_REL_ VCM SG_ 271 ZxbrStsVeh_RetModSts 3000;
BA_REL_ "GenSigTimeoutTime" BU_SG_REL_ VCM SG_ 271 ZxbrStsVeh_RetModSts 100;
BA_REL_ "GenSigFirstTimeoutTime" BU_SG_REL_ VCM SG_ 271 ZxbrStsVeh_DrvrModSts 3000;
BA_REL_ "GenSigTimeoutTime" BU_SG_REL_ VCM SG_ 271 ZxbrStsVeh_DrvrModSts 100;
BA_REL_ "GenSigFirstTimeoutTime" BU_SG_REL_ VCM SG_ 271 ZxbrStsVeh_RetCpbty 3000;
BA_REL_ "GenSigTimeoutTime" BU_SG_REL_ VCM SG_ 271 ZxbrStsVeh_RetCpbty 100;
BA_REL_ "GenSigFirstTimeoutTime" BU_SG_REL_ VCM SG_ 271 ZxbrStsVeh_CRC 3000;
BA_REL_ "GenSigTimeoutTime" BU_SG_REL_ VCM SG_ 271 ZxbrStsVeh_CRC 100;
BA_REL_ "GenSigFirstTimeoutTime" BU_SG_REL_ VCM SG_ 304 Sts2Axle2_WhlTqRi 3000;
BA_REL_ "GenSigTimeoutTime" BU_SG_REL_ VCM SG_ 304 Sts2Axle2_WhlTqRi 100;
BA_REL_ "GenSigFirstTimeoutTime" BU_SG_REL_ VCM SG_ 304 Sts2Axle4_WhlTqQltyLe 3000;
BA_REL_ "GenSigTimeoutTime" BU_SG_REL_ VCM SG_ 304 Sts2Axle4_WhlTqQltyLe 100;
BA_REL_ "GenSigFirstTimeoutTime" BU_SG_REL_ VCM SG_ 304 Sts2Axle3_SqC 3000;
BA_REL_ "GenSigTimeoutTime" BU_SG_REL_ VCM SG_ 304 Sts2Axle3_SqC 100;
BA_REL_ "GenSigFirstTimeoutTime" BU_SG_REL_ VCM SG_ 304 Sts2Axle6_WhlTqRi 3000;
BA_REL_ "GenSigTimeoutTime" BU_SG_REL_ VCM SG_ 304 Sts2Axle6_WhlTqRi 100;
BA_REL_ "GenSigFirstTimeoutTime" BU_SG_REL_ VCM SG_ 304 Sts2Axle3_BrkTqReqRefLe 3000;
BA_REL_ "GenSigTimeoutTime" BU_SG_REL_ VCM SG_ 304 Sts2Axle3_BrkTqReqRefLe 100;
BA_REL_ "GenSigFirstTimeoutTime" BU_SG_REL_ VCM SG_ 304 Sts2Axle2_WhlTqQltyRi 3000;
BA_REL_ "GenSigTimeoutTime" BU_SG_REL_ VCM SG_ 304 Sts2Axle2_WhlTqQltyRi 100;
BA_REL_ "GenSigFirstTimeoutTime" BU_SG_REL_ VCM SG_ 304 Sts2Axle1_SqC 3000;
BA_REL_ "GenSigTimeoutTime" BU_SG_REL_ VCM SG_ 304 Sts2Axle1_SqC 100;
BA_REL_ "GenSigFirstTimeoutTime" BU_SG_REL_ VCM SG_ 304 Sts2Axle1_BrkTqReqRefLe 3000;
BA_REL_ "GenSigTimeoutTime" BU_SG_REL_ VCM SG_ 304 Sts2Axle1_BrkTqReqRefLe 100;
BA_REL_ "GenSigFirstTimeoutTime" BU_SG_REL_ VCM SG_ 304 Sts2Axle2_WhlTqQltyLe 3000;
BA_REL_ "GenSigTimeoutTime" BU_SG_REL_ VCM SG_ 304 Sts2Axle2_WhlTqQltyLe 100;
BA_REL_ "GenSigFirstTimeoutTime" BU_SG_REL_ VCM SG_ 304 Sts2Axle4_BrkTqReqRefLe 3000;
BA_REL_ "GenSigTimeoutTime" BU_SG_REL_ VCM SG_ 304 Sts2Axle4_BrkTqReqRefLe 100;
BA_REL_ "GenSigFirstTimeoutTime" BU_SG_REL_ VCM SG_ 304 Sts2Axle2_SqC 3000;
BA_REL_ "GenSigTimeoutTime" BU_SG_REL_ VCM SG_ 304 Sts2Axle2_SqC 100;
BA_REL_ "GenSigFirstTimeoutTime" BU_SG_REL_ VCM SG_ 304 Sts2Axle4_CRC 3000;
BA_REL_ "GenSigTimeoutTime" BU_SG_REL_ VCM SG_ 304 Sts2Axle4_CRC 100;
BA_REL_ "GenSigFirstTimeoutTime" BU_SG_REL_ VCM SG_ 304 Sts2Axle3_WhlTqQltyLe 3000;
BA_REL_ "GenSigTimeoutTime" BU_SG_REL_ VCM SG_ 304 Sts2Axle3_WhlTqQltyLe 100;
BA_REL_ "GenSigFirstTimeoutTime" BU_SG_REL_ VCM SG_ 304 Sts2Axle1_WhlTqQltyRi 3000;
BA_REL_ "GenSigTimeoutTime" BU_SG_REL_ VCM SG_ 304 Sts2Axle1_WhlTqQltyRi 100;
BA_REL_ "GenSigFirstTimeoutTime" BU_SG_REL_ VCM SG_ 304 Sts2Axle1_WhlTqLe 3000;
BA_REL_ "GenSigTimeoutTime" BU_SG_REL_ VCM SG_ 304 Sts2Axle1_WhlTqLe 100;
BA_REL_ "GenSigFirstTimeoutTime" BU_SG_REL_ VCM SG_ 304 Sts2Axle4_SqC 3000;
BA_REL_ "GenSigTimeoutTime" BU_SG_REL_ VCM SG_ 304 Sts2Axle4_SqC 100;
BA_REL_ "GenSigFirstTimeoutTime" BU_SG_REL_ VCM SG_ 304 Sts2Axle4_WhlTqQltyRi 3000;
BA_REL_ "GenSigTimeoutTime" BU_SG_REL_ VCM SG_ 304 Sts2Axle4_WhlTqQltyRi 100;
BA_REL_ "GenSigFirstTimeoutTime" BU_SG_REL_ VCM SG_ 304 Sts2Axle3_BrkTqReqRefRi 3000;
BA_REL_ "GenSigTimeoutTime" BU_SG_REL_ VCM SG_ 304 Sts2Axle3_BrkTqReqRefRi 100;
BA_REL_ "GenSigFirstTimeoutTime" BU_SG_REL_ VCM SG_ 304 Sts2Axle6_SqC 3000;
BA_REL_ "GenSigTimeoutTime" BU_SG_REL_ VCM SG_ 304 Sts2Axle6_SqC 100;
BA_REL_ "GenSigFirstTimeoutTime" BU_SG_REL_ VCM SG_ 304 Sts2Axle6_CRC 3000;
BA_REL_ "GenSigTimeoutTime" BU_SG_REL_ VCM SG_ 304 Sts2Axle6_CRC 100;
BA_REL_ "GenSigFirstTimeoutTime" BU_SG_REL_ VCM SG_ 304 Sts2Axle5_BrkTqReqRefLe 3000;
BA_REL_ "GenSigTimeoutTime" BU_SG_REL_ VCM SG_ 304 Sts2Axle5_BrkTqReqRefLe 100;
BA_REL_ "GenSigFirstTimeoutTime" BU_SG_REL_ VCM SG_ 304 Sts2Axle6_WhlTqQltyLe 3000;
BA_REL_ "GenSigTimeoutTime" BU_SG_REL_ VCM SG_ 304 Sts2Axle6_WhlTqQltyLe 100;
BA_REL_ "GenSigFirstTimeoutTime" BU_SG_REL_ VCM SG_ 304 Sts2Axle2_WhlTqLe 3000;
BA_REL_ "GenSigTimeoutTime" BU_SG_REL_ VCM SG_ 304 Sts2Axle2_WhlTqLe 100;
BA_REL_ "GenSigFirstTimeoutTime" BU_SG_REL_ VCM SG_ 304 Sts2Axle5_WhlTqQltyRi 3000;
BA_REL_ "GenSigTimeoutTime" BU_SG_REL_ VCM SG_ 304 Sts2Axle5_WhlTqQltyRi 100;
BA_REL_ "GenSigFirstTimeoutTime" BU_SG_REL_ VCM SG_ 304 Sts2Axle3_CRC 3000;
BA_REL_ "GenSigTimeoutTime" BU_SG_REL_ VCM SG_ 304 Sts2Axle3_CRC 100;
BA_REL_ "GenSigFirstTimeoutTime" BU_SG_REL_ VCM SG_ 304 Sts2Axle6_BrkTqReqRefRi 3000;
BA_REL_ "GenSigTimeoutTime" BU_SG_REL_ VCM SG_ 304 Sts2Axle6_BrkTqReqRefRi 100;
BA_REL_ "GenSigFirstTimeoutTime" BU_SG_REL_ VCM SG_ 304 Sts2Axle1_WhlTqRi 3000;
BA_REL_ "GenSigTimeoutTime" BU_SG_REL_ VCM SG_ 304 Sts2Axle1_WhlTqRi 100;
BA_REL_ "GenSigFirstTimeoutTime" BU_SG_REL_ VCM SG_ 304 Sts2Axle4_BrkTqReqRefRi 3000;
BA_REL_ "GenSigTimeoutTime" BU_SG_REL_ VCM SG_ 304 Sts2Axle4_BrkTqReqRefRi 100;
BA_REL_ "GenSigFirstTimeoutTime" BU_SG_REL_ VCM SG_ 304 Sts2Axle1_BrkTqReqRefRi 3000;
BA_REL_ "GenSigTimeoutTime" BU_SG_REL_ VCM SG_ 304 Sts2Axle1_BrkTqReqRefRi 100;
BA_REL_ "GenSigFirstTimeoutTime" BU_SG_REL_ VCM SG_ 304 Sts2Axle2_BrkTqReqRefLe 3000;
BA_REL_ "GenSigTimeoutTime" BU_SG_REL_ VCM SG_ 304 Sts2Axle2_BrkTqReqRefLe 100;
BA_REL_ "GenSigFirstTimeoutTime" BU_SG_REL_ VCM SG_ 304 Sts2Axle5_SqC 3000;
BA_REL_ "GenSigTimeoutTime" BU_SG_REL_ VCM SG_ 304 Sts2Axle5_SqC 100;
BA_REL_ "GenSigFirstTimeoutTime" BU_SG_REL_ VCM SG_ 304 Sts2Axle3_WhlTqLe 3000;
BA_REL_ "GenSigTimeoutTime" BU_SG_REL_ VCM SG_ 304 Sts2Axle3_WhlTqLe 100;
BA_REL_ "GenSigFirstTimeoutTime" BU_SG_REL_ VCM SG_ 304 Sts2Axle6_WhlTqQltyRi 3000;
BA_REL_ "GenSigTimeoutTime" BU_SG_REL_ VCM SG_ 304 Sts2Axle6_WhlTqQltyRi 100;
BA_REL_ "GenSigFirstTimeoutTime" BU_SG_REL_ VCM SG_ 304 Sts2Axle5_WhlTqRi 3000;
BA_REL_ "GenSigTimeoutTime" BU_SG_REL_ VCM SG_ 304 Sts2Axle5_WhlTqRi 100;
BA_REL_ "GenSigFirstTimeoutTime" BU_SG_REL_ VCM SG_ 304 Sts2Axle5_WhlTqLe 3000;
BA_REL_ "GenSigTimeoutTime" BU_SG_REL_ VCM SG_ 304 Sts2Axle5_WhlTqLe 100;
BA_REL_ "GenSigFirstTimeoutTime" BU_SG_REL_ VCM SG_ 304 Sts2Axle5_WhlTqQltyLe 3000;
BA_REL_ "GenSigTimeoutTime" BU_SG_REL_ VCM SG_ 304 Sts2Axle5_WhlTqQltyLe 100;
BA_REL_ "GenSigFirstTimeoutTime" BU_SG_REL_ VCM SG_ 304 Sts2Axle1_WhlTqQltyLe 3000;
BA_REL_ "GenSigTimeoutTime" BU_SG_REL_ VCM SG_ 304 Sts2Axle1_WhlTqQltyLe 100;
BA_REL_ "GenSigFirstTimeoutTime" BU_SG_REL_ VCM SG_ 304 Sts2Axle6_WhlTqLe 3000;
BA_REL_ "GenSigTimeoutTime" BU_SG_REL_ VCM SG_ 304 Sts2Axle6_WhlTqLe 100;
BA_REL_ "GenSigFirstTimeoutTime" BU_SG_REL_ VCM SG_ 304 Sts2Axle4_WhlTqRi 3000;
BA_REL_ "GenSigTimeoutTime" BU_SG_REL_ VCM SG_ 304 Sts2Axle4_WhlTqRi 100;
BA_REL_ "GenSigFirstTimeoutTime" BU_SG_REL_ VCM SG_ 304 Sts2Axle1_CRC 3000;
BA_REL_ "GenSigTimeoutTime" BU_SG_REL_ VCM SG_ 304 Sts2Axle1_CRC 100;
BA_REL_ "GenSigFirstTimeoutTime" BU_SG_REL_ VCM SG_ 304 Sts2Axle5_CRC 3000;
BA_REL_ "GenSigTimeoutTime" BU_SG_REL_ VCM SG_ 304 Sts2Axle5_CRC 100;
BA_REL_ "GenSigFirstTimeoutTime" BU_SG_REL_ VCM SG_ 304 Sts2Axle3_WhlTqRi 3000;
BA_REL_ "GenSigTimeoutTime" BU_SG_REL_ VCM SG_ 304 Sts2Axle3_WhlTqRi 100;
BA_REL_ "GenSigFirstTimeoutTime" BU_SG_REL_ VCM SG_ 304 Sts2Axle6_BrkTqReqRefLe 3000;
BA_REL_ "GenSigTimeoutTime" BU_SG_REL_ VCM SG_ 304 Sts2Axle6_BrkTqReqRefLe 100;
BA_REL_ "GenSigFirstTimeoutTime" BU_SG_REL_ VCM SG_ 304 Sts2Axle2_BrkTqReqRefRi 3000;
BA_REL_ "GenSigTimeoutTime" BU_SG_REL_ VCM SG_ 304 Sts2Axle2_BrkTqReqRefRi 100;
BA_REL_ "GenSigFirstTimeoutTime" BU_SG_REL_ VCM SG_ 304 Sts2Axle2_CRC 3000;
BA_REL_ "GenSigTimeoutTime" BU_SG_REL_ VCM SG_ 304 Sts2Axle2_CRC 100;
BA_REL_ "GenSigFirstTimeoutTime" BU_SG_REL_ VCM SG_ 304 Sts2Axle3_WhlTqQltyRi 3000;
BA_REL_ "GenSigTimeoutTime" BU_SG_REL_ VCM SG_ 304 Sts2Axle3_WhlTqQltyRi 100;
BA_REL_ "GenSigFirstTimeoutTime" BU_SG_REL_ VCM SG_ 304 Sts2Axle4_WhlTqLe 3000;
BA_REL_ "GenSigTimeoutTime" BU_SG_REL_ VCM SG_ 304 Sts2Axle4_WhlTqLe 100;
BA_REL_ "GenSigFirstTimeoutTime" BU_SG_REL_ VCM SG_ 304 Sts2Axle5_BrkTqReqRefRi 3000;
BA_REL_ "GenSigTimeoutTime" BU_SG_REL_ VCM SG_ 304 Sts2Axle5_BrkTqReqRefRi 100;
BA_REL_ "GenSigFirstTimeoutTime" BU_SG_REL_ VCM SG_ 288 Sts1Axle6_WhlRotQltyLe 3000;
BA_REL_ "GenSigTimeoutTime" BU_SG_REL_ VCM SG_ 288 Sts1Axle6_WhlRotQltyLe 100;
BA_REL_ "GenSigFirstTimeoutTime" BU_SG_REL_ VCM SG_ 288 Sts1Axle5_CRC 3000;
BA_REL_ "GenSigTimeoutTime" BU_SG_REL_ VCM SG_ 288 Sts1Axle5_CRC 100;
BA_REL_ "GenSigFirstTimeoutTime" BU_SG_REL_ VCM SG_ 288 Sts1Axle2_WhlRotQltyRi 3000;
BA_REL_ "GenSigTimeoutTime" BU_SG_REL_ VCM SG_ 288 Sts1Axle2_WhlRotQltyRi 100;
BA_REL_ "GenSigFirstTimeoutTime" BU_SG_REL_ VCM SG_ 288 Sts1Axle2_WhlRotSpdRi 3000;
BA_REL_ "GenSigTimeoutTime" BU_SG_REL_ VCM SG_ 288 Sts1Axle2_WhlRotSpdRi 100;
BA_REL_ "GenSigFirstTimeoutTime" BU_SG_REL_ VCM SG_ 288 Sts1Axle6_CRC 3000;
BA_REL_ "GenSigTimeoutTime" BU_SG_REL_ VCM SG_ 288 Sts1Axle6_CRC 100;
BA_REL_ "GenSigFirstTimeoutTime" BU_SG_REL_ VCM SG_ 288 Sts1Axle5_WhlRotAgCntrRi 3000;
BA_REL_ "GenSigTimeoutTime" BU_SG_REL_ VCM SG_ 288 Sts1Axle5_WhlRotAgCntrRi 100;
BA_REL_ "GenSigFirstTimeoutTime" BU_SG_REL_ VCM SG_ 288 Sts1Axle3_CRC 3000;
BA_REL_ "GenSigTimeoutTime" BU_SG_REL_ VCM SG_ 288 Sts1Axle3_CRC 100;
BA_REL_ "GenSigFirstTimeoutTime" BU_SG_REL_ VCM SG_ 288 Sts1Axle4_WhlRotSpdLe 3000;
BA_REL_ "GenSigTimeoutTime" BU_SG_REL_ VCM SG_ 288 Sts1Axle4_WhlRotSpdLe 100;
BA_REL_ "GenSigFirstTimeoutTime" BU_SG_REL_ VCM SG_ 288 Sts1Axle4_WhlRotAgCntrLe 3000;
BA_REL_ "GenSigTimeoutTime" BU_SG_REL_ VCM SG_ 288 Sts1Axle4_WhlRotAgCntrLe 100;
BA_REL_ "GenSigFirstTimeoutTime" BU_SG_REL_ VCM SG_ 288 Sts1Axle6_WhlRotSpdRi 3000;
BA_REL_ "GenSigTimeoutTime" BU_SG_REL_ VCM SG_ 288 Sts1Axle6_WhlRotSpdRi 100;
BA_REL_ "GenSigFirstTimeoutTime" BU_SG_REL_ VCM SG_ 288 Sts1Axle3_WhlRotAgCntrLe 3000;
BA_REL_ "GenSigTimeoutTime" BU_SG_REL_ VCM SG_ 288 Sts1Axle3_WhlRotAgCntrLe 100;
BA_REL_ "GenSigFirstTimeoutTime" BU_SG_REL_ VCM SG_ 288 Sts1Axle2_CRC 3000;
BA_REL_ "GenSigTimeoutTime" BU_SG_REL_ VCM SG_ 288 Sts1Axle2_CRC 100;
BA_REL_ "GenSigFirstTimeoutTime" BU_SG_REL_ VCM SG_ 288 Sts1Axle1_WhlRotSpdRi 3000;
BA_REL_ "GenSigTimeoutTime" BU_SG_REL_ VCM SG_ 288 Sts1Axle1_WhlRotSpdRi 100;
BA_REL_ "GenSigFirstTimeoutTime" BU_SG_REL_ VCM SG_ 288 Sts1Axle1_WhlRotQltyRi 3000;
BA_REL_ "GenSigTimeoutTime" BU_SG_REL_ VCM SG_ 288 Sts1Axle1_WhlRotQltyRi 100;
BA_REL_ "GenSigFirstTimeoutTime" BU_SG_REL_ VCM SG_ 288 Sts1Axle3_WhlRotQltyLe 3000;
BA_REL_ "GenSigTimeoutTime" BU_SG_REL_ VCM SG_ 288 Sts1Axle3_WhlRotQltyLe 100;
BA_REL_ "GenSigFirstTimeoutTime" BU_SG_REL_ VCM SG_ 288 Sts1Axle5_WhlRotAgCntrLe 3000;
BA_REL_ "GenSigTimeoutTime" BU_SG_REL_ VCM SG_ 288 Sts1Axle5_WhlRotAgCntrLe 100;
BA_REL_ "GenSigFirstTimeoutTime" BU_SG_REL_ VCM SG_ 288 Sts1Axle3_SqC 3000;
BA_REL_ "GenSigTimeoutTime" BU_SG_REL_ VCM SG_ 288 Sts1Axle3_SqC 100;
BA_REL_ "GenSigFirstTimeoutTime" BU_SG_REL_ VCM SG_ 288 Sts1Axle4_SqC 3000;
BA_REL_ "GenSigTimeoutTime" BU_SG_REL_ VCM SG_ 288 Sts1Axle4_SqC 100;
BA_REL_ "GenSigFirstTimeoutTime" BU_SG_REL_ VCM SG_ 288 Sts1Axle1_SqC 3000;
BA_REL_ "GenSigTimeoutTime" BU_SG_REL_ VCM SG_ 288 Sts1Axle1_SqC 100;
BA_REL_ "GenSigFirstTimeoutTime" BU_SG_REL_ VCM SG_ 288 Sts1Axle5_SqC 3000;
BA_REL_ "GenSigTimeoutTime" BU_SG_REL_ VCM SG_ 288 Sts1Axle5_SqC 100;
BA_REL_ "GenSigFirstTimeoutTime" BU_SG_REL_ VCM SG_ 288 Sts1Axle2_WhlRotSpdLe 3000;
BA_REL_ "GenSigTimeoutTime" BU_SG_REL_ VCM SG_ 288 Sts1Axle2_WhlRotSpdLe 100;
BA_REL_ "GenSigFirstTimeoutTime" BU_SG_REL_ VCM SG_ 288 Sts1Axle1_WhlRotQltyLe 3000;
BA_REL_ "GenSigTimeoutTime" BU_SG_REL_ VCM SG_ 288 Sts1Axle1_WhlRotQltyLe 100;
BA_REL_ "GenSigFirstTimeoutTime" BU_SG_REL_ VCM SG_ 288 Sts1Axle3_WhlRotAgCntrRi 3000;
BA_REL_ "GenSigTimeoutTime" BU_SG_REL_ VCM SG_ 288 Sts1Axle3_WhlRotAgCntrRi 100;
BA_REL_ "GenSigFirstTimeoutTime" BU_SG_REL_ VCM SG_ 288 Sts1Axle1_WhlRotAgCntrLe 3000;
BA_REL_ "GenSigTimeoutTime" BU_SG_REL_ VCM SG_ 288 Sts1Axle1_WhlRotAgCntrLe 100;
BA_REL_ "GenSigFirstTimeoutTime" BU_SG_REL_ VCM SG_ 288 Sts1Axle1_CRC 3000;
BA_REL_ "GenSigTimeoutTime" BU_SG_REL_ VCM SG_ 288 Sts1Axle1_CRC 100;
BA_REL_ "GenSigFirstTimeoutTime" BU_SG_REL_ VCM SG_ 288 Sts1Axle6_WhlRotAgCntrLe 3000;
BA_REL_ "GenSigTimeoutTime" BU_SG_REL_ VCM SG_ 288 Sts1Axle6_WhlRotAgCntrLe 100;
BA_REL_ "GenSigFirstTimeoutTime" BU_SG_REL_ VCM SG_ 288 Sts1Axle5_WhlRotQltyLe 3000;
BA_REL_ "GenSigTimeoutTime" BU_SG_REL_ VCM SG_ 288 Sts1Axle5_WhlRotQltyLe 100;
BA_REL_ "GenSigFirstTimeoutTime" BU_SG_REL_ VCM SG_ 288 Sts1Axle5_WhlRotQltyRi 3000;
BA_REL_ "GenSigTimeoutTime" BU_SG_REL_ VCM SG_ 288 Sts1Axle5_WhlRotQltyRi 100;
BA_REL_ "GenSigFirstTimeoutTime" BU_SG_REL_ VCM SG_ 288 Sts1Axle1_WhlRotSpdLe 3000;
BA_REL_ "GenSigTimeoutTime" BU_SG_REL_ VCM SG_ 288 Sts1Axle1_WhlRotSpdLe 100;
BA_REL_ "GenSigFirstTimeoutTime" BU_SG_REL_ VCM SG_ 288 Sts1Axle2_WhlRotAgCntrRi 3000;
BA_REL_ "GenSigTimeoutTime" BU_SG_REL_ VCM SG_ 288 Sts1Axle2_WhlRotAgCntrRi 100;
BA_REL_ "GenSigFirstTimeoutTime" BU_SG_REL_ VCM SG_ 288 Sts1Axle4_WhlRotQltyRi 3000;
BA_REL_ "GenSigTimeoutTime" BU_SG_REL_ VCM SG_ 288 Sts1Axle4_WhlRotQltyRi 100;
BA_REL_ "GenSigFirstTimeoutTime" BU_SG_REL_ VCM SG_ 288 Sts1Axle2_WhlRotAgCntrLe 3000;
BA_REL_ "GenSigTimeoutTime" BU_SG_REL_ VCM SG_ 288 Sts1Axle2_WhlRotAgCntrLe 100;
BA_REL_ "GenSigFirstTimeoutTime" BU_SG_REL_ VCM SG_ 288 Sts1Axle3_WhlRotQltyRi 3000;
BA_REL_ "GenSigTimeoutTime" BU_SG_REL_ VCM SG_ 288 Sts1Axle3_WhlRotQltyRi 100;
BA_REL_ "GenSigFirstTimeoutTime" BU_SG_REL_ VCM SG_ 288 Sts1Axle6_WhlRotAgCntrRi 3000;
BA_REL_ "GenSigTimeoutTime" BU_SG_REL_ VCM SG_ 288 Sts1Axle6_WhlRotAgCntrRi 100;
BA_REL_ "GenSigFirstTimeoutTime" BU_SG_REL_ VCM SG_ 288 Sts1Axle5_WhlRotSpdRi 3000;
BA_REL_ "GenSigTimeoutTime" BU_SG_REL_ VCM SG_ 288 Sts1Axle5_WhlRotSpdRi 100;
BA_REL_ "GenSigFirstTimeoutTime" BU_SG_REL_ VCM SG_ 288 Sts1Axle4_CRC 3000;
BA_REL_ "GenSigTimeoutTime" BU_SG_REL_ VCM SG_ 288 Sts1Axle4_CRC 100;
BA_REL_ "GenSigFirstTimeoutTime" BU_SG_REL_ VCM SG_ 288 Sts1Axle1_WhlRotAgCntrRi 3000;
BA_REL_ "GenSigTimeoutTime" BU_SG_REL_ VCM SG_ 288 Sts1Axle1_WhlRotAgCntrRi 100;
BA_REL_ "GenSigFirstTimeoutTime" BU_SG_REL_ VCM SG_ 288 Sts1Axle5_WhlRotSpdLe 3000;
BA_REL_ "GenSigTimeoutTime" BU_SG_REL_ VCM SG_ 288 Sts1Axle5_WhlRotSpdLe 100;
BA_REL_ "GenSigFirstTimeoutTime" BU_SG_REL_ VCM SG_ 288 Sts1Axle3_WhlRotSpdLe 3000;
BA_REL_ "GenSigTimeoutTime" BU_SG_REL_ VCM SG_ 288 Sts1Axle3_WhlRotSpdLe 100;
BA_REL_ "GenSigFirstTimeoutTime" BU_SG_REL_ VCM SG_ 288 Sts1Axle4_WhlRotSpdRi 3000;
BA_REL_ "GenSigTimeoutTime" BU_SG_REL_ VCM SG_ 288 Sts1Axle4_WhlRotSpdRi 100;
BA_REL_ "GenSigFirstTimeoutTime" BU_SG_REL_ VCM SG_ 288 Sts1Axle4_WhlRotQltyLe 3000;
BA_REL_ "GenSigTimeoutTime" BU_SG_REL_ VCM SG_ 288 Sts1Axle4_WhlRotQltyLe 100;
BA_REL_ "GenSigFirstTimeoutTime" BU_SG_REL_ VCM SG_ 288 Sts1Axle2_WhlRotQltyLe 3000;
BA_REL_ "GenSigTimeoutTime" BU_SG_REL_ VCM SG_ 288 Sts1Axle2_WhlRotQltyLe 100;
BA_REL_ "GenSigFirstTimeoutTime" BU_SG_REL_ VCM SG_ 288 Sts1Axle6_WhlRotSpdLe 3000;
BA_REL_ "GenSigTimeoutTime" BU_SG_REL_ VCM SG_ 288 Sts1Axle6_WhlRotSpdLe 100;
BA_REL_ "GenSigFirstTimeoutTime" BU_SG_REL_ VCM SG_ 288 Sts1Axle4_WhlRotAgCntrRi 3000;
BA_REL_ "GenSigTimeoutTime" BU_SG_REL_ VCM SG_ 288 Sts1Axle4_WhlRotAgCntrRi 100;
BA_REL_ "GenSigFirstTimeoutTime" BU_SG_REL_ VCM SG_ 288 Sts1Axle6_WhlRotQltyRi 3000;
BA_REL_ "GenSigTimeoutTime" BU_SG_REL_ VCM SG_ 288 Sts1Axle6_WhlRotQltyRi 100;
BA_REL_ "GenSigFirstTimeoutTime" BU_SG_REL_ VCM SG_ 288 Sts1Axle2_SqC 3000;
BA_REL_ "GenSigTimeoutTime" BU_SG_REL_ VCM SG_ 288 Sts1Axle2_SqC 100;
BA_REL_ "GenSigFirstTimeoutTime" BU_SG_REL_ VCM SG_ 288 Sts1Axle3_WhlRotSpdRi 3000;
BA_REL_ "GenSigTimeoutTime" BU_SG_REL_ VCM SG_ 288 Sts1Axle3_WhlRotSpdRi 100;
BA_REL_ "GenSigFirstTimeoutTime" BU_SG_REL_ VCM SG_ 288 Sts1Axle6_SqC 3000;
BA_REL_ "GenSigTimeoutTime" BU_SG_REL_ VCM SG_ 288 Sts1Axle6_SqC 100;
BA_REL_ "GenSigFirstTimeoutTime" BU_SG_REL_ VCM SG_ 602 IxbrSts2Veh_CRC 3000;
BA_REL_ "GenSigTimeoutTime" BU_SG_REL_ VCM SG_ 602 IxbrSts2Veh_CRC 300;
BA_REL_ "GenSigFirstTimeoutTime" BU_SG_REL_ VCM SG_ 602 IxbrSts1Veh_AbsSts 3000;
BA_REL_ "GenSigTimeoutTime" BU_SG_REL_ VCM SG_ 602 IxbrSts1Veh_AbsSts 300;
BA_REL_ "GenSigFirstTimeoutTime" BU_SG_REL_ VCM SG_ 602 IxbrSts1Veh_IxbrModSts 3000;
BA_REL_ "GenSigTimeoutTime" BU_SG_REL_ VCM SG_ 602 IxbrSts1Veh_IxbrModSts 300;
BA_REL_ "GenSigFirstTimeoutTime" BU_SG_REL_ VCM SG_ 602 IxbrSts2Veh_SqC 3000;
BA_REL_ "GenSigTimeoutTime" BU_SG_REL_ VCM SG_ 602 IxbrSts2Veh_SqC 300;
BA_REL_ "GenSigFirstTimeoutTime" BU_SG_REL_ VCM SG_ 602 IxbrSts1Veh_VehSpdLimRsc 3000;
BA_REL_ "GenSigTimeoutTime" BU_SG_REL_ VCM SG_ 602 IxbrSts1Veh_VehSpdLimRsc 300;
BA_REL_ "GenSigFirstTimeoutTime" BU_SG_REL_ VCM SG_ 602 IxbrSts2Veh_YawRateRefEsc 3000;
BA_REL_ "GenSigTimeoutTime" BU_SG_REL_ VCM SG_ 602 IxbrSts2Veh_YawRateRefEsc 300;
BA_REL_ "GenSigFirstTimeoutTime" BU_SG_REL_ VCM SG_ 602 IxbrSts2Veh_VehAccnLatLimNeg 3000;
BA_REL_ "GenSigTimeoutTime" BU_SG_REL_ VCM SG_ 602 IxbrSts2Veh_VehAccnLatLimNeg 300;
BA_REL_ "GenSigFirstTimeoutTime" BU_SG_REL_ VCM SG_ 602 IxbrSts1Veh_VehSpdLgt 3000;
BA_REL_ "GenSigTimeoutTime" BU_SG_REL_ VCM SG_ 602 IxbrSts1Veh_VehSpdLgt 300;
BA_REL_ "GenSigFirstTimeoutTime" BU_SG_REL_ VCM SG_ 602 IxbrSts1Veh_EscSts 3000;
BA_REL_ "GenSigTimeoutTime" BU_SG_REL_ VCM SG_ 602 IxbrSts1Veh_EscSts 300;
BA_REL_ "GenSigFirstTimeoutTime" BU_SG_REL_ VCM SG_ 602 IxbrSts2Veh_YawRateOffsLim 3000;
BA_REL_ "GenSigTimeoutTime" BU_SG_REL_ VCM SG_ 602 IxbrSts2Veh_YawRateOffsLim 300;
BA_REL_ "GenSigFirstTimeoutTime" BU_SG_REL_ VCM SG_ 602 IxbrSts1Veh_TscSts 3000;
BA_REL_ "GenSigTimeoutTime" BU_SG_REL_ VCM SG_ 602 IxbrSts1Veh_TscSts 300;
BA_REL_ "GenSigFirstTimeoutTime" BU_SG_REL_ VCM SG_ 602 IxbrSts1Veh_CRC 3000;
BA_REL_ "GenSigTimeoutTime" BU_SG_REL_ VCM SG_ 602 IxbrSts1Veh_CRC 300;
BA_REL_ "GenSigFirstTimeoutTime" BU_SG_REL_ VCM SG_ 602 IxbrSts2Veh_VehAccnLatLimPos 3000;
BA_REL_ "GenSigTimeoutTime" BU_SG_REL_ VCM SG_ 602 IxbrSts2Veh_VehAccnLatLimPos 300;
BA_REL_ "GenSigFirstTimeoutTime" BU_SG_REL_ VCM SG_ 602 IxbrSts1Veh_SqC 3000;
BA_REL_ "GenSigTimeoutTime" BU_SG_REL_ VCM SG_ 602 IxbrSts1Veh_SqC 300;
BA_REL_ "GenSigFirstTimeoutTime" BU_SG_REL_ VCM SG_ 602 IxbrSts1Veh_RscSts 3000;
BA_REL_ "GenSigTimeoutTime" BU_SG_REL_ VCM SG_ 602 IxbrSts1Veh_RscSts 300;
BA_REL_ "GenSigFirstTimeoutTime" BU_SG_REL_ VCM SG_ 598 IxbrSts3Ax5_WhlAccnLgtLimMinLe 3000;
BA_REL_ "GenSigTimeoutTime" BU_SG_REL_ VCM SG_ 598 IxbrSts3Ax5_WhlAccnLgtLimMinLe 300;
BA_REL_ "GenSigFirstTimeoutTime" BU_SG_REL_ VCM SG_ 598 IxbrSts3Ax5_CRC 3000;
BA_REL_ "GenSigTimeoutTime" BU_SG_REL_ VCM SG_ 598 IxbrSts3Ax5_CRC 300;
BA_REL_ "GenSigFirstTimeoutTime" BU_SG_REL_ VCM SG_ 598 IxbrSts3Ax5_SqC 3000;
BA_REL_ "GenSigTimeoutTime" BU_SG_REL_ VCM SG_ 598 IxbrSts3Ax5_SqC 300;
BA_REL_ "GenSigFirstTimeoutTime" BU_SG_REL_ VCM SG_ 598 IxbrSts1Ax6_CRC 3000;
BA_REL_ "GenSigTimeoutTime" BU_SG_REL_ VCM SG_ 598 IxbrSts1Ax6_CRC 300;
BA_REL_ "GenSigFirstTimeoutTime" BU_SG_REL_ VCM SG_ 598 IxbrSts2Ax6_WhlSlipLimPrpnRi 3000;
BA_REL_ "GenSigTimeoutTime" BU_SG_REL_ VCM SG_ 598 IxbrSts2Ax6_WhlSlipLimPrpnRi 300;
BA_REL_ "GenSigFirstTimeoutTime" BU_SG_REL_ VCM SG_ 598 IxbrSts2Ax6_WhlSlipLimBrkngLe 3000;
BA_REL_ "GenSigTimeoutTime" BU_SG_REL_ VCM SG_ 598 IxbrSts2Ax6_WhlSlipLimBrkngLe 300;
BA_REL_ "GenSigFirstTimeoutTime" BU_SG_REL_ VCM SG_ 598 IxbrSts3Ax6_WhlAccnLgtLimMaxRi 3000;
BA_REL_ "GenSigTimeoutTime" BU_SG_REL_ VCM SG_ 598 IxbrSts3Ax6_WhlAccnLgtLimMaxRi 300;
BA_REL_ "GenSigFirstTimeoutTime" BU_SG_REL_ VCM SG_ 598 IxbrSts1Ax4_WhlRdEstmdLe 3000;
BA_REL_ "GenSigTimeoutTime" BU_SG_REL_ VCM SG_ 598 IxbrSts1Ax4_WhlRdEstmdLe 300;
BA_REL_ "GenSigFirstTimeoutTime" BU_SG_REL_ VCM SG_ 598 IxbrSts2Ax5_WhlSlipLimBrkngLe 3000;
BA_REL_ "GenSigTimeoutTime" BU_SG_REL_ VCM SG_ 598 IxbrSts2Ax5_WhlSlipLimBrkngLe 300;
BA_REL_ "GenSigFirstTimeoutTime" BU_SG_REL_ VCM SG_ 598 IxbrSts2Ax6_WhlSlipLimBrkngRi 3000;
BA_REL_ "GenSigTimeoutTime" BU_SG_REL_ VCM SG_ 598 IxbrSts2Ax6_WhlSlipLimBrkngRi 300;
BA_REL_ "GenSigFirstTimeoutTime" BU_SG_REL_ VCM SG_ 598 IxbrSts2Ax4_SqC 3000;
BA_REL_ "GenSigTimeoutTime" BU_SG_REL_ VCM SG_ 598 IxbrSts2Ax4_SqC 300;
BA_REL_ "GenSigFirstTimeoutTime" BU_SG_REL_ VCM SG_ 598 IxbrSts3Ax4_CRC 3000;
BA_REL_ "GenSigTimeoutTime" BU_SG_REL_ VCM SG_ 598 IxbrSts3Ax4_CRC 300;
BA_REL_ "GenSigFirstTimeoutTime" BU_SG_REL_ VCM SG_ 598 IxbrSts2Ax4_WhlSlipLimBrkngRi 3000;
BA_REL_ "GenSigTimeoutTime" BU_SG_REL_ VCM SG_ 598 IxbrSts2Ax4_WhlSlipLimBrkngRi 300;
BA_REL_ "GenSigFirstTimeoutTime" BU_SG_REL_ VCM SG_ 598 IxbrSts2Ax4_WhlSlipLimBrkngLe 3000;
BA_REL_ "GenSigTimeoutTime" BU_SG_REL_ VCM SG_ 598 IxbrSts2Ax4_WhlSlipLimBrkngLe 300;
BA_REL_ "GenSigFirstTimeoutTime" BU_SG_REL_ VCM SG_ 598 IxbrSts2Ax6_CRC 3000;
BA_REL_ "GenSigTimeoutTime" BU_SG_REL_ VCM SG_ 598 IxbrSts2Ax6_CRC 300;
BA_REL_ "GenSigFirstTimeoutTime" BU_SG_REL_ VCM SG_ 598 IxbrSts2Ax4_CRC 3000;
BA_REL_ "GenSigTimeoutTime" BU_SG_REL_ VCM SG_ 598 IxbrSts2Ax4_CRC 300;
BA_REL_ "GenSigFirstTimeoutTime" BU_SG_REL_ VCM SG_ 598 IxbrSts3Ax4_WhlAccnLgtLimMinLe 3000;
BA_REL_ "GenSigTimeoutTime" BU_SG_REL_ VCM SG_ 598 IxbrSts3Ax4_WhlAccnLgtLimMinLe 300;
BA_REL_ "GenSigFirstTimeoutTime" BU_SG_REL_ VCM SG_ 598 IxbrSts3Ax6_CRC 3000;
BA_REL_ "GenSigTimeoutTime" BU_SG_REL_ VCM SG_ 598 IxbrSts3Ax6_CRC 300;
BA_REL_ "GenSigFirstTimeoutTime" BU_SG_REL_ VCM SG_ 598 IxbrSts1Ax4_SqC 3000;
BA_REL_ "GenSigTimeoutTime" BU_SG_REL_ VCM SG_ 598 IxbrSts1Ax4_SqC 300;
BA_REL_ "GenSigFirstTimeoutTime" BU_SG_REL_ VCM SG_ 598 IxbrSts1Ax6_SqC 3000;
BA_REL_ "GenSigTimeoutTime" BU_SG_REL_ VCM SG_ 598 IxbrSts1Ax6_SqC 300;
BA_REL_ "GenSigFirstTimeoutTime" BU_SG_REL_ VCM SG_ 598 IxbrSts3Ax5_WhlAccnLgtLimMinRi 3000;
BA_REL_ "GenSigTimeoutTime" BU_SG_REL_ VCM SG_ 598 IxbrSts3Ax5_WhlAccnLgtLimMinRi 300;
BA_REL_ "GenSigFirstTimeoutTime" BU_SG_REL_ VCM SG_ 598 IxbrSts2Ax6_WhlSlipLimPrpnLe 3000;
BA_REL_ "GenSigTimeoutTime" BU_SG_REL_ VCM SG_ 598 IxbrSts2Ax6_WhlSlipLimPrpnLe 300;
BA_REL_ "GenSigFirstTimeoutTime" BU_SG_REL_ VCM SG_ 598 IxbrSts2Ax5_SqC 3000;
BA_REL_ "GenSigTimeoutTime" BU_SG_REL_ VCM SG_ 598 IxbrSts2Ax5_SqC 300;
BA_REL_ "GenSigFirstTimeoutTime" BU_SG_REL_ VCM SG_ 598 IxbrSts3Ax6_SqC 3000;
BA_REL_ "GenSigTimeoutTime" BU_SG_REL_ VCM SG_ 598 IxbrSts3Ax6_SqC 300;
BA_REL_ "GenSigFirstTimeoutTime" BU_SG_REL_ VCM SG_ 598 IxbrSts2Ax5_WhlSlipLimBrkngRi 3000;
BA_REL_ "GenSigTimeoutTime" BU_SG_REL_ VCM SG_ 598 IxbrSts2Ax5_WhlSlipLimBrkngRi 300;
BA_REL_ "GenSigFirstTimeoutTime" BU_SG_REL_ VCM SG_ 598 IxbrSts1Ax5_CRC 3000;
BA_REL_ "GenSigTimeoutTime" BU_SG_REL_ VCM SG_ 598 IxbrSts1Ax5_CRC 300;
BA_REL_ "GenSigFirstTimeoutTime" BU_SG_REL_ VCM SG_ 598 IxbrSts3Ax5_WhlAccnLgtLimMaxRi 3000;
BA_REL_ "GenSigTimeoutTime" BU_SG_REL_ VCM SG_ 598 IxbrSts3Ax5_WhlAccnLgtLimMaxRi 300;
BA_REL_ "GenSigFirstTimeoutTime" BU_SG_REL_ VCM SG_ 598 IxbrSts1Ax6_WhlRdEstmdLe 3000;
BA_REL_ "GenSigTimeoutTime" BU_SG_REL_ VCM SG_ 598 IxbrSts1Ax6_WhlRdEstmdLe 300;
BA_REL_ "GenSigFirstTimeoutTime" BU_SG_REL_ VCM SG_ 598 IxbrSts3Ax6_WhlAccnLgtLimMinLe 3000;
BA_REL_ "GenSigTimeoutTime" BU_SG_REL_ VCM SG_ 598 IxbrSts3Ax6_WhlAccnLgtLimMinLe 300;
BA_REL_ "GenSigFirstTimeoutTime" BU_SG_REL_ VCM SG_ 598 IxbrSts2Ax5_WhlSlipLimPrpnRi 3000;
BA_REL_ "GenSigTimeoutTime" BU_SG_REL_ VCM SG_ 598 IxbrSts2Ax5_WhlSlipLimPrpnRi 300;
BA_REL_ "GenSigFirstTimeoutTime" BU_SG_REL_ VCM SG_ 598 IxbrSts2Ax6_SqC 3000;
BA_REL_ "GenSigTimeoutTime" BU_SG_REL_ VCM SG_ 598 IxbrSts2Ax6_SqC 300;
BA_REL_ "GenSigFirstTimeoutTime" BU_SG_REL_ VCM SG_ 598 IxbrSts3Ax4_WhlAccnLgtLimMinRi 3000;
BA_REL_ "GenSigTimeoutTime" BU_SG_REL_ VCM SG_ 598 IxbrSts3Ax4_WhlAccnLgtLimMinRi 300;
BA_REL_ "GenSigFirstTimeoutTime" BU_SG_REL_ VCM SG_ 598 IxbrSts1Ax5_SqC 3000;
BA_REL_ "GenSigTimeoutTime" BU_SG_REL_ VCM SG_ 598 IxbrSts1Ax5_SqC 300;
BA_REL_ "GenSigFirstTimeoutTime" BU_SG_REL_ VCM SG_ 598 IxbrSts3Ax6_WhlAccnLgtLimMinRi 3000;
BA_REL_ "GenSigTimeoutTime" BU_SG_REL_ VCM SG_ 598 IxbrSts3Ax6_WhlAccnLgtLimMinRi 300;
BA_REL_ "GenSigFirstTimeoutTime" BU_SG_REL_ VCM SG_ 598 IxbrSts2Ax5_CRC 3000;
BA_REL_ "GenSigTimeoutTime" BU_SG_REL_ VCM SG_ 598 IxbrSts2Ax5_CRC 300;
BA_REL_ "GenSigFirstTimeoutTime" BU_SG_REL_ VCM SG_ 598 IxbrSts3Ax4_SqC 3000;
BA_REL_ "GenSigTimeoutTime" BU_SG_REL_ VCM SG_ 598 IxbrSts3Ax4_SqC 300;
BA_REL_ "GenSigFirstTimeoutTime" BU_SG_REL_ VCM SG_ 598 IxbrSts3Ax6_WhlAccnLgtLimMaxLe 3000;
BA_REL_ "GenSigTimeoutTime" BU_SG_REL_ VCM SG_ 598 IxbrSts3Ax6_WhlAccnLgtLimMaxLe 300;
BA_REL_ "GenSigFirstTimeoutTime" BU_SG_REL_ VCM SG_ 598 IxbrSts3Ax4_WhlAccnLgtLimMaxLe 3000;
BA_REL_ "GenSigTimeoutTime" BU_SG_REL_ VCM SG_ 598 IxbrSts3Ax4_WhlAccnLgtLimMaxLe 300;
BA_REL_ "GenSigFirstTimeoutTime" BU_SG_REL_ VCM SG_ 598 IxbrSts1Ax6_WhlRdEstmdRi 3000;
BA_REL_ "GenSigTimeoutTime" BU_SG_REL_ VCM SG_ 598 IxbrSts1Ax6_WhlRdEstmdRi 300;
BA_REL_ "GenSigFirstTimeoutTime" BU_SG_REL_ VCM SG_ 598 IxbrSts1Ax4_WhlRdEstmdRi 3000;
BA_REL_ "GenSigTimeoutTime" BU_SG_REL_ VCM SG_ 598 IxbrSts1Ax4_WhlRdEstmdRi 300;
BA_REL_ "GenSigFirstTimeoutTime" BU_SG_REL_ VCM SG_ 598 IxbrSts3Ax4_WhlAccnLgtLimMaxRi 3000;
BA_REL_ "GenSigTimeoutTime" BU_SG_REL_ VCM SG_ 598 IxbrSts3Ax4_WhlAccnLgtLimMaxRi 300;
BA_REL_ "GenSigFirstTimeoutTime" BU_SG_REL_ VCM SG_ 598 IxbrSts2Ax4_WhlSlipLimPrpnRi 3000;
BA_REL_ "GenSigTimeoutTime" BU_SG_REL_ VCM SG_ 598 IxbrSts2Ax4_WhlSlipLimPrpnRi 300;
BA_REL_ "GenSigFirstTimeoutTime" BU_SG_REL_ VCM SG_ 598 IxbrSts1Ax5_WhlRdEstmdLe 3000;
BA_REL_ "GenSigTimeoutTime" BU_SG_REL_ VCM SG_ 598 IxbrSts1Ax5_WhlRdEstmdLe 300;
BA_REL_ "GenSigFirstTimeoutTime" BU_SG_REL_ VCM SG_ 598 IxbrSts2Ax4_WhlSlipLimPrpnLe 3000;
BA_REL_ "GenSigTimeoutTime" BU_SG_REL_ VCM SG_ 598 IxbrSts2Ax4_WhlSlipLimPrpnLe 300;
BA_REL_ "GenSigFirstTimeoutTime" BU_SG_REL_ VCM SG_ 598 IxbrSts3Ax5_WhlAccnLgtLimMaxLe 3000;
BA_REL_ "GenSigTimeoutTime" BU_SG_REL_ VCM SG_ 598 IxbrSts3Ax5_WhlAccnLgtLimMaxLe 300;
BA_REL_ "GenSigFirstTimeoutTime" BU_SG_REL_ VCM SG_ 598 IxbrSts2Ax5_WhlSlipLimPrpnLe 3000;
BA_REL_ "GenSigTimeoutTime" BU_SG_REL_ VCM SG_ 598 IxbrSts2Ax5_WhlSlipLimPrpnLe 300;
BA_REL_ "GenSigFirstTimeoutTime" BU_SG_REL_ VCM SG_ 598 IxbrSts1Ax4_CRC 3000;
BA_REL_ "GenSigTimeoutTime" BU_SG_REL_ VCM SG_ 598 IxbrSts1Ax4_CRC 300;
BA_REL_ "GenSigFirstTimeoutTime" BU_SG_REL_ VCM SG_ 598 IxbrSts1Ax5_WhlRdEstmdRi 3000;
BA_REL_ "GenSigTimeoutTime" BU_SG_REL_ VCM SG_ 598 IxbrSts1Ax5_WhlRdEstmdRi 300;
BA_REL_ "GenSigFirstTimeoutTime" BU_SG_REL_ VCM SG_ 596 IxbrSts1Ax1_WhlRdEstmdRi 3000;
BA_REL_ "GenSigTimeoutTime" BU_SG_REL_ VCM SG_ 596 IxbrSts1Ax1_WhlRdEstmdRi 300;
BA_REL_ "GenSigFirstTimeoutTime" BU_SG_REL_ VCM SG_ 596 IxbrSts3Ax3_WhlAccnLgtLimMaxLe 3000;
BA_REL_ "GenSigTimeoutTime" BU_SG_REL_ VCM SG_ 596 IxbrSts3Ax3_WhlAccnLgtLimMaxLe 300;
BA_REL_ "GenSigFirstTimeoutTime" BU_SG_REL_ VCM SG_ 596 IxbrSts3Ax1_WhlAccnLgtLimMinRi 3000;
BA_REL_ "GenSigTimeoutTime" BU_SG_REL_ VCM SG_ 596 IxbrSts3Ax1_WhlAccnLgtLimMinRi 300;
BA_REL_ "GenSigFirstTimeoutTime" BU_SG_REL_ VCM SG_ 596 IxbrSts3Ax3_CRC 3000;
BA_REL_ "GenSigTimeoutTime" BU_SG_REL_ VCM SG_ 596 IxbrSts3Ax3_CRC 300;
BA_REL_ "GenSigFirstTimeoutTime" BU_SG_REL_ VCM SG_ 596 IxbrSts2Ax3_WhlSlipLimBrkngRi 3000;
BA_REL_ "GenSigTimeoutTime" BU_SG_REL_ VCM SG_ 596 IxbrSts2Ax3_WhlSlipLimBrkngRi 300;
BA_REL_ "GenSigFirstTimeoutTime" BU_SG_REL_ VCM SG_ 596 IxbrSts3Ax1_CRC 3000;
BA_REL_ "GenSigTimeoutTime" BU_SG_REL_ VCM SG_ 596 IxbrSts3Ax1_CRC 300;
BA_REL_ "GenSigFirstTimeoutTime" BU_SG_REL_ VCM SG_ 596 IxbrSts2Ax3_WhlSlipLimPrpnRi 3000;
BA_REL_ "GenSigTimeoutTime" BU_SG_REL_ VCM SG_ 596 IxbrSts2Ax3_WhlSlipLimPrpnRi 300;
BA_REL_ "GenSigFirstTimeoutTime" BU_SG_REL_ VCM SG_ 596 IxbrSts2Ax1_WhlSlipLimPrpnLe 3000;
BA_REL_ "GenSigTimeoutTime" BU_SG_REL_ VCM SG_ 596 IxbrSts2Ax1_WhlSlipLimPrpnLe 300;
BA_REL_ "GenSigFirstTimeoutTime" BU_SG_REL_ VCM SG_ 596 IxbrSts3Ax3_WhlAccnLgtLimMinLe 3000;
BA_REL_ "GenSigTimeoutTime" BU_SG_REL_ VCM SG_ 596 IxbrSts3Ax3_WhlAccnLgtLimMinLe 300;
BA_REL_ "GenSigFirstTimeoutTime" BU_SG_REL_ VCM SG_ 596 IxbrSts1Ax1_SqC 3000;
BA_REL_ "GenSigTimeoutTime" BU_SG_REL_ VCM SG_ 596 IxbrSts1Ax1_SqC 300;
BA_REL_ "GenSigFirstTimeoutTime" BU_SG_REL_ VCM SG_ 596 IxbrSts2Ax3_CRC 3000;
BA_REL_ "GenSigTimeoutTime" BU_SG_REL_ VCM SG_ 596 IxbrSts2Ax3_CRC 300;
BA_REL_ "GenSigFirstTimeoutTime" BU_SG_REL_ VCM SG_ 596 IxbrSts1Ax2_WhlRdEstmdLe 3000;
BA_REL_ "GenSigTimeoutTime" BU_SG_REL_ VCM SG_ 596 IxbrSts1Ax2_WhlRdEstmdLe 300;
BA_REL_ "GenSigFirstTimeoutTime" BU_SG_REL_ VCM SG_ 596 IxbrSts1Ax1_CRC 3000;
BA_REL_ "GenSigTimeoutTime" BU_SG_REL_ VCM SG_ 596 IxbrSts1Ax1_CRC 300;
BA_REL_ "GenSigFirstTimeoutTime" BU_SG_REL_ VCM SG_ 596 IxbrSts1Ax3_SqC 3000;
BA_REL_ "GenSigTimeoutTime" BU_SG_REL_ VCM SG_ 596 IxbrSts1Ax3_SqC 300;
BA_REL_ "GenSigFirstTimeoutTime" BU_SG_REL_ VCM SG_ 596 IxbrSts1Ax3_WhlRdEstmdLe 3000;
BA_REL_ "GenSigTimeoutTime" BU_SG_REL_ VCM SG_ 596 IxbrSts1Ax3_WhlRdEstmdLe 300;
BA_REL_ "GenSigFirstTimeoutTime" BU_SG_REL_ VCM SG_ 596 IxbrSts2Ax2_CRC 3000;
BA_REL_ "GenSigTimeoutTime" BU_SG_REL_ VCM SG_ 596 IxbrSts2Ax2_CRC 300;
BA_REL_ "GenSigFirstTimeoutTime" BU_SG_REL_ VCM SG_ 596 IxbrSts2Ax2_WhlSlipLimBrkngRi 3000;
BA_REL_ "GenSigTimeoutTime" BU_SG_REL_ VCM SG_ 596 IxbrSts2Ax2_WhlSlipLimBrkngRi 300;
BA_REL_ "GenSigFirstTimeoutTime" BU_SG_REL_ VCM SG_ 596 IxbrSts2Ax1_WhlSlipLimPrpnRi 3000;
BA_REL_ "GenSigTimeoutTime" BU_SG_REL_ VCM SG_ 596 IxbrSts2Ax1_WhlSlipLimPrpnRi 300;
BA_REL_ "GenSigFirstTimeoutTime" BU_SG_REL_ VCM SG_ 596 IxbrSts3Ax1_WhlAccnLgtLimMinLe 3000;
BA_REL_ "GenSigTimeoutTime" BU_SG_REL_ VCM SG_ 596 IxbrSts3Ax1_WhlAccnLgtLimMinLe 300;
BA_REL_ "GenSigFirstTimeoutTime" BU_SG_REL_ VCM SG_ 596 IxbrSts3Ax2_WhlAccnLgtLimMaxRi 3000;
BA_REL_ "GenSigTimeoutTime" BU_SG_REL_ VCM SG_ 596 IxbrSts3Ax2_WhlAccnLgtLimMaxRi 300;
BA_REL_ "GenSigFirstTimeoutTime" BU_SG_REL_ VCM SG_ 596 IxbrSts3Ax2_WhlAccnLgtLimMinLe 3000;
BA_REL_ "GenSigTimeoutTime" BU_SG_REL_ VCM SG_ 596 IxbrSts3Ax2_WhlAccnLgtLimMinLe 300;
BA_REL_ "GenSigFirstTimeoutTime" BU_SG_REL_ VCM SG_ 596 IxbrSts2Ax2_WhlSlipLimBrkngLe 3000;
BA_REL_ "GenSigTimeoutTime" BU_SG_REL_ VCM SG_ 596 IxbrSts2Ax2_WhlSlipLimBrkngLe 300;
BA_REL_ "GenSigFirstTimeoutTime" BU_SG_REL_ VCM SG_ 596 IxbrSts3Ax1_WhlAccnLgtLimMaxLe 3000;
BA_REL_ "GenSigTimeoutTime" BU_SG_REL_ VCM SG_ 596 IxbrSts3Ax1_WhlAccnLgtLimMaxLe 300;
BA_REL_ "GenSigFirstTimeoutTime" BU_SG_REL_ VCM SG_ 596 IxbrSts1Ax1_WhlRdEstmdLe 3000;
BA_REL_ "GenSigTimeoutTime" BU_SG_REL_ VCM SG_ 596 IxbrSts1Ax1_WhlRdEstmdLe 300;
BA_REL_ "GenSigFirstTimeoutTime" BU_SG_REL_ VCM SG_ 596 IxbrSts2Ax1_WhlSlipLimBrkngLe 3000;
BA_REL_ "GenSigTimeoutTime" BU_SG_REL_ VCM SG_ 596 IxbrSts2Ax1_WhlSlipLimBrkngLe 300;
BA_REL_ "GenSigFirstTimeoutTime" BU_SG_REL_ VCM SG_ 596 IxbrSts3Ax3_SqC 3000;
BA_REL_ "GenSigTimeoutTime" BU_SG_REL_ VCM SG_ 596 IxbrSts3Ax3_SqC 300;
BA_REL_ "GenSigFirstTimeoutTime" BU_SG_REL_ VCM SG_ 596 IxbrSts3Ax1_SqC 3000;
BA_REL_ "GenSigTimeoutTime" BU_SG_REL_ VCM SG_ 596 IxbrSts3Ax1_SqC 300;
BA_REL_ "GenSigFirstTimeoutTime" BU_SG_REL_ VCM SG_ 596 IxbrSts3Ax1_WhlAccnLgtLimMaxRi 3000;
BA_REL_ "GenSigTimeoutTime" BU_SG_REL_ VCM SG_ 596 IxbrSts3Ax1_WhlAccnLgtLimMaxRi 300;
BA_REL_ "GenSigFirstTimeoutTime" BU_SG_REL_ VCM SG_ 596 IxbrSts2Ax3_SqC 3000;
BA_REL_ "GenSigTimeoutTime" BU_SG_REL_ VCM SG_ 596 IxbrSts2Ax3_SqC 300;
BA_REL_ "GenSigFirstTimeoutTime" BU_SG_REL_ VCM SG_ 596 IxbrSts1Ax2_CRC 3000;
BA_REL_ "GenSigTimeoutTime" BU_SG_REL_ VCM SG_ 596 IxbrSts1Ax2_CRC 300;
BA_REL_ "GenSigFirstTimeoutTime" BU_SG_REL_ VCM SG_ 596 IxbrSts1Ax3_CRC 3000;
BA_REL_ "GenSigTimeoutTime" BU_SG_REL_ VCM SG_ 596 IxbrSts1Ax3_CRC 300;
BA_REL_ "GenSigFirstTimeoutTime" BU_SG_REL_ VCM SG_ 596 IxbrSts2Ax1_SqC 3000;
BA_REL_ "GenSigTimeoutTime" BU_SG_REL_ VCM SG_ 596 IxbrSts2Ax1_SqC 300;
BA_REL_ "GenSigFirstTimeoutTime" BU_SG_REL_ VCM SG_ 596 IxbrSts3Ax3_WhlAccnLgtLimMinRi 3000;
BA_REL_ "GenSigTimeoutTime" BU_SG_REL_ VCM SG_ 596 IxbrSts3Ax3_WhlAccnLgtLimMinRi 300;
BA_REL_ "GenSigFirstTimeoutTime" BU_SG_REL_ VCM SG_ 596 IxbrSts3Ax2_SqC 3000;
BA_REL_ "GenSigTimeoutTime" BU_SG_REL_ VCM SG_ 596 IxbrSts3Ax2_SqC 300;
BA_REL_ "GenSigFirstTimeoutTime" BU_SG_REL_ VCM SG_ 596 IxbrSts1Ax2_WhlRdEstmdRi 3000;
BA_REL_ "GenSigTimeoutTime" BU_SG_REL_ VCM SG_ 596 IxbrSts1Ax2_WhlRdEstmdRi 300;
BA_REL_ "GenSigFirstTimeoutTime" BU_SG_REL_ VCM SG_ 596 IxbrSts1Ax2_SqC 3000;
BA_REL_ "GenSigTimeoutTime" BU_SG_REL_ VCM SG_ 596 IxbrSts1Ax2_SqC 300;
BA_REL_ "GenSigFirstTimeoutTime" BU_SG_REL_ VCM SG_ 596 IxbrSts2Ax3_WhlSlipLimBrkngLe 3000;
BA_REL_ "GenSigTimeoutTime" BU_SG_REL_ VCM SG_ 596 IxbrSts2Ax3_WhlSlipLimBrkngLe 300;
BA_REL_ "GenSigFirstTimeoutTime" BU_SG_REL_ VCM SG_ 596 IxbrSts3Ax2_WhlAccnLgtLimMinRi 3000;
BA_REL_ "GenSigTimeoutTime" BU_SG_REL_ VCM SG_ 596 IxbrSts3Ax2_WhlAccnLgtLimMinRi 300;
BA_REL_ "GenSigFirstTimeoutTime" BU_SG_REL_ VCM SG_ 596 IxbrSts3Ax2_CRC 3000;
BA_REL_ "GenSigTimeoutTime" BU_SG_REL_ VCM SG_ 596 IxbrSts3Ax2_CRC 300;
BA_REL_ "GenSigFirstTimeoutTime" BU_SG_REL_ VCM SG_ 596 IxbrSts2Ax3_WhlSlipLimPrpnLe 3000;
BA_REL_ "GenSigTimeoutTime" BU_SG_REL_ VCM SG_ 596 IxbrSts2Ax3_WhlSlipLimPrpnLe 300;
BA_REL_ "GenSigFirstTimeoutTime" BU_SG_REL_ VCM SG_ 596 IxbrSts2Ax2_WhlSlipLimPrpnLe 3000;
BA_REL_ "GenSigTimeoutTime" BU_SG_REL_ VCM SG_ 596 IxbrSts2Ax2_WhlSlipLimPrpnLe 300;
BA_REL_ "GenSigFirstTimeoutTime" BU_SG_REL_ VCM SG_ 596 IxbrSts2Ax1_CRC 3000;
BA_REL_ "GenSigTimeoutTime" BU_SG_REL_ VCM SG_ 596 IxbrSts2Ax1_CRC 300;
BA_REL_ "GenSigFirstTimeoutTime" BU_SG_REL_ VCM SG_ 596 IxbrSts3Ax2_WhlAccnLgtLimMaxLe 3000;
BA_REL_ "GenSigTimeoutTime" BU_SG_REL_ VCM SG_ 596 IxbrSts3Ax2_WhlAccnLgtLimMaxLe 300;
BA_REL_ "GenSigFirstTimeoutTime" BU_SG_REL_ VCM SG_ 596 IxbrSts3Ax3_WhlAccnLgtLimMaxRi 3000;
BA_REL_ "GenSigTimeoutTime" BU_SG_REL_ VCM SG_ 596 IxbrSts3Ax3_WhlAccnLgtLimMaxRi 300;
BA_REL_ "GenSigFirstTimeoutTime" BU_SG_REL_ VCM SG_ 596 IxbrSts1Ax3_WhlRdEstmdRi 3000;
BA_REL_ "GenSigTimeoutTime" BU_SG_REL_ VCM SG_ 596 IxbrSts1Ax3_WhlRdEstmdRi 300;
BA_REL_ "GenSigFirstTimeoutTime" BU_SG_REL_ VCM SG_ 596 IxbrSts2Ax1_WhlSlipLimBrkngRi 3000;
BA_REL_ "GenSigTimeoutTime" BU_SG_REL_ VCM SG_ 596 IxbrSts2Ax1_WhlSlipLimBrkngRi 300;
BA_REL_ "GenSigFirstTimeoutTime" BU_SG_REL_ VCM SG_ 596 IxbrSts2Ax2_SqC 3000;
BA_REL_ "GenSigTimeoutTime" BU_SG_REL_ VCM SG_ 596 IxbrSts2Ax2_SqC 300;
BA_REL_ "GenSigFirstTimeoutTime" BU_SG_REL_ VCM SG_ 596 IxbrSts2Ax2_WhlSlipLimPrpnRi 3000;
BA_REL_ "GenSigTimeoutTime" BU_SG_REL_ VCM SG_ 596 IxbrSts2Ax2_WhlSlipLimPrpnRi 300;
BA_REL_ "GenSigFirstTimeoutTime" BU_SG_REL_ VCM SG_ 298 Imu_LgtAccnQlty 3000;
BA_REL_ "GenSigTimeoutTime" BU_SG_REL_ VCM SG_ 298 Imu_LgtAccnQlty 100;
BA_REL_ "GenSigFirstTimeoutTime" BU_SG_REL_ VCM SG_ 298 Imu_AccnLat 3000;
BA_REL_ "GenSigTimeoutTime" BU_SG_REL_ VCM SG_ 298 Imu_AccnLat 100;
BA_REL_ "GenSigFirstTimeoutTime" BU_SG_REL_ VCM SG_ 298 Imu_PitchRate 3000;
BA_REL_ "GenSigTimeoutTime" BU_SG_REL_ VCM SG_ 298 Imu_PitchRate 100;
BA_REL_ "GenSigFirstTimeoutTime" BU_SG_REL_ VCM SG_ 298 Imu_YawRate 3000;
BA_REL_ "GenSigTimeoutTime" BU_SG_REL_ VCM SG_ 298 Imu_YawRate 100;
BA_REL_ "GenSigFirstTimeoutTime" BU_SG_REL_ VCM SG_ 298 Imu_Temp 3000;
BA_REL_ "GenSigTimeoutTime" BU_SG_REL_ VCM SG_ 298 Imu_Temp 100;
BA_REL_ "GenSigFirstTimeoutTime" BU_SG_REL_ VCM SG_ 298 Imu_RollRate 3000;
BA_REL_ "GenSigTimeoutTime" BU_SG_REL_ VCM SG_ 298 Imu_RollRate 100;
BA_REL_ "GenSigFirstTimeoutTime" BU_SG_REL_ VCM SG_ 298 Imu_YawRateQlty 3000;
BA_REL_ "GenSigTimeoutTime" BU_SG_REL_ VCM SG_ 298 Imu_YawRateQlty 100;
BA_REL_ "GenSigFirstTimeoutTime" BU_SG_REL_ VCM SG_ 298 Imu_PitchRateQlty 3000;
BA_REL_ "GenSigTimeoutTime" BU_SG_REL_ VCM SG_ 298 Imu_PitchRateQlty 100;
BA_REL_ "GenSigFirstTimeoutTime" BU_SG_REL_ VCM SG_ 298 Imu_RollRateQlty 3000;
BA_REL_ "GenSigTimeoutTime" BU_SG_REL_ VCM SG_ 298 Imu_RollRateQlty 100;
BA_REL_ "GenSigFirstTimeoutTime" BU_SG_REL_ VCM SG_ 298 Imu_LgtAccn 3000;
BA_REL_ "GenSigTimeoutTime" BU_SG_REL_ VCM SG_ 298 Imu_LgtAccn 100;
BA_REL_ "GenSigFirstTimeoutTime" BU_SG_REL_ VCM SG_ 298 Imu_SqC 3000;
BA_REL_ "GenSigTimeoutTime" BU_SG_REL_ VCM SG_ 298 Imu_SqC 100;
BA_REL_ "GenSigFirstTimeoutTime" BU_SG_REL_ VCM SG_ 298 Imu_CRC 3000;
BA_REL_ "GenSigTimeoutTime" BU_SG_REL_ VCM SG_ 298 Imu_CRC 100;
BA_REL_ "GenSigFirstTimeoutTime" BU_SG_REL_ VCM SG_ 298 Imu_AccnLatQlty 3000;
BA_REL_ "GenSigTimeoutTime" BU_SG_REL_ VCM SG_ 298 Imu_AccnLatQlty 100;
BA_REL_ "GenSigFirstTimeoutTime" BU_SG_REL_ VCM SG_ 298 Imu_AccnVertQlty 3000;
BA_REL_ "GenSigTimeoutTime" BU_SG_REL_ VCM SG_ 298 Imu_AccnVertQlty 100;
BA_REL_ "GenSigFirstTimeoutTime" BU_SG_REL_ VCM SG_ 298 Imu_AccnVert 3000;
BA_REL_ "GenSigTimeoutTime" BU_SG_REL_ VCM SG_ 298 Imu_AccnVert 100;
BA_REL_ "GenSigFirstTimeoutTime" BU_SG_REL_ VCM SG_ 594 CpbtyAxle5_BrkEgyCpctyLe 3000;
BA_REL_ "GenSigTimeoutTime" BU_SG_REL_ VCM SG_ 594 CpbtyAxle5_BrkEgyCpctyLe 300;
BA_REL_ "GenSigFirstTimeoutTime" BU_SG_REL_ VCM SG_ 594 CpbtyAxle4_TqCpbtyRateQltyLe 3000;
BA_REL_ "GenSigTimeoutTime" BU_SG_REL_ VCM SG_ 594 CpbtyAxle4_TqCpbtyRateQltyLe 300;
BA_REL_ "GenSigFirstTimeoutTime" BU_SG_REL_ VCM SG_ 594 CpbtyAxle4_TqCpbtyRateDecRi 3000;
BA_REL_ "GenSigTimeoutTime" BU_SG_REL_ VCM SG_ 594 CpbtyAxle4_TqCpbtyRateDecRi 300;
BA_REL_ "GenSigFirstTimeoutTime" BU_SG_REL_ VCM SG_ 594 CpbtyAxle4_BrkEgyCpctyQltyRi 3000;
BA_REL_ "GenSigTimeoutTime" BU_SG_REL_ VCM SG_ 594 CpbtyAxle4_BrkEgyCpctyQltyRi 300;
BA_REL_ "GenSigFirstTimeoutTime" BU_SG_REL_ VCM SG_ 594 CpbtyAxle4_TqCpbtyMinRi 3000;
BA_REL_ "GenSigTimeoutTime" BU_SG_REL_ VCM SG_ 594 CpbtyAxle4_TqCpbtyMinRi 300;
BA_REL_ "GenSigFirstTimeoutTime" BU_SG_REL_ VCM SG_ 594 CpbtyAxle5_TqCpbtyMaxLe 3000;
BA_REL_ "GenSigTimeoutTime" BU_SG_REL_ VCM SG_ 594 CpbtyAxle5_TqCpbtyMaxLe 300;
BA_REL_ "GenSigFirstTimeoutTime" BU_SG_REL_ VCM SG_ 594 CpbtyAxle5_TqCpbtyQltyLe 3000;
BA_REL_ "GenSigTimeoutTime" BU_SG_REL_ VCM SG_ 594 CpbtyAxle5_TqCpbtyQltyLe 300;
BA_REL_ "GenSigFirstTimeoutTime" BU_SG_REL_ VCM SG_ 594 CpbtyAxle5_PadWearRi 3000;
BA_REL_ "GenSigTimeoutTime" BU_SG_REL_ VCM SG_ 594 CpbtyAxle5_PadWearRi 300;
BA_REL_ "GenSigFirstTimeoutTime" BU_SG_REL_ VCM SG_ 594 CpbtyAxle5_TqCpbtyRateIncLeRi 3000;
BA_REL_ "GenSigTimeoutTime" BU_SG_REL_ VCM SG_ 594 CpbtyAxle5_TqCpbtyRateIncLeRi 300;
BA_REL_ "GenSigFirstTimeoutTime" BU_SG_REL_ VCM SG_ 594 CpbtyAxle6_TqCpbtyRateQltyLe 3000;
BA_REL_ "GenSigTimeoutTime" BU_SG_REL_ VCM SG_ 594 CpbtyAxle6_TqCpbtyRateQltyLe 300;
BA_REL_ "GenSigFirstTimeoutTime" BU_SG_REL_ VCM SG_ 594 CpbtyAxle5_TqCpbtyRateDecLe 3000;
BA_REL_ "GenSigTimeoutTime" BU_SG_REL_ VCM SG_ 594 CpbtyAxle5_TqCpbtyRateDecLe 300;
BA_REL_ "GenSigFirstTimeoutTime" BU_SG_REL_ VCM SG_ 594 CpbtyAxle6_TqCpbtyMinRi 3000;
BA_REL_ "GenSigTimeoutTime" BU_SG_REL_ VCM SG_ 594 CpbtyAxle6_TqCpbtyMinRi 300;
BA_REL_ "GenSigFirstTimeoutTime" BU_SG_REL_ VCM SG_ 594 CpbtyAxle6_BrkEgyCpctyRi 3000;
BA_REL_ "GenSigTimeoutTime" BU_SG_REL_ VCM SG_ 594 CpbtyAxle6_BrkEgyCpctyRi 300;
BA_REL_ "GenSigFirstTimeoutTime" BU_SG_REL_ VCM SG_ 594 CpbtyAxle6_TqCpbtyRateQltyRi 3000;
BA_REL_ "GenSigTimeoutTime" BU_SG_REL_ VCM SG_ 594 CpbtyAxle6_TqCpbtyRateQltyRi 300;
BA_REL_ "GenSigFirstTimeoutTime" BU_SG_REL_ VCM SG_ 594 CpbtyAxle6_TqCpbtyRateIncLeRi 3000;
BA_REL_ "GenSigTimeoutTime" BU_SG_REL_ VCM SG_ 594 CpbtyAxle6_TqCpbtyRateIncLeRi 300;
BA_REL_ "GenSigFirstTimeoutTime" BU_SG_REL_ VCM SG_ 594 CpbtyAxle5_TqCpbtyMaxRi 3000;
BA_REL_ "GenSigTimeoutTime" BU_SG_REL_ VCM SG_ 594 CpbtyAxle5_TqCpbtyMaxRi 300;
BA_REL_ "GenSigFirstTimeoutTime" BU_SG_REL_ VCM SG_ 594 CpbtyAxle5_CRC 3000;
BA_REL_ "GenSigTimeoutTime" BU_SG_REL_ VCM SG_ 594 CpbtyAxle5_CRC 300;
BA_REL_ "GenSigFirstTimeoutTime" BU_SG_REL_ VCM SG_ 594 CpbtyAxle6_TqCpbtyRateDecLe 3000;
BA_REL_ "GenSigTimeoutTime" BU_SG_REL_ VCM SG_ 594 CpbtyAxle6_TqCpbtyRateDecLe 300;
BA_REL_ "GenSigFirstTimeoutTime" BU_SG_REL_ VCM SG_ 594 CpbtyAxle5_SlipCtrlEna 3000;
BA_REL_ "GenSigTimeoutTime" BU_SG_REL_ VCM SG_ 594 CpbtyAxle5_SlipCtrlEna 300;
BA_REL_ "GenSigFirstTimeoutTime" BU_SG_REL_ VCM SG_ 594 CpbtyAxle5_PadWearQltyLe 3000;
BA_REL_ "GenSigTimeoutTime" BU_SG_REL_ VCM SG_ 594 CpbtyAxle5_PadWearQltyLe 300;
BA_REL_ "GenSigFirstTimeoutTime" BU_SG_REL_ VCM SG_ 594 CpbtyAxle6_BrkEgyCpctyQltyRi 3000;
BA_REL_ "GenSigTimeoutTime" BU_SG_REL_ VCM SG_ 594 CpbtyAxle6_BrkEgyCpctyQltyRi 300;
BA_REL_ "GenSigFirstTimeoutTime" BU_SG_REL_ VCM SG_ 594 CpbtyAxle5_BrkEgyCpctyQltyLe 3000;
BA_REL_ "GenSigTimeoutTime" BU_SG_REL_ VCM SG_ 594 CpbtyAxle5_BrkEgyCpctyQltyLe 300;
BA_REL_ "GenSigFirstTimeoutTime" BU_SG_REL_ VCM SG_ 594 CpbtyAxle6_PadWearQltyRi 3000;
BA_REL_ "GenSigTimeoutTime" BU_SG_REL_ VCM SG_ 594 CpbtyAxle6_PadWearQltyRi 300;
BA_REL_ "GenSigFirstTimeoutTime" BU_SG_REL_ VCM SG_ 594 CpbtyAxle6_TqCpbtyMaxRi 3000;
BA_REL_ "GenSigTimeoutTime" BU_SG_REL_ VCM SG_ 594 CpbtyAxle6_TqCpbtyMaxRi 300;
BA_REL_ "GenSigFirstTimeoutTime" BU_SG_REL_ VCM SG_ 594 CpbtyAxle4_TqCpbtyQltyLe 3000;
BA_REL_ "GenSigTimeoutTime" BU_SG_REL_ VCM SG_ 594 CpbtyAxle4_TqCpbtyQltyLe 300;
BA_REL_ "GenSigFirstTimeoutTime" BU_SG_REL_ VCM SG_ 594 CpbtyAxle4_SlipCtrlEna 3000;
BA_REL_ "GenSigTimeoutTime" BU_SG_REL_ VCM SG_ 594 CpbtyAxle4_SlipCtrlEna 300;
BA_REL_ "GenSigFirstTimeoutTime" BU_SG_REL_ VCM SG_ 594 CpbtyAxle4_BrkEgyCpctyRi 3000;
BA_REL_ "GenSigTimeoutTime" BU_SG_REL_ VCM SG_ 594 CpbtyAxle4_BrkEgyCpctyRi 300;
BA_REL_ "GenSigFirstTimeoutTime" BU_SG_REL_ VCM SG_ 594 CpbtyAxle6_TqCpbtyQltyRi 3000;
BA_REL_ "GenSigTimeoutTime" BU_SG_REL_ VCM SG_ 594 CpbtyAxle6_TqCpbtyQltyRi 300;
BA_REL_ "GenSigFirstTimeoutTime" BU_SG_REL_ VCM SG_ 594 CpbtyAxle6_CRC 3000;
BA_REL_ "GenSigTimeoutTime" BU_SG_REL_ VCM SG_ 594 CpbtyAxle6_CRC 300;
BA_REL_ "GenSigFirstTimeoutTime" BU_SG_REL_ VCM SG_ 594 CpbtyAxle5_TqCpbtyRateQltyLe 3000;
BA_REL_ "GenSigTimeoutTime" BU_SG_REL_ VCM SG_ 594 CpbtyAxle5_TqCpbtyRateQltyLe 300;
BA_REL_ "GenSigFirstTimeoutTime" BU_SG_REL_ VCM SG_ 594 CpbtyAxle4_TqCpbtyMaxLe 3000;
BA_REL_ "GenSigTimeoutTime" BU_SG_REL_ VCM SG_ 594 CpbtyAxle4_TqCpbtyMaxLe 300;
BA_REL_ "GenSigFirstTimeoutTime" BU_SG_REL_ VCM SG_ 594 CpbtyAxle4_PadWearRi 3000;
BA_REL_ "GenSigTimeoutTime" BU_SG_REL_ VCM SG_ 594 CpbtyAxle4_PadWearRi 300;
BA_REL_ "GenSigFirstTimeoutTime" BU_SG_REL_ VCM SG_ 594 CpbtyAxle6_TqCpbtyMinLe 3000;
BA_REL_ "GenSigTimeoutTime" BU_SG_REL_ VCM SG_ 594 CpbtyAxle6_TqCpbtyMinLe 300;
BA_REL_ "GenSigFirstTimeoutTime" BU_SG_REL_ VCM SG_ 594 CpbtyAxle4_CRC 3000;
BA_REL_ "GenSigTimeoutTime" BU_SG_REL_ VCM SG_ 594 CpbtyAxle4_CRC 300;
BA_REL_ "GenSigFirstTimeoutTime" BU_SG_REL_ VCM SG_ 594 CpbtyAxle4_SqC 3000;
BA_REL_ "GenSigTimeoutTime" BU_SG_REL_ VCM SG_ 594 CpbtyAxle4_SqC 300;
BA_REL_ "GenSigFirstTimeoutTime" BU_SG_REL_ VCM SG_ 594 CpbtyAxle5_TqCpbtyMinLe 3000;
BA_REL_ "GenSigTimeoutTime" BU_SG_REL_ VCM SG_ 594 CpbtyAxle5_TqCpbtyMinLe 300;
BA_REL_ "GenSigFirstTimeoutTime" BU_SG_REL_ VCM SG_ 594 CpbtyAxle6_PadWearQltyLe 3000;
BA_REL_ "GenSigTimeoutTime" BU_SG_REL_ VCM SG_ 594 CpbtyAxle6_PadWearQltyLe 300;
BA_REL_ "GenSigFirstTimeoutTime" BU_SG_REL_ VCM SG_ 594 CpbtyAxle6_PadWearRi 3000;
BA_REL_ "GenSigTimeoutTime" BU_SG_REL_ VCM SG_ 594 CpbtyAxle6_PadWearRi 300;
BA_REL_ "GenSigFirstTimeoutTime" BU_SG_REL_ VCM SG_ 594 CpbtyAxle5_TqCpbtyRateQltyRi 3000;
BA_REL_ "GenSigTimeoutTime" BU_SG_REL_ VCM SG_ 594 CpbtyAxle5_TqCpbtyRateQltyRi 300;
BA_REL_ "GenSigFirstTimeoutTime" BU_SG_REL_ VCM SG_ 594 CpbtyAxle4_TqCpbtyQltyRi 3000;
BA_REL_ "GenSigTimeoutTime" BU_SG_REL_ VCM SG_ 594 CpbtyAxle4_TqCpbtyQltyRi 300;
BA_REL_ "GenSigFirstTimeoutTime" BU_SG_REL_ VCM SG_ 594 CpbtyAxle6_SlipCtrlEna 3000;
BA_REL_ "GenSigTimeoutTime" BU_SG_REL_ VCM SG_ 594 CpbtyAxle6_SlipCtrlEna 300;
BA_REL_ "GenSigFirstTimeoutTime" BU_SG_REL_ VCM SG_ 594 CpbtyAxle5_TqCpbtyQltyRi 3000;
BA_REL_ "GenSigTimeoutTime" BU_SG_REL_ VCM SG_ 594 CpbtyAxle5_TqCpbtyQltyRi 300;
BA_REL_ "GenSigFirstTimeoutTime" BU_SG_REL_ VCM SG_ 594 CpbtyAxle4_BrkEgyCpctyQltyLe 3000;
BA_REL_ "GenSigTimeoutTime" BU_SG_REL_ VCM SG_ 594 CpbtyAxle4_BrkEgyCpctyQltyLe 300;
BA_REL_ "GenSigFirstTimeoutTime" BU_SG_REL_ VCM SG_ 594 CpbtyAxle4_TqCpbtyMinLe 3000;
BA_REL_ "GenSigTimeoutTime" BU_SG_REL_ VCM SG_ 594 CpbtyAxle4_TqCpbtyMinLe 300;
BA_REL_ "GenSigFirstTimeoutTime" BU_SG_REL_ VCM SG_ 594 CpbtyAxle5_TqCpbtyMinRi 3000;
BA_REL_ "GenSigTimeoutTime" BU_SG_REL_ VCM SG_ 594 CpbtyAxle5_TqCpbtyMinRi 300;
BA_REL_ "GenSigFirstTimeoutTime" BU_SG_REL_ VCM SG_ 594 CpbtyAxle6_SqC 3000;
BA_REL_ "GenSigTimeoutTime" BU_SG_REL_ VCM SG_ 594 CpbtyAxle6_SqC 300;
BA_REL_ "GenSigFirstTimeoutTime" BU_SG_REL_ VCM SG_ 594 CpbtyAxle6_TqCpbtyRateDecRi 3000;
BA_REL_ "GenSigTimeoutTime" BU_SG_REL_ VCM SG_ 594 CpbtyAxle6_TqCpbtyRateDecRi 300;
BA_REL_ "GenSigFirstTimeoutTime" BU_SG_REL_ VCM SG_ 594 CpbtyAxle6_TqCpbtyRateIncLeLe 3000;
BA_REL_ "GenSigTimeoutTime" BU_SG_REL_ VCM SG_ 594 CpbtyAxle6_TqCpbtyRateIncLeLe 300;
BA_REL_ "GenSigFirstTimeoutTime" BU_SG_REL_ VCM SG_ 594 CpbtyAxle4_TqCpbtyRateDecLe 3000;
BA_REL_ "GenSigTimeoutTime" BU_SG_REL_ VCM SG_ 594 CpbtyAxle4_TqCpbtyRateDecLe 300;
BA_REL_ "GenSigFirstTimeoutTime" BU_SG_REL_ VCM SG_ 594 CpbtyAxle4_TqCpbtyRateQltyRi 3000;
BA_REL_ "GenSigTimeoutTime" BU_SG_REL_ VCM SG_ 594 CpbtyAxle4_TqCpbtyRateQltyRi 300;
BA_REL_ "GenSigFirstTimeoutTime" BU_SG_REL_ VCM SG_ 594 CpbtyAxle4_BrkEgyCpctyLe 3000;
BA_REL_ "GenSigTimeoutTime" BU_SG_REL_ VCM SG_ 594 CpbtyAxle4_BrkEgyCpctyLe 300;
BA_REL_ "GenSigFirstTimeoutTime" BU_SG_REL_ VCM SG_ 594 CpbtyAxle4_TqCpbtyMaxRi 3000;
BA_REL_ "GenSigTimeoutTime" BU_SG_REL_ VCM SG_ 594 CpbtyAxle4_TqCpbtyMaxRi 300;
BA_REL_ "GenSigFirstTimeoutTime" BU_SG_REL_ VCM SG_ 594 CpbtyAxle6_TqCpbtyMaxLe 3000;
BA_REL_ "GenSigTimeoutTime" BU_SG_REL_ VCM SG_ 594 CpbtyAxle6_TqCpbtyMaxLe 300;
BA_REL_ "GenSigFirstTimeoutTime" BU_SG_REL_ VCM SG_ 594 CpbtyAxle5_TqCpbtyRateIncLeLe 3000;
BA_REL_ "GenSigTimeoutTime" BU_SG_REL_ VCM SG_ 594 CpbtyAxle5_TqCpbtyRateIncLeLe 300;
BA_REL_ "GenSigFirstTimeoutTime" BU_SG_REL_ VCM SG_ 594 CpbtyAxle5_PadWearQltyRi 3000;
BA_REL_ "GenSigTimeoutTime" BU_SG_REL_ VCM SG_ 594 CpbtyAxle5_PadWearQltyRi 300;
BA_REL_ "GenSigFirstTimeoutTime" BU_SG_REL_ VCM SG_ 594 CpbtyAxle6_BrkEgyCpctyQltyLe 3000;
BA_REL_ "GenSigTimeoutTime" BU_SG_REL_ VCM SG_ 594 CpbtyAxle6_BrkEgyCpctyQltyLe 300;
BA_REL_ "GenSigFirstTimeoutTime" BU_SG_REL_ VCM SG_ 594 CpbtyAxle5_TqCpbtyRateDecRi 3000;
BA_REL_ "GenSigTimeoutTime" BU_SG_REL_ VCM SG_ 594 CpbtyAxle5_TqCpbtyRateDecRi 300;
BA_REL_ "GenSigFirstTimeoutTime" BU_SG_REL_ VCM SG_ 594 CpbtyAxle6_TqCpbtyQltyLe 3000;
BA_REL_ "GenSigTimeoutTime" BU_SG_REL_ VCM SG_ 594 CpbtyAxle6_TqCpbtyQltyLe 300;
BA_REL_ "GenSigFirstTimeoutTime" BU_SG_REL_ VCM SG_ 594 CpbtyAxle5_SqC 3000;
BA_REL_ "GenSigTimeoutTime" BU_SG_REL_ VCM SG_ 594 CpbtyAxle5_SqC 300;
BA_REL_ "GenSigFirstTimeoutTime" BU_SG_REL_ VCM SG_ 594 CpbtyAxle4_TqCpbtyRateIncLeRi 3000;
BA_REL_ "GenSigTimeoutTime" BU_SG_REL_ VCM SG_ 594 CpbtyAxle4_TqCpbtyRateIncLeRi 300;
BA_REL_ "GenSigFirstTimeoutTime" BU_SG_REL_ VCM SG_ 594 CpbtyAxle6_BrkEgyCpctyLe 3000;
BA_REL_ "GenSigTimeoutTime" BU_SG_REL_ VCM SG_ 594 CpbtyAxle6_BrkEgyCpctyLe 300;
BA_REL_ "GenSigFirstTimeoutTime" BU_SG_REL_ VCM SG_ 594 CpbtyAxle5_BrkEgyCpctyRi 3000;
BA_REL_ "GenSigTimeoutTime" BU_SG_REL_ VCM SG_ 594 CpbtyAxle5_BrkEgyCpctyRi 300;
BA_REL_ "GenSigFirstTimeoutTime" BU_SG_REL_ VCM SG_ 594 CpbtyAxle5_BrkEgyCpctyQltyRi 3000;
BA_REL_ "GenSigTimeoutTime" BU_SG_REL_ VCM SG_ 594 CpbtyAxle5_BrkEgyCpctyQltyRi 300;
BA_REL_ "GenSigFirstTimeoutTime" BU_SG_REL_ VCM SG_ 594 CpbtyAxle6_PadWearLe 3000;
BA_REL_ "GenSigTimeoutTime" BU_SG_REL_ VCM SG_ 594 CpbtyAxle6_PadWearLe 300;
BA_REL_ "GenSigFirstTimeoutTime" BU_SG_REL_ VCM SG_ 594 CpbtyAxle4_PadWearLe 3000;
BA_REL_ "GenSigTimeoutTime" BU_SG_REL_ VCM SG_ 594 CpbtyAxle4_PadWearLe 300;
BA_REL_ "GenSigFirstTimeoutTime" BU_SG_REL_ VCM SG_ 594 CpbtyAxle4_PadWearQltyRi 3000;
BA_REL_ "GenSigTimeoutTime" BU_SG_REL_ VCM SG_ 594 CpbtyAxle4_PadWearQltyRi 300;
BA_REL_ "GenSigFirstTimeoutTime" BU_SG_REL_ VCM SG_ 594 CpbtyAxle4_TqCpbtyRateIncLeLe 3000;
BA_REL_ "GenSigTimeoutTime" BU_SG_REL_ VCM SG_ 594 CpbtyAxle4_TqCpbtyRateIncLeLe 300;
BA_REL_ "GenSigFirstTimeoutTime" BU_SG_REL_ VCM SG_ 594 CpbtyAxle5_PadWearLe 3000;
BA_REL_ "GenSigTimeoutTime" BU_SG_REL_ VCM SG_ 594 CpbtyAxle5_PadWearLe 300;
BA_REL_ "GenSigFirstTimeoutTime" BU_SG_REL_ VCM SG_ 594 CpbtyAxle4_PadWearQltyLe 3000;
BA_REL_ "GenSigTimeoutTime" BU_SG_REL_ VCM SG_ 594 CpbtyAxle4_PadWearQltyLe 300;
VAL_ 1456 FasDriver_ISig_3 15 "FasDriver_NotAvailable" 14 "FasDriver_Error" 13 "FasDriver_Spare3" 12 "FasDriver_Spare2" 11 "FasDriver_Spare1" 10 "FasDriver_Driver10" 9 "FasDriver_Driver9" 8 "FasDriver_Driver8" 7 "FasDriver_Driver7" 6 "FasDriver_Driver6" 5 "FasDriver_Driver5" 4 "FasDriver_Driver4" 3 "FasDriver_Driver3" 2 "FasDriver_Driver2" 1 "FasDriver_Driver1" 0 "FasDriver_DefaultDriver" ;
VAL_ 1456 ActualFasPersSettingsButton_ISig 7 "FasPersSettingsButton_NotAvailable" 6 "FasPersSettingsButton_Error" 5 "FasPersSettingsButton_Spare" 4 "FasPersSettingsButton_UserDefinedButton" 3 "FasPersSettingsButton_PresetButtonHeavy" 2 "FasPersSettingsButton_PresetButtonFirm" 1 "FasPersSettingsButton_PresetButtonLight" 0 "FasPersSettingsButton_PresetButtonDefault" ;
VAL_ 455 OverSteerGuidanceStatus_ISig_3 3 "InactiveActive_NotAvailable" 2 "InactiveActive_Error" 1 "InactiveActive_Active" 0 "InactiveActive_Inactive" ;
VAL_ 455 FASFullyOperational 3 "FASFullyOperational_NotAvailable" 2 "FASFullyOperational_Error" 1 "FASFullyOperational_FASFullyOperational" 0 "FASFullyOperational_FASNotFullyOperational" ;
VAL_ 455 FASSaturated 3 "FASSaturated_NotAvailable" 2 "FASSaturated_Error" 1 "FASSaturated_FAS_IsSaturated" 0 "FASSaturated_FAS_IsNotSaturated" ;
VAL_ 455 FASFunctionInControl 3 "FASFunctionInControl_NotAvailable" 2 "FASFunctionInControl_Error" 1 "FASFunctionInControl_FunctionInControl" 0 "FASFunctionInControl_DriverInControl" ;
VAL_ 275 SteeringCtrlModeRsp_Status 7 "SteeringCtrlModeStat_NotAvailable" 6 "SteeringCtrlModeStat_Error" 5 "SteeringCtrlModeStat_Spare" 4 "SteeringCtrlModeStat_Autonomous_Urgentbackup" 3 "SteeringCtrlModeStat_Autonomous_Backup" 2 "SteeringCtrlModeStat_Autonomous" 1 "SteeringCtrlModeStat_Manual_Degrade" 0 "SteeringCtrlModeStat_Manual" ;
VAL_ 275 SteeringCtrlModeRsp_Cap 7 "SteeringCtrlModeCap_NotAvailable" 6 "SteeringCtrlModeCap_Error" 5 "SteeringCtrlModeCap_Spare3" 4 "SteeringCtrlModeCap_Spare2" 3 "SteeringCtrlModeCap_Spare1" 2 "SteeringCtrlModeCap_AutonomousAndManual" 1 "SteeringCtrlModeCap_Autonomous" 0 "SteeringCtrlModeCap_Manual" ;
VAL_ 275 SteeringCtrlModeRsp_Active 3 "PassiveActive_NotAvailable" 2 "PassiveActive_Error" 1 "PassiveActive_Active" 0 "PassiveActive_Passive" ;
VAL_ 271 ZxbrStsVeh_RetEbiModSts 7 "EbiMode3bit_NotAvailable" 6 "EbiMode3bit_Error" 5 "EbiMode3bit_Spare2" 4 "EbiMode3bit_Spare1" 3 "EbiMode3bit_Spare0" 2 "EbiMode3bit_EnduranceBrakeIntegrationAllowed" 1 "EbiMode3bit_OnlyEnduranceBrakesAllowed" 0 "EbiMode3bit_NoEnduranceBrakeIntegrationAllowed" ;
VAL_ 271 ZxbrStsVeh_EbsCtrlModSts 3 "InactiveActive_NotAvailable" 2 "InactiveActive_Error" 1 "InactiveActive_Active" 0 "InactiveActive_Inactive" ;
VAL_ 271 ZxbrStsVeh_EbsHealthSts 7 "EbsHealthSts_NotAvailable" 6 "EbsHealthSts_Error" 5 "EbsHealthSts_ErrorFailover" 4 "EbsHealthSts_Spare" 3 "EbsHealthSts_Warning" 2 "EbsHealthSts_WarningAD" 1 "EbsHealthSts_FullyOperational" 0 "EbsHealthSts_SelfCheck" ;
VAL_ 271 ZxbrStsVeh_RetModSts 7 "RetModReq_NotAvailable" 6 "RetModReq_Error" 5 "RetModReq_Spare3" 4 "RetModReq_Spare2" 3 "RetModReq_Spare1" 2 "RetModReq_Maximum" 1 "RetModReq_Addition" 0 "RetModReq_Inactive" ;
VAL_ 271 ZxbrStsVeh_DrvrModSts 3 "DrvrModSts_NotAvailable" 2 "DrvrModSts_Error" 1 "DrvrModSts_L45" 0 "DrvrModSts_L012" ;
VAL_ 304 Sts2Axle4_WhlTqQltyLe 3 "OperationalDegraded_NotAvailable" 2 "OperationalDegraded_Error" 1 "OperationalDegraded_Degraded" 0 "OperationalDegraded_Operational" ;
VAL_ 304 Sts2Axle2_WhlTqQltyRi 3 "OperationalDegraded_NotAvailable" 2 "OperationalDegraded_Error" 1 "OperationalDegraded_Degraded" 0 "OperationalDegraded_Operational" ;
VAL_ 304 Sts2Axle2_WhlTqQltyLe 3 "OperationalDegraded_NotAvailable" 2 "OperationalDegraded_Error" 1 "OperationalDegraded_Degraded" 0 "OperationalDegraded_Operational" ;
VAL_ 304 Sts2Axle3_WhlTqQltyLe 3 "OperationalDegraded_NotAvailable" 2 "OperationalDegraded_Error" 1 "OperationalDegraded_Degraded" 0 "OperationalDegraded_Operational" ;
VAL_ 304 Sts2Axle1_WhlTqQltyRi 3 "OperationalDegraded_NotAvailable" 2 "OperationalDegraded_Error" 1 "OperationalDegraded_Degraded" 0 "OperationalDegraded_Operational" ;
VAL_ 304 Sts2Axle4_WhlTqQltyRi 3 "OperationalDegraded_NotAvailable" 2 "OperationalDegraded_Error" 1 "OperationalDegraded_Degraded" 0 "OperationalDegraded_Operational" ;
VAL_ 304 Sts2Axle6_WhlTqQltyLe 3 "OperationalDegraded_NotAvailable" 2 "OperationalDegraded_Error" 1 "OperationalDegraded_Degraded" 0 "OperationalDegraded_Operational" ;
VAL_ 304 Sts2Axle5_WhlTqQltyRi 3 "OperationalDegraded_NotAvailable" 2 "OperationalDegraded_Error" 1 "OperationalDegraded_Degraded" 0 "OperationalDegraded_Operational" ;
VAL_ 304 Sts2Axle6_WhlTqQltyRi 3 "OperationalDegraded_NotAvailable" 2 "OperationalDegraded_Error" 1 "OperationalDegraded_Degraded" 0 "OperationalDegraded_Operational" ;
VAL_ 304 Sts2Axle5_WhlTqQltyLe 3 "OperationalDegraded_NotAvailable" 2 "OperationalDegraded_Error" 1 "OperationalDegraded_Degraded" 0 "OperationalDegraded_Operational" ;
VAL_ 304 Sts2Axle1_WhlTqQltyLe 3 "OperationalDegraded_NotAvailable" 2 "OperationalDegraded_Error" 1 "OperationalDegraded_Degraded" 0 "OperationalDegraded_Operational" ;
VAL_ 304 Sts2Axle3_WhlTqQltyRi 3 "OperationalDegraded_NotAvailable" 2 "OperationalDegraded_Error" 1 "OperationalDegraded_Degraded" 0 "OperationalDegraded_Operational" ;
VAL_ 288 Sts1Axle6_WhlRotQltyLe 3 "OperationalDegraded_NotAvailable" 2 "OperationalDegraded_Error" 1 "OperationalDegraded_Degraded" 0 "OperationalDegraded_Operational" ;
VAL_ 288 Sts1Axle2_WhlRotQltyRi 3 "OperationalDegraded_NotAvailable" 2 "OperationalDegraded_Error" 1 "OperationalDegraded_Degraded" 0 "OperationalDegraded_Operational" ;
VAL_ 288 Sts1Axle1_WhlRotQltyRi 3 "OperationalDegraded_NotAvailable" 2 "OperationalDegraded_Error" 1 "OperationalDegraded_Degraded" 0 "OperationalDegraded_Operational" ;
VAL_ 288 Sts1Axle3_WhlRotQltyLe 3 "OperationalDegraded_NotAvailable" 2 "OperationalDegraded_Error" 1 "OperationalDegraded_Degraded" 0 "OperationalDegraded_Operational" ;
VAL_ 288 Sts1Axle1_WhlRotQltyLe 3 "OperationalDegraded_NotAvailable" 2 "OperationalDegraded_Error" 1 "OperationalDegraded_Degraded" 0 "OperationalDegraded_Operational" ;
VAL_ 288 Sts1Axle5_WhlRotQltyLe 3 "OperationalDegraded_NotAvailable" 2 "OperationalDegraded_Error" 1 "OperationalDegraded_Degraded" 0 "OperationalDegraded_Operational" ;
VAL_ 288 Sts1Axle5_WhlRotQltyRi 3 "OperationalDegraded_NotAvailable" 2 "OperationalDegraded_Error" 1 "OperationalDegraded_Degraded" 0 "OperationalDegraded_Operational" ;
VAL_ 288 Sts1Axle4_WhlRotQltyRi 3 "OperationalDegraded_NotAvailable" 2 "OperationalDegraded_Error" 1 "OperationalDegraded_Degraded" 0 "OperationalDegraded_Operational" ;
VAL_ 288 Sts1Axle3_WhlRotQltyRi 3 "OperationalDegraded_NotAvailable" 2 "OperationalDegraded_Error" 1 "OperationalDegraded_Degraded" 0 "OperationalDegraded_Operational" ;
VAL_ 288 Sts1Axle4_WhlRotQltyLe 3 "OperationalDegraded_NotAvailable" 2 "OperationalDegraded_Error" 1 "OperationalDegraded_Degraded" 0 "OperationalDegraded_Operational" ;
VAL_ 288 Sts1Axle2_WhlRotQltyLe 3 "OperationalDegraded_NotAvailable" 2 "OperationalDegraded_Error" 1 "OperationalDegraded_Degraded" 0 "OperationalDegraded_Operational" ;
VAL_ 288 Sts1Axle6_WhlRotQltyRi 3 "OperationalDegraded_NotAvailable" 2 "OperationalDegraded_Error" 1 "OperationalDegraded_Degraded" 0 "OperationalDegraded_Operational" ;
VAL_ 602 IxbrSts1Veh_AbsSts 7 "IxbrOperStatus_NotAvailable" 6 "IxbrOperStatus_Error" 5 "IxbrOperStatus_Spare3" 4 "IxbrOperStatus_Spare2" 3 "IxbrOperStatus_Spare1" 2 "IxbrOperStatus_OnReduced" 1 "IxbrOperStatus_OnOperational" 0 "IxbrOperStatus_Off" ;
VAL_ 602 IxbrSts1Veh_IxbrModSts 7 "IxbrModSts_NotAvailable" 6 "IxbrModSts_Error" 5 "IxbrModSts_Spare2" 4 "IxbrModSts_Spare1" 3 "IxbrModSts_Fault" 2 "IxbrModSts_NotAvailable1" 1 "IxbrModSts_Active" 0 "IxbrModSts_Available" ;
VAL_ 602 IxbrSts1Veh_EscSts 7 "IxbrOperStatus_NotAvailable" 6 "IxbrOperStatus_Error" 5 "IxbrOperStatus_Spare3" 4 "IxbrOperStatus_Spare2" 3 "IxbrOperStatus_Spare1" 2 "IxbrOperStatus_OnReduced" 1 "IxbrOperStatus_OnOperational" 0 "IxbrOperStatus_Off" ;
VAL_ 602 IxbrSts1Veh_TscSts 7 "IxbrOperStatus_NotAvailable" 6 "IxbrOperStatus_Error" 5 "IxbrOperStatus_Spare3" 4 "IxbrOperStatus_Spare2" 3 "IxbrOperStatus_Spare1" 2 "IxbrOperStatus_OnReduced" 1 "IxbrOperStatus_OnOperational" 0 "IxbrOperStatus_Off" ;
VAL_ 602 IxbrSts1Veh_RscSts 7 "IxbrOperStatus_NotAvailable" 6 "IxbrOperStatus_Error" 5 "IxbrOperStatus_Spare3" 4 "IxbrOperStatus_Spare2" 3 "IxbrOperStatus_Spare1" 2 "IxbrOperStatus_OnReduced" 1 "IxbrOperStatus_OnOperational" 0 "IxbrOperStatus_Off" ;
VAL_ 298 Imu_LgtAccnQlty 3 "OperationalDegraded_NotAvailable" 2 "OperationalDegraded_Error" 1 "OperationalDegraded_Degraded" 0 "OperationalDegraded_Operational" ;
VAL_ 298 Imu_YawRateQlty 3 "OperationalDegraded_NotAvailable" 2 "OperationalDegraded_Error" 1 "OperationalDegraded_Degraded" 0 "OperationalDegraded_Operational" ;
VAL_ 298 Imu_PitchRateQlty 3 "OperationalDegraded_NotAvailable" 2 "OperationalDegraded_Error" 1 "OperationalDegraded_Degraded" 0 "OperationalDegraded_Operational" ;
VAL_ 298 Imu_RollRateQlty 3 "OperationalDegraded_NotAvailable" 2 "OperationalDegraded_Error" 1 "OperationalDegraded_Degraded" 0 "OperationalDegraded_Operational" ;
VAL_ 298 Imu_AccnLatQlty 3 "OperationalDegraded_NotAvailable" 2 "OperationalDegraded_Error" 1 "OperationalDegraded_Degraded" 0 "OperationalDegraded_Operational" ;
VAL_ 298 Imu_AccnVertQlty 3 "OperationalDegraded_NotAvailable" 2 "OperationalDegraded_Error" 1 "OperationalDegraded_Degraded" 0 "OperationalDegraded_Operational" ;
VAL_ 594 CpbtyAxle4_TqCpbtyRateQltyLe 3 "SignalQlty_NotAvailable" 2 "SignalQlty_Error" 1 "SignalQlty_Degraded" 0 "SignalQlty_Operational" ;
VAL_ 594 CpbtyAxle4_BrkEgyCpctyQltyRi 3 "SignalQlty_NotAvailable" 2 "SignalQlty_Error" 1 "SignalQlty_Degraded" 0 "SignalQlty_Operational" ;
VAL_ 594 CpbtyAxle5_TqCpbtyQltyLe 3 "SignalQlty_NotAvailable" 2 "SignalQlty_Error" 1 "SignalQlty_Degraded" 0 "SignalQlty_Operational" ;
VAL_ 594 CpbtyAxle6_TqCpbtyRateQltyLe 3 "SignalQlty_NotAvailable" 2 "SignalQlty_Error" 1 "SignalQlty_Degraded" 0 "SignalQlty_Operational" ;
VAL_ 594 CpbtyAxle6_TqCpbtyRateQltyRi 3 "SignalQlty_NotAvailable" 2 "SignalQlty_Error" 1 "SignalQlty_Degraded" 0 "SignalQlty_Operational" ;
VAL_ 594 CpbtyAxle5_SlipCtrlEna 3 "DisableEnable_NotAvailable" 2 "DisableEnable_Error" 1 "DisableEnable_Enable" 0 "DisableEnable_Disable" ;
VAL_ 594 CpbtyAxle5_PadWearQltyLe 3 "SignalQlty_NotAvailable" 2 "SignalQlty_Error" 1 "SignalQlty_Degraded" 0 "SignalQlty_Operational" ;
VAL_ 594 CpbtyAxle6_BrkEgyCpctyQltyRi 3 "SignalQlty_NotAvailable" 2 "SignalQlty_Error" 1 "SignalQlty_Degraded" 0 "SignalQlty_Operational" ;
VAL_ 594 CpbtyAxle5_BrkEgyCpctyQltyLe 3 "SignalQlty_NotAvailable" 2 "SignalQlty_Error" 1 "SignalQlty_Degraded" 0 "SignalQlty_Operational" ;
VAL_ 594 CpbtyAxle6_PadWearQltyRi 3 "SignalQlty_NotAvailable" 2 "SignalQlty_Error" 1 "SignalQlty_Degraded" 0 "SignalQlty_Operational" ;
VAL_ 594 CpbtyAxle4_TqCpbtyQltyLe 3 "SignalQlty_NotAvailable" 2 "SignalQlty_Error" 1 "SignalQlty_Degraded" 0 "SignalQlty_Operational" ;
VAL_ 594 CpbtyAxle4_SlipCtrlEna 3 "DisableEnable_NotAvailable" 2 "DisableEnable_Error" 1 "DisableEnable_Enable" 0 "DisableEnable_Disable" ;
VAL_ 594 CpbtyAxle6_TqCpbtyQltyRi 3 "SignalQlty_NotAvailable" 2 "SignalQlty_Error" 1 "SignalQlty_Degraded" 0 "SignalQlty_Operational" ;
VAL_ 594 CpbtyAxle5_TqCpbtyRateQltyLe 3 "SignalQlty_NotAvailable" 2 "SignalQlty_Error" 1 "SignalQlty_Degraded" 0 "SignalQlty_Operational" ;
VAL_ 594 CpbtyAxle6_PadWearQltyLe 3 "SignalQlty_NotAvailable" 2 "SignalQlty_Error" 1 "SignalQlty_Degraded" 0 "SignalQlty_Operational" ;
VAL_ 594 CpbtyAxle5_TqCpbtyRateQltyRi 3 "SignalQlty_NotAvailable" 2 "SignalQlty_Error" 1 "SignalQlty_Degraded" 0 "SignalQlty_Operational" ;
VAL_ 594 CpbtyAxle4_TqCpbtyQltyRi 3 "SignalQlty_NotAvailable" 2 "SignalQlty_Error" 1 "SignalQlty_Degraded" 0 "SignalQlty_Operational" ;
VAL_ 594 CpbtyAxle6_SlipCtrlEna 3 "DisableEnable_NotAvailable" 2 "DisableEnable_Error" 1 "DisableEnable_Enable" 0 "DisableEnable_Disable" ;
VAL_ 594 CpbtyAxle5_TqCpbtyQltyRi 3 "SignalQlty_NotAvailable" 2 "SignalQlty_Error" 1 "SignalQlty_Degraded" 0 "SignalQlty_Operational" ;
VAL_ 594 CpbtyAxle4_BrkEgyCpctyQltyLe 3 "SignalQlty_NotAvailable" 2 "SignalQlty_Error" 1 "SignalQlty_Degraded" 0 "SignalQlty_Operational" ;
VAL_ 594 CpbtyAxle4_TqCpbtyRateQltyRi 3 "SignalQlty_NotAvailable" 2 "SignalQlty_Error" 1 "SignalQlty_Degraded" 0 "SignalQlty_Operational" ;
VAL_ 594 CpbtyAxle5_PadWearQltyRi 3 "SignalQlty_NotAvailable" 2 "SignalQlty_Error" 1 "SignalQlty_Degraded" 0 "SignalQlty_Operational" ;
VAL_ 594 CpbtyAxle6_BrkEgyCpctyQltyLe 3 "SignalQlty_NotAvailable" 2 "SignalQlty_Error" 1 "SignalQlty_Degraded" 0 "SignalQlty_Operational" ;
VAL_ 594 CpbtyAxle6_TqCpbtyQltyLe 3 "SignalQlty_NotAvailable" 2 "SignalQlty_Error" 1 "SignalQlty_Degraded" 0 "SignalQlty_Operational" ;
VAL_ 594 CpbtyAxle5_BrkEgyCpctyQltyRi 3 "SignalQlty_NotAvailable" 2 "SignalQlty_Error" 1 "SignalQlty_Degraded" 0 "SignalQlty_Operational" ;
VAL_ 594 CpbtyAxle4_PadWearQltyRi 3 "SignalQlty_NotAvailable" 2 "SignalQlty_Error" 1 "SignalQlty_Degraded" 0 "SignalQlty_Operational" ;
VAL_ 594 CpbtyAxle4_PadWearQltyLe 3 "SignalQlty_NotAvailable" 2 "SignalQlty_Error" 1 "SignalQlty_Degraded" 0 "SignalQlty_Operational" ;
SIG_GROUP_ 275 SteeringWheelTorque_sg 1 : SteeringWheelTorque_SqC SteeringWheelTorque_CRC SteeringWheelTorque_Estimate;
SIG_GROUP_ 275 SteeringCtrlModeRsp_sg 1 : SteeringCtrlModeRsp_CRC SteeringCtrlModeRsp_Status SteeringCtrlModeRsp_SqC SteeringCtrlModeRsp_Cap SteeringCtrlModeRsp_Active;
SIG_GROUP_ 275 RoadWheelAngleResp_sg 1 : RoadWheelAngleResp_RateCap RoadWheelAngleResp_CRC RoadWheelAngleResp_Status RoadWheelAngleResp_MaxCap RoadWheelAngleResp_MinCap RoadWheelAngleResp_SqC;
SIG_GROUP_ 271 ZxbrStsVeh_sg 1 : ZxbrStsVeh_RetTar ZxbrStsVeh_RetEbiModSts ZxbrStsVeh_EbsCtrlModSts ZxbrStsVeh_RetSts ZxbrStsVeh_EbsHealthSts ZxbrStsVeh_SqC ZxbrStsVeh_RetModSts ZxbrStsVeh_DrvrModSts ZxbrStsVeh_RetCpbty ZxbrStsVeh_CRC;
SIG_GROUP_ 304 Sts2Axle3_sg 1 : Sts2Axle3_SqC Sts2Axle3_BrkTqReqRefLe Sts2Axle3_WhlTqQltyLe Sts2Axle3_BrkTqReqRefRi Sts2Axle3_CRC Sts2Axle3_WhlTqLe Sts2Axle3_WhlTqRi Sts2Axle3_WhlTqQltyRi;
SIG_GROUP_ 304 Sts2Axle5_sg 1 : Sts2Axle5_BrkTqReqRefLe Sts2Axle5_WhlTqQltyRi Sts2Axle5_SqC Sts2Axle5_WhlTqRi Sts2Axle5_WhlTqLe Sts2Axle5_WhlTqQltyLe Sts2Axle5_CRC Sts2Axle5_BrkTqReqRefRi;
SIG_GROUP_ 304 Sts2Axle2_sg 1 : Sts2Axle2_WhlTqRi Sts2Axle2_WhlTqQltyRi Sts2Axle2_WhlTqQltyLe Sts2Axle2_SqC Sts2Axle2_WhlTqLe Sts2Axle2_BrkTqReqRefLe Sts2Axle2_BrkTqReqRefRi Sts2Axle2_CRC;
SIG_GROUP_ 304 Sts2Axle6_sg 1 : Sts2Axle6_WhlTqRi Sts2Axle6_SqC Sts2Axle6_CRC Sts2Axle6_WhlTqQltyLe Sts2Axle6_BrkTqReqRefRi Sts2Axle6_WhlTqQltyRi Sts2Axle6_WhlTqLe Sts2Axle6_BrkTqReqRefLe;
SIG_GROUP_ 304 Sts2Axle1_sg 1 : Sts2Axle1_SqC Sts2Axle1_BrkTqReqRefLe Sts2Axle1_WhlTqQltyRi Sts2Axle1_WhlTqLe Sts2Axle1_WhlTqRi Sts2Axle1_BrkTqReqRefRi Sts2Axle1_WhlTqQltyLe Sts2Axle1_CRC;
SIG_GROUP_ 304 Sts2Axle4_sg 1 : Sts2Axle4_WhlTqQltyLe Sts2Axle4_BrkTqReqRefLe Sts2Axle4_CRC Sts2Axle4_SqC Sts2Axle4_WhlTqQltyRi Sts2Axle4_BrkTqReqRefRi Sts2Axle4_WhlTqRi Sts2Axle4_WhlTqLe;
SIG_GROUP_ 288 Sts1Axle3_sg 1 : Sts1Axle3_CRC Sts1Axle3_WhlRotAgCntrLe Sts1Axle3_WhlRotQltyLe Sts1Axle3_SqC Sts1Axle3_WhlRotAgCntrRi Sts1Axle3_WhlRotQltyRi Sts1Axle3_WhlRotSpdLe Sts1Axle3_WhlRotSpdRi;
SIG_GROUP_ 288 Sts1Axle4_sg 1 : Sts1Axle4_WhlRotSpdLe Sts1Axle4_WhlRotAgCntrLe Sts1Axle4_SqC Sts1Axle4_WhlRotQltyRi Sts1Axle4_CRC Sts1Axle4_WhlRotSpdRi Sts1Axle4_WhlRotQltyLe Sts1Axle4_WhlRotAgCntrRi;
SIG_GROUP_ 288 Sts1Axle5_sg 1 : Sts1Axle5_CRC Sts1Axle5_WhlRotAgCntrRi Sts1Axle5_WhlRotAgCntrLe Sts1Axle5_SqC Sts1Axle5_WhlRotQltyLe Sts1Axle5_WhlRotQltyRi Sts1Axle5_WhlRotSpdRi Sts1Axle5_WhlRotSpdLe;
SIG_GROUP_ 288 Sts1Axle1_sg 1 : Sts1Axle1_WhlRotSpdRi Sts1Axle1_WhlRotQltyRi Sts1Axle1_SqC Sts1Axle1_WhlRotQltyLe Sts1Axle1_WhlRotAgCntrLe Sts1Axle1_CRC Sts1Axle1_WhlRotSpdLe Sts1Axle1_WhlRotAgCntrRi;
SIG_GROUP_ 288 Sts1Axle6_sg 1 : Sts1Axle6_WhlRotQltyLe Sts1Axle6_CRC Sts1Axle6_WhlRotSpdRi Sts1Axle6_WhlRotAgCntrLe Sts1Axle6_WhlRotAgCntrRi Sts1Axle6_WhlRotSpdLe Sts1Axle6_WhlRotQltyRi Sts1Axle6_SqC;
SIG_GROUP_ 288 Sts1Axle2_sg 1 : Sts1Axle2_WhlRotQltyRi Sts1Axle2_WhlRotSpdRi Sts1Axle2_CRC Sts1Axle2_WhlRotSpdLe Sts1Axle2_WhlRotAgCntrRi Sts1Axle2_WhlRotAgCntrLe Sts1Axle2_WhlRotQltyLe Sts1Axle2_SqC;
SIG_GROUP_ 602 IxbrSts1Veh_sg 1 : IxbrSts1Veh_AbsSts IxbrSts1Veh_IxbrModSts IxbrSts1Veh_VehSpdLimRsc IxbrSts1Veh_VehSpdLgt IxbrSts1Veh_EscSts IxbrSts1Veh_TscSts IxbrSts1Veh_CRC IxbrSts1Veh_SqC IxbrSts1Veh_RscSts;
SIG_GROUP_ 602 IxbrSts2Veh_sg 1 : IxbrSts2Veh_CRC IxbrSts2Veh_SqC IxbrSts2Veh_YawRateRefEsc IxbrSts2Veh_VehAccnLatLimNeg IxbrSts2Veh_YawRateOffsLim IxbrSts2Veh_VehAccnLatLimPos;
SIG_GROUP_ 598 IxbrSts1Ax6_sg 1 : IxbrSts1Ax6_CRC IxbrSts1Ax6_SqC IxbrSts1Ax6_WhlRdEstmdLe IxbrSts1Ax6_WhlRdEstmdRi;
SIG_GROUP_ 598 IxbrSts1Ax4_sg 1 : IxbrSts1Ax4_WhlRdEstmdLe IxbrSts1Ax4_SqC IxbrSts1Ax4_WhlRdEstmdRi IxbrSts1Ax4_CRC;
SIG_GROUP_ 598 IxbrSts3Ax5_sg 1 : IxbrSts3Ax5_WhlAccnLgtLimMinLe IxbrSts3Ax5_CRC IxbrSts3Ax5_SqC IxbrSts3Ax5_WhlAccnLgtLimMinRi IxbrSts3Ax5_WhlAccnLgtLimMaxRi IxbrSts3Ax5_WhlAccnLgtLimMaxLe;
SIG_GROUP_ 598 IxbrSts3Ax6_sg 1 : IxbrSts3Ax6_WhlAccnLgtLimMaxRi IxbrSts3Ax6_CRC IxbrSts3Ax6_SqC IxbrSts3Ax6_WhlAccnLgtLimMinLe IxbrSts3Ax6_WhlAccnLgtLimMinRi IxbrSts3Ax6_WhlAccnLgtLimMaxLe;
SIG_GROUP_ 598 IxbrSts2Ax5_sg 1 : IxbrSts2Ax5_WhlSlipLimBrkngLe IxbrSts2Ax5_SqC IxbrSts2Ax5_WhlSlipLimBrkngRi IxbrSts2Ax5_WhlSlipLimPrpnRi IxbrSts2Ax5_CRC IxbrSts2Ax5_WhlSlipLimPrpnLe;
SIG_GROUP_ 598 IxbrSts2Ax4_sg 1 : IxbrSts2Ax4_SqC IxbrSts2Ax4_WhlSlipLimBrkngRi IxbrSts2Ax4_WhlSlipLimBrkngLe IxbrSts2Ax4_CRC IxbrSts2Ax4_WhlSlipLimPrpnRi IxbrSts2Ax4_WhlSlipLimPrpnLe;
SIG_GROUP_ 598 IxbrSts3Ax4_sg 1 : IxbrSts3Ax4_CRC IxbrSts3Ax4_WhlAccnLgtLimMinLe IxbrSts3Ax4_WhlAccnLgtLimMinRi IxbrSts3Ax4_SqC IxbrSts3Ax4_WhlAccnLgtLimMaxLe IxbrSts3Ax4_WhlAccnLgtLimMaxRi;
SIG_GROUP_ 598 IxbrSts1Ax5_sg 1 : IxbrSts1Ax5_CRC IxbrSts1Ax5_SqC IxbrSts1Ax5_WhlRdEstmdLe IxbrSts1Ax5_WhlRdEstmdRi;
SIG_GROUP_ 598 IxbrSts2Ax6_sg 1 : IxbrSts2Ax6_WhlSlipLimPrpnRi IxbrSts2Ax6_WhlSlipLimBrkngLe IxbrSts2Ax6_WhlSlipLimBrkngRi IxbrSts2Ax6_CRC IxbrSts2Ax6_WhlSlipLimPrpnLe IxbrSts2Ax6_SqC;
SIG_GROUP_ 596 IxbrSts1Ax1_sg 1 : IxbrSts1Ax1_WhlRdEstmdRi IxbrSts1Ax1_SqC IxbrSts1Ax1_CRC IxbrSts1Ax1_WhlRdEstmdLe;
SIG_GROUP_ 596 IxbrSts3Ax3_sg 1 : IxbrSts3Ax3_WhlAccnLgtLimMaxLe IxbrSts3Ax3_CRC IxbrSts3Ax3_WhlAccnLgtLimMinLe IxbrSts3Ax3_SqC IxbrSts3Ax3_WhlAccnLgtLimMinRi IxbrSts3Ax3_WhlAccnLgtLimMaxRi;
SIG_GROUP_ 596 IxbrSts3Ax1_sg 1 : IxbrSts3Ax1_WhlAccnLgtLimMinRi IxbrSts3Ax1_CRC IxbrSts3Ax1_WhlAccnLgtLimMinLe IxbrSts3Ax1_WhlAccnLgtLimMaxLe IxbrSts3Ax1_SqC IxbrSts3Ax1_WhlAccnLgtLimMaxRi;
SIG_GROUP_ 596 IxbrSts3Ax2_sg 1 : IxbrSts3Ax2_WhlAccnLgtLimMaxRi IxbrSts3Ax2_WhlAccnLgtLimMinLe IxbrSts3Ax2_SqC IxbrSts3Ax2_WhlAccnLgtLimMinRi IxbrSts3Ax2_CRC IxbrSts3Ax2_WhlAccnLgtLimMaxLe;
SIG_GROUP_ 596 IxbrSts2Ax3_sg 1 : IxbrSts2Ax3_WhlSlipLimBrkngRi IxbrSts2Ax3_WhlSlipLimPrpnRi IxbrSts2Ax3_CRC IxbrSts2Ax3_SqC IxbrSts2Ax3_WhlSlipLimBrkngLe IxbrSts2Ax3_WhlSlipLimPrpnLe;
SIG_GROUP_ 596 IxbrSts2Ax2_sg 1 : IxbrSts2Ax2_CRC IxbrSts2Ax2_WhlSlipLimBrkngRi IxbrSts2Ax2_WhlSlipLimBrkngLe IxbrSts2Ax2_WhlSlipLimPrpnLe IxbrSts2Ax2_SqC IxbrSts2Ax2_WhlSlipLimPrpnRi;
SIG_GROUP_ 596 IxbrSts2Ax1_sg 1 : IxbrSts2Ax1_WhlSlipLimPrpnLe IxbrSts2Ax1_WhlSlipLimPrpnRi IxbrSts2Ax1_WhlSlipLimBrkngLe IxbrSts2Ax1_SqC IxbrSts2Ax1_CRC IxbrSts2Ax1_WhlSlipLimBrkngRi;
SIG_GROUP_ 596 IxbrSts1Ax3_sg 1 : IxbrSts1Ax3_SqC IxbrSts1Ax3_WhlRdEstmdLe IxbrSts1Ax3_CRC IxbrSts1Ax3_WhlRdEstmdRi;
SIG_GROUP_ 596 IxbrSts1Ax2_sg 1 : IxbrSts1Ax2_WhlRdEstmdLe IxbrSts1Ax2_CRC IxbrSts1Ax2_WhlRdEstmdRi IxbrSts1Ax2_SqC;
SIG_GROUP_ 298 Imu_sg 1 : Imu_LgtAccnQlty Imu_AccnLat Imu_PitchRate Imu_YawRate Imu_Temp Imu_RollRate Imu_YawRateQlty Imu_PitchRateQlty Imu_RollRateQlty Imu_LgtAccn Imu_SqC Imu_CRC Imu_AccnLatQlty Imu_AccnVertQlty Imu_AccnVert;
SIG_GROUP_ 594 CpbtyAxle5_sg 1 : CpbtyAxle5_BrkEgyCpctyLe CpbtyAxle5_TqCpbtyMaxLe CpbtyAxle5_TqCpbtyQltyLe CpbtyAxle5_PadWearRi CpbtyAxle5_TqCpbtyRateIncLeRi CpbtyAxle5_TqCpbtyRateDecLe CpbtyAxle5_TqCpbtyMaxRi CpbtyAxle5_CRC CpbtyAxle5_SlipCtrlEna CpbtyAxle5_PadWearQltyLe CpbtyAxle5_BrkEgyCpctyQltyLe CpbtyAxle5_TqCpbtyRateQltyLe CpbtyAxle5_TqCpbtyMinLe CpbtyAxle5_TqCpbtyRateQltyRi CpbtyAxle5_TqCpbtyQltyRi CpbtyAxle5_TqCpbtyMinRi CpbtyAxle5_TqCpbtyRateIncLeLe CpbtyAxle5_PadWearQltyRi CpbtyAxle5_TqCpbtyRateDecRi CpbtyAxle5_SqC CpbtyAxle5_BrkEgyCpctyRi CpbtyAxle5_BrkEgyCpctyQltyRi CpbtyAxle5_PadWearLe;
SIG_GROUP_ 594 CpbtyAxle4_sg 1 : CpbtyAxle4_TqCpbtyRateQltyLe CpbtyAxle4_TqCpbtyRateDecRi CpbtyAxle4_BrkEgyCpctyQltyRi CpbtyAxle4_TqCpbtyMinRi CpbtyAxle4_TqCpbtyQltyLe CpbtyAxle4_SlipCtrlEna CpbtyAxle4_BrkEgyCpctyRi CpbtyAxle4_TqCpbtyMaxLe CpbtyAxle4_PadWearRi CpbtyAxle4_CRC CpbtyAxle4_SqC CpbtyAxle4_TqCpbtyQltyRi CpbtyAxle4_BrkEgyCpctyQltyLe CpbtyAxle4_TqCpbtyMinLe CpbtyAxle4_TqCpbtyRateDecLe CpbtyAxle4_TqCpbtyRateQltyRi CpbtyAxle4_BrkEgyCpctyLe CpbtyAxle4_TqCpbtyMaxRi CpbtyAxle4_TqCpbtyRateIncLeRi CpbtyAxle4_PadWearLe CpbtyAxle4_PadWearQltyRi CpbtyAxle4_TqCpbtyRateIncLeLe CpbtyAxle4_PadWearQltyLe;
SIG_GROUP_ 594 CpbtyAxle6_sg 1 : CpbtyAxle6_TqCpbtyRateQltyLe CpbtyAxle6_TqCpbtyMinRi CpbtyAxle6_BrkEgyCpctyRi CpbtyAxle6_TqCpbtyRateQltyRi CpbtyAxle6_TqCpbtyRateIncLeRi CpbtyAxle6_TqCpbtyRateDecLe CpbtyAxle6_BrkEgyCpctyQltyRi CpbtyAxle6_PadWearQltyRi CpbtyAxle6_TqCpbtyMaxRi CpbtyAxle6_TqCpbtyQltyRi CpbtyAxle6_CRC CpbtyAxle6_TqCpbtyMinLe CpbtyAxle6_PadWearQltyLe CpbtyAxle6_PadWearRi CpbtyAxle6_SlipCtrlEna CpbtyAxle6_SqC CpbtyAxle6_TqCpbtyRateDecRi CpbtyAxle6_TqCpbtyRateIncLeLe CpbtyAxle6_TqCpbtyMaxLe CpbtyAxle6_BrkEgyCpctyQltyLe CpbtyAxle6_TqCpbtyQltyLe CpbtyAxle6_BrkEgyCpctyLe CpbtyAxle6_PadWearLe;
